[part 8 of 10: packages /System to /SoftwareComponents/CompositionSWComponents]
AUTOSAR XML (schema 00053)
package /System  (continued)
  system System  (continued)
    system mapping System_MPPNG  (continued)
      data-mappings:  (continued)
        sender-receiver-to-signal-group-mapping={data-element=Pp_SG_RadarHeader_ALPCAN.Vdp_SG_RadarHeader_ALPCAN, signal-group=SG_RadarHeader, type-mapping=sender-rec-record-type-mapping=record-element-mappings=[{application-record-element=HED_ALIGN_HOR_REF, system-signal=HED_ALIGN_HOR_REF}, {application-record-element=HED_ALIGN_VER_REF, system-signal=HED_ALIGN_VER_REF}, {application-record-element=HED_Auth_CRC32, system-signal=HED_Auth_CRC32}, {application-record-element=HED_DATA_QUALIFIER, system-signal=HED_DATA_QUALIFIER}, {application-record-element=HED_DET_BI_STATIC_COUNT, system-signal=HED_DET_BI_STATIC_COUNT}, {application-record-element=HED_DET_NUM_OF_1PASS, system-signal=HED_DET_NUM_OF_1PASS}, {application-record-element=HED_DET_NUM_OF_2PASS, system-signal=HED_DET_NUM_OF_2PASS}, {application-record-element=HED_DET_RANGE_MAX, system-signal=HED_DET_RANGE_MAX}, {application-record-element=HED_DET_RANGE_MIN, system-signal=HED_DET_RANGE_MIN}, {application-record-element=HED_DET_SPEED_RANGE_MAX, system-signal=HED_DET_SPEED_RANGE_MAX}, {application-record-element=HED_DET_SPEED_RANGE_MIN, system-signal=HED_DET_SPEED_RANGE_MIN}, {application-record-element=HED_FOV_HOR_MAX, system-signal=HED_FOV_HOR_MAX}, {application-record-element=HED_FOV_HOR_MIN, system-signal=HED_FOV_HOR_MIN}, {application-record-element=HED_FOV_VER_MAX, system-signal=HED_FOV_VER_MAX}, {application-record-element=HED_FOV_VER_MIN, system-signal=HED_FOV_VER_MIN}, {application-record-element=HED_LOOK_ID, system-signal=HED_LOOK_ID}, {application-record-element=HED_LOOK_INDEX, system-signal=HED_LOOK_INDEX}, {application-record-element=HED_MAX_NUM_OF_DETECTIONS, system-signal=HED_MAX_NUM_OF_DETECTIONS}, {application-record-element=HED_MH_CRC16, system-signal=HED_MH_CRC16}, {application-record-element=HED_MH_CYCLE_COUNTER, system-signal=HED_MH_CYCLE_COUNTER}, {application-record-element=HED_NUM_OF_RESTBINS_USED, system-signal=HED_NUM_OF_RESTBINS_USED}, {application-record-element=HED_NUM_OF_VALID_DETECTIONS, system-signal=HED_NUM_OF_VALID_DETECTIONS}, {application-record-element=HED_OPERATION_MODE, system-signal=HED_OPERATION_MODE}, {application-record-element=HED_PROCESSED_RANGE, system-signal=HED_PROCESSED_RANGE}, {application-record-element=HED_RDR_HEADER_CMAC, system-signal=HED_RDR_HEADER_CMAC}, {application-record-element=HED_RDR_HEADER_FV, system-signal=HED_RDR_HEADER_FV}, {application-record-element=HED_R_WRAPPING, system-signal=HED_R_WRAPPING}, {application-record-element=HED_Rain_Level, system-signal=HED_Rain_Level}, {application-record-element=HED_SCAN_INDEX, system-signal=HED_SCAN_INDEX}, {application-record-element=HED_SENSOR_TIME_STAMP_NS, system-signal=HED_SENSOR_TIME_STAMP_NS}, {application-record-element=HED_SENSOR_TIME_STAMP_SEC, system-signal=HED_SENSOR_TIME_STAMP_SEC}, {application-record-element=HED_SLOPE_CORR_EXECUTIONFLAG, system-signal=HED_SLOPE_CORR_EXECUTIONFLAG}, {application-record-element=HED_TIME_SYNC_SRC_MASTER, system-signal=HED_TIME_SYNC_SRC_MASTER}, {application-record-element=HED_TIME_SYNC_VALIDITY_FLAG, system-signal=HED_TIME_SYNC_VALIDITY_FLAG}, {application-record-element=HED_TRIGGER_TIME, system-signal=HED_TRIGGER_TIME}, {application-record-element=HED_V_WRAPPING, system-signal=HED_V_WRAPPING}]}
        sender-receiver-to-signal-group-mapping={data-element=Pp_SG_RadarStatus1_ALPCAN.Vdp_SG_RadarStatus1_ALPCAN, signal-group=SG_RadarStatus1, type-mapping=sender-rec-record-type-mapping=record-element-mappings=[{application-record-element=STS_AF_TIME_INST, system-signal=STS_AF_TIME_INST}, {application-record-element=STS_AF_TIME_PEAK, system-signal=STS_AF_TIME_PEAK}, {application-record-element=STS_DET_DBC_BASE_VER_MAJOR, system-signal=STS_DET_DBC_BASE_VER_MAJOR}, {application-record-element=STS_DET_DBC_BASE_VER_MINOR, system-signal=STS_DET_DBC_BASE_VER_MINOR}, {application-record-element=STS_DIST_FRNT_BMPR_TO_RR_AXL, system-signal=STS_DIST_FRNT_BMPR_TO_RR_AXL}, {application-record-element=STS_HARDWARE_VERSION, system-signal=STS_HARDWARE_VERSION}, {application-record-element=STS_MAIN_CORE_TIME_INST, system-signal=STS_MAIN_CORE_TIME_INST}, {application-record-element=STS_MAIN_CORE_TIME_PEAK, system-signal=STS_MAIN_CORE_TIME_PEAK}, {application-record-element=STS_MH_001_CRC16, system-signal=STS_MH_001_CRC16}, {application-record-element=STS_MH_001_CYCLE_COUNTER, system-signal=STS_MH_001_CYCLE_COUNTER}, {application-record-element=STS_PBL_VERSION_FIELD1, system-signal=STS_PBL_VERSION_FIELD1}, {application-record-element=STS_PBL_VERSION_FIELD2, system-signal=STS_PBL_VERSION_FIELD2}, {application-record-element=STS_PBL_VERSION_FIELD3, system-signal=STS_PBL_VERSION_FIELD3}, {application-record-element=STS_PBL_VERSION_FIELD4, system-signal=STS_PBL_VERSION_FIELD4}, {application-record-element=STS_PCAN_PROTOCOL_VER_MAJOR, system-signal=STS_PCAN_PROTOCOL_VER_MAJOR}, {application-record-element=STS_PCAN_PROTOCOL_VER_MINOR, system-signal=STS_PCAN_PROTOCOL_VER_MINOR}, {application-record-element=STS_PLATFORM_VARIANT, system-signal=STS_PLATFORM_VARIANT}, {application-record-element=STS_RDD_CORE_TIME_INST, system-signal=STS_RDD_CORE_TIME_INST}, {application-record-element=STS_RDD_CORE_TIME_PEAK, system-signal=STS_RDD_CORE_TIME_PEAK}, {application-record-element=STS_SENSOR_HEIGHT, system-signal=STS_SENSOR_HEIGHT}, {application-record-element=STS_SENSOR_MOUNT_ORNT_PITCH, system-signal=STS_SENSOR_MOUNT_ORNT_PITCH}, {application-record-element=STS_SENSOR_MOUNT_ORNT_ROLL, system-signal=STS_SENSOR_MOUNT_ORNT_ROLL}, {application-record-element=STS_SENSOR_MOUNT_ORNT_YAW, system-signal=STS_SENSOR_MOUNT_ORNT_YAW}, {application-record-element=STS_SENSOR_MOUNT_POS_X, system-signal=STS_SENSOR_MOUNT_POS_X}, {application-record-element=STS_SENSOR_MOUNT_POS_Y, system-signal=STS_SENSOR_MOUNT_POS_Y}, {application-record-element=STS_SENSOR_MOUNT_POS_Z, system-signal=STS_SENSOR_MOUNT_POS_Z}, {application-record-element=STS_SENSOR_POLARITY, system-signal=STS_SENSOR_POLARITY}, {application-record-element=STS_SENSOR_POSITION, system-signal=STS_SENSOR_POSITION}, {application-record-element=STS_SERIAL_NUMBER_SEQUENCE, system-signal=STS_SERIAL_NUMBER_SEQUENCE}, {application-record-element=STS_SERIAL_NUM_JULIAN_DAY, system-signal=STS_SERIAL_NUM_JULIAN_DAY}, {application-record-element=STS_SERIAL_NUM_JULIAN_YEAR, system-signal=STS_SERIAL_NUM_JULIAN_YEAR}, {application-record-element=STS_SMC_CAL_VER_MAJOR, system-signal=STS_SMC_CAL_VER_MAJOR}, {application-record-element=STS_SMC_CAL_VER_MINOR, system-signal=STS_SMC_CAL_VER_MINOR}, {application-record-element=STS_SMC_PLATFROM_VERSION, system-signal=STS_SMC_PLATFROM_VERSION}, {application-record-element=STS_SMC_SECTION_COMPTBLITY, system-signal=STS_SMC_SECTION_COMPTBLITY}, {application-record-element=STS_SP_CORE_TIME_INST, system-signal=STS_SP_CORE_TIME_INST}, {application-record-element=STS_SP_CORE_TIME_PEAK, system-signal=STS_SP_CORE_TIME_PEAK}, {application-record-element=STS_SW_VERSION_FIELD1, system-signal=STS_SW_VERSION_FIELD1}, {application-record-element=STS_SW_VERSION_FIELD2, system-signal=STS_SW_VERSION_FIELD2}, {application-record-element=STS_SW_VERSION_FIELD3, system-signal=STS_SW_VERSION_FIELD3}, {application-record-element=STS_SW_VERSION_FIELD4, system-signal=STS_SW_VERSION_FIELD4}, {application-record-element=STS_TIME_SINCE_POWER_ON, system-signal=STS_TIME_SINCE_POWER_ON}, {application-record-element=STS_USC_CAL_VER_MAJOR, system-signal=STS_USC_CAL_VER_MAJOR}, {application-record-element=STS_USC_CAL_VER_MINOR, system-signal=STS_USC_CAL_VER_MINOR}, {application-record-element=STS_USC_SECTION_COMPTBLITY, system-signal=STS_USC_SECTION_COMPTBLITY}, {application-record-element=STS_VIN_Status, system-signal=STS_VIN_Status}]}
      sw-mappings:
        swc to ecu mapping ECUMapping2: component=RootComposition, ecu-instance=RDR
    root-software-compositions:
      root sw composition prototype RootComposition: software-composition=ECU_Composition
package /SoftwareComponents/CompositionSWComponents
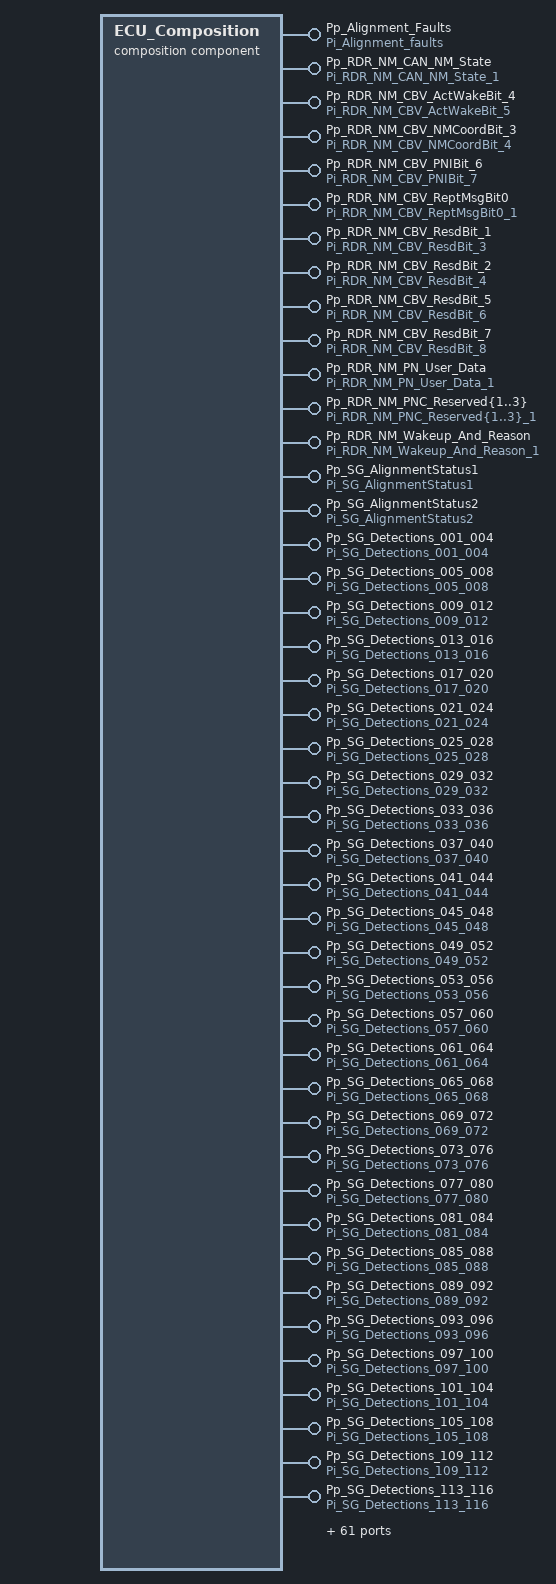
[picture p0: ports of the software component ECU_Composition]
  composition sw component type ECU_Composition
    189 x provide port:
      Pp_Alignment_Faults: nonqueued-sender-com-spec{data-element=De_Alignment_Faults, init-value=constant-reference=C_Alignment_faults}, provided-interface=Pi_Alignment_faults
      Pp_RDR_NM_CAN_NM_State: nonqueued-sender-com-spec{data-element=Vdp_RDR_NM_CAN_NM_State, init-value=0}, provided-interface=Pi_RDR_NM_CAN_NM_State_1
      Pp_RDR_NM_CBV_ActWakeBit_4: nonqueued-sender-com-spec{data-element=Vdp_RDR_NM_CBV_ActWakeBit_4, init-value=0}, provided-interface=Pi_RDR_NM_CBV_ActWakeBit_5
      Pp_RDR_NM_CBV_NMCoordBit_3: nonqueued-sender-com-spec{data-element=Vdp_RDR_NM_CBV_NMCoordBit_3, init-value=0}, provided-interface=Pi_RDR_NM_CBV_NMCoordBit_4
      Pp_RDR_NM_CBV_PNIBit_6: nonqueued-sender-com-spec{data-element=Vdp_RDR_NM_CBV_PNIBit_6, init-value=0}, provided-interface=Pi_RDR_NM_CBV_PNIBit_7
      Pp_RDR_NM_CBV_ReptMsgBit0: nonqueued-sender-com-spec{data-element=Vdp_RDR_NM_CBV_ReptMsgBit0, init-value=0}, provided-interface=Pi_RDR_NM_CBV_ReptMsgBit0_1
      Pp_RDR_NM_CBV_ResdBit_1: nonqueued-sender-com-spec{data-element=Vdp_RDR_NM_CBV_ResdBit_1, init-value=0}, provided-interface=Pi_RDR_NM_CBV_ResdBit_3
      Pp_RDR_NM_CBV_ResdBit_2: nonqueued-sender-com-spec{data-element=Vdp_RDR_NM_CBV_ResdBit_2, init-value=0}, provided-interface=Pi_RDR_NM_CBV_ResdBit_4
      Pp_RDR_NM_CBV_ResdBit_5: nonqueued-sender-com-spec{data-element=Vdp_RDR_NM_CBV_ResdBit_5, init-value=0}, provided-interface=Pi_RDR_NM_CBV_ResdBit_6
      Pp_RDR_NM_CBV_ResdBit_7: nonqueued-sender-com-spec{data-element=Vdp_RDR_NM_CBV_ResdBit_7, init-value=0}, provided-interface=Pi_RDR_NM_CBV_ResdBit_8
      Pp_RDR_NM_PN_User_Data: nonqueued-sender-com-spec{data-element=Vdp_RDR_NM_PN_User_Data, init-value=0}, provided-interface=Pi_RDR_NM_PN_User_Data_1
      Pp_RDR_NM_PNC_Reserved{1..3}: nonqueued-sender-com-spec{data-element=Vdp_RDR_NM_PNC_Reserved{1..3}, init-value=0}, provided-interface=Pi_RDR_NM_PNC_Reserved{1..3}_1
      Pp_RDR_NM_Wakeup_And_Reason: nonqueued-sender-com-spec{data-element=Vdp_RDR_NM_Wakeup_And_Reason, init-value=0}, provided-interface=Pi_RDR_NM_Wakeup_And_Reason_1
      Pp_SG_AlignmentStatus1: nonqueued-sender-com-spec{data-element=Vdp_SG_AlignmentStatus1, init-value=fields=[AL_STS_001_CYCLE_COUNTER:0, AL_STS_001_MH_CRC16:0, STS_AAAzimuthStd:0, STS_AACurrentAzimuth:0, STS_AACurrentElevation:0, STS_AAElevationStd:0, STS_AlignmentAutoStatus:0, STS_AlignmentAzimuth:0, STS_AlignmentElevation:0, STS_AlignmentError:0, STS_AlignmentModeIn:0, STS_AlignmentModeOut:0, STS_AutoAlignmentFailRootCause:5, STS_AzimuthErrorNegative:0, STS_AzimuthErrorPositive:0, STS_AzimuthStd:0, STS_AzimuthUpdates:0, STS_CalDisplay:0, STS_CalTime:0, STS_CoordinateSystemInput:0, STS_ElevationErrorNegative:0, STS_ElevationErrorPositive:0, STS_ElevationStd:0, STS_ElevationUpdates:0, STS_HostSpdCompensationFactorQF:0, STS_HostSpeedCompensationFactor:100, 0, 0, 0, 0, 100, 0, STS_ProgressPercent:0, STS_RadarTypeInput:0, STS_RollErrorPositive:0, STS_StartAzimuth:0, STS_StartElevation:0]}, provided-interface=Pi_SG_AlignmentStatus1
      Pp_SG_AlignmentStatus2: nonqueued-sender-com-spec{data-element=Vdp_SG_AlignmentStatus2, init-value=fields=[AL_STS_002_CYCLE_COUNTER:0, AL_STS_002_MH_CRC16:0, STS_AlignmentServiceStatus:0, STS_AlignmentShortTrackStatus:0, STS_AlignmentStaticStatus:0, STS_AverageNumberOfDetections:0, STS_AverageSpeed:0, STS_DistanceAbsolute:0, STS_DistanceEffective:0, STS_DurationAbsolute:0, STS_DurationEffective:0, STS_ImpactByInterference:0, STS_Measured_Range:1200, STS_MeasuredRangeRate:0, STS_MeasuredRangeRateStd:0, STS_MeasuredRangeStd:0, STS_MeasuredRCS:0, STS_MeasuredRCSStd:0, STS_VehicleCondition:6]}, provided-interface=Pi_SG_AlignmentStatus2
      Pp_SG_Detections_001_004: nonqueued-sender-com-spec{data-element=Vdp_SG_Detections_001_004, init-value=fields=[DET_AZIMUTH_001:0, DET_AZIMUTH_002:0, DET_AZIMUTH_003:0, DET_AZIMUTH_004:0, DET_AZIMUTH_ERR_001:0, DET_AZIMUTH_ERR_002:0, DET_AZIMUTH_ERR_003:0, DET_AZIMUTH_ERR_004:0, DET_BI_STATIC_FLAG_001:0, DET_BI_STATIC_FLAG_002:0, DET_BI_STATIC_FLAG_003:0, DET_BI_STATIC_FLAG_004:0, DET_CONFD_AZIMUTH_001:0, DET_CONFD_AZIMUTH_002:0, DET_CONFD_AZIMUTH_003:0, DET_CONFD_AZIMUTH_004:0, DET_CONFD_ELEVATION_001:0, DET_CONFD_ELEVATION_002:0, DET_CONFD_ELEVATION_003:0, DET_CONFD_ELEVATION_004:0, DET_ELEVATION_001:0, DET_ELEVATION_002:0, DET_ELEVATION_003:0, DET_ELEVATION_004:0, DET_ELEVATION_ERR_001:0, DET_ELEVATION_ERR_002:0, DET_ELEVATION_ERR_003:0, DET_ELEVATION_ERR_004:0, DET_EXISTENCE_PROB_001:0, DET_EXISTENCE_PROB_002:0, DET_EXISTENCE_PROB_003:0, DET_EXISTENCE_PROB_004:0, DET_HVC_FLAG_001:0, DET_HVC_FLAG_002:0, DET_HVC_FLAG_003:0, DET_HVC_FLAG_004:0, DET_MH_CRC16_001_004:0, DET_MH_CYCLE_COUNTER_001_004:0, DET_MH_SCAN_INDEX_4LSB_001_004:0, DET_OUTSIDE_SECTOR_001:0, DET_OUTSIDE_SECTOR_002:0, DET_OUTSIDE_SECTOR_003:0, DET_OUTSIDE_SECTOR_004:0, DET_POINT_TARGET_PROB_001:0, DET_POINT_TARGET_PROB_002:0, DET_POINT_TARGET_PROB_003:0, DET_POINT_TARGET_PROB_004:0, DET_RANGE_001:0, DET_RANGE_002:0, DET_RANGE_003:0, DET_RANGE_004:0, DET_RANGE_ERR_001:0, DET_RANGE_ERR_002:0, DET_RANGE_ERR_003:0, DET_RANGE_ERR_004:0, DET_RANGE_VELOCITY_001:16384, DET_RANGE_VELOCITY_002:16384, DET_RANGE_VELOCITY_003:16384, DET_RANGE_VELOCITY_004:16384, DET_RANGE_VELOCITY_ERR_001:0, DET_RANGE_VELOCITY_ERR_002:0, DET_RANGE_VELOCITY_ERR_003:0, DET_RANGE_VELOCITY_ERR_004:0, DET_RCS_001:128, DET_RCS_002:128, DET_RCS_003:128, DET_RCS_004:128, DET_SNR_001:0, DET_SNR_002:0, DET_SNR_003:0, DET_SNR_004:0, DET_SUPER_RES_TARGET_001:0, DET_SUPER_RES_TARGET_002:0, DET_SUPER_RES_TARGET_003:0, DET_SUPER_RES_TARGET_004:0, DET_VALID_FLAG_001:0, DET_VALID_FLAG_002:0, DET_VALID_FLAG_003:0, DET_VALID_FLAG_004:0]}, provided-interface=Pi_SG_Detections_001_004
      Pp_SG_Detections_005_008: nonqueued-sender-com-spec{data-element=Vdp_SG_Detections_005_008, init-value=fields=[DET_AZIMUTH_005:0, DET_AZIMUTH_006:0, DET_AZIMUTH_007:0, DET_AZIMUTH_008:0, DET_AZIMUTH_ERR_005:0, DET_AZIMUTH_ERR_006:0, DET_AZIMUTH_ERR_007:0, DET_AZIMUTH_ERR_008:0, DET_BI_STATIC_FLAG_005:0, DET_BI_STATIC_FLAG_006:0, DET_BI_STATIC_FLAG_007:0, DET_BI_STATIC_FLAG_008:0, DET_CONFD_AZIMUTH_005:0, DET_CONFD_AZIMUTH_006:0, DET_CONFD_AZIMUTH_007:0, DET_CONFD_AZIMUTH_008:0, DET_CONFD_ELEVATION_005:0, DET_CONFD_ELEVATION_006:0, DET_CONFD_ELEVATION_007:0, DET_CONFD_ELEVATION_008:0, DET_ELEVATION_005:0, DET_ELEVATION_006:0, DET_ELEVATION_007:0, DET_ELEVATION_008:0, DET_ELEVATION_ERR_005:0, DET_ELEVATION_ERR_006:0, DET_ELEVATION_ERR_007:0, DET_ELEVATION_ERR_008:0, DET_EXISTENCE_PROB_005:0, DET_EXISTENCE_PROB_006:0, DET_EXISTENCE_PROB_007:0, DET_EXISTENCE_PROB_008:0, DET_HVC_FLAG_005:0, DET_HVC_FLAG_006:0, DET_HVC_FLAG_007:0, DET_HVC_FLAG_008:0, DET_MH_CRC16_005_008:0, DET_MH_CYCLE_COUNTER_005_008:0, DET_MH_SCAN_INDEX_4LSB_005_008:0, DET_OUTSIDE_SECTOR_005:0, DET_OUTSIDE_SECTOR_006:0, DET_OUTSIDE_SECTOR_007:0, DET_OUTSIDE_SECTOR_008:0, DET_POINT_TARGET_PROB_005:0, DET_POINT_TARGET_PROB_006:0, DET_POINT_TARGET_PROB_007:0, DET_POINT_TARGET_PROB_008:0, DET_RANGE_005:0, DET_RANGE_006:0, DET_RANGE_007:0, DET_RANGE_008:0, DET_RANGE_ERR_005:0, DET_RANGE_ERR_006:0, DET_RANGE_ERR_007:0, DET_RANGE_ERR_008:0, DET_RANGE_VELOCITY_005:16384, DET_RANGE_VELOCITY_006:16384, DET_RANGE_VELOCITY_007:16384, DET_RANGE_VELOCITY_008:16384, DET_RANGE_VELOCITY_ERR_005:0, DET_RANGE_VELOCITY_ERR_006:0, DET_RANGE_VELOCITY_ERR_007:0, DET_RANGE_VELOCITY_ERR_008:0, DET_RCS_005:128, DET_RCS_006:128, DET_RCS_007:128, DET_RCS_008:128, DET_SNR_005:0, DET_SNR_006:0, DET_SNR_007:0, DET_SNR_008:0, DET_SUPER_RES_TARGET_005:0, DET_SUPER_RES_TARGET_006:0, DET_SUPER_RES_TARGET_007:0, DET_SUPER_RES_TARGET_008:0, DET_VALID_FLAG_005:0, DET_VALID_FLAG_006:0, DET_VALID_FLAG_007:0, DET_VALID_FLAG_008:0]}, provided-interface=Pi_SG_Detections_005_008
      Pp_SG_Detections_009_012: nonqueued-sender-com-spec{data-element=Vdp_SG_Detections_009_012, init-value=fields=[DET_AZIMUTH_009:0, DET_AZIMUTH_010:0, DET_AZIMUTH_011:0, DET_AZIMUTH_012:0, DET_AZIMUTH_ERR_009:0, DET_AZIMUTH_ERR_010:0, DET_AZIMUTH_ERR_011:0, DET_AZIMUTH_ERR_012:0, DET_BI_STATIC_FLAG_009:0, DET_BI_STATIC_FLAG_010:0, DET_BI_STATIC_FLAG_011:0, DET_BI_STATIC_FLAG_012:0, DET_CONFD_AZIMUTH_009:0, DET_CONFD_AZIMUTH_010:0, DET_CONFD_AZIMUTH_011:0, DET_CONFD_AZIMUTH_012:0, DET_CONFD_ELEVATION_009:0, DET_CONFD_ELEVATION_010:0, DET_CONFD_ELEVATION_011:0, DET_CONFD_ELEVATION_012:0, DET_ELEVATION_009:0, DET_ELEVATION_010:0, DET_ELEVATION_011:0, DET_ELEVATION_012:0, DET_ELEVATION_ERR_009:0, DET_ELEVATION_ERR_010:0, DET_ELEVATION_ERR_011:0, DET_ELEVATION_ERR_012:0, DET_EXISTENCE_PROB_009:0, DET_EXISTENCE_PROB_010:0, DET_EXISTENCE_PROB_011:0, DET_EXISTENCE_PROB_012:0, DET_HVC_FLAG_009:0, DET_HVC_FLAG_010:0, DET_HVC_FLAG_011:0, DET_HVC_FLAG_012:0, DET_MH_CRC16_009_012:0, DET_MH_CYCLE_COUNTER_009_012:0, DET_MH_SCAN_INDEX_4LSB_009_012:0, DET_OUTSIDE_SECTOR_009:0, DET_OUTSIDE_SECTOR_010:0, DET_OUTSIDE_SECTOR_011:0, DET_OUTSIDE_SECTOR_012:0, DET_POINT_TARGET_PROB_009:0, DET_POINT_TARGET_PROB_010:0, DET_POINT_TARGET_PROB_011:0, DET_POINT_TARGET_PROB_012:0, DET_RANGE_009:0, DET_RANGE_010:0, DET_RANGE_011:0, DET_RANGE_012:0, DET_RANGE_ERR_009:0, DET_RANGE_ERR_010:0, DET_RANGE_ERR_011:0, DET_RANGE_ERR_012:0, DET_RANGE_VELOCITY_009:16384, DET_RANGE_VELOCITY_010:16384, DET_RANGE_VELOCITY_011:16384, DET_RANGE_VELOCITY_012:16384, DET_RANGE_VELOCITY_ERR_009:0, DET_RANGE_VELOCITY_ERR_010:0, DET_RANGE_VELOCITY_ERR_011:0, DET_RANGE_VELOCITY_ERR_012:0, DET_RCS_009:128, DET_RCS_010:128, DET_RCS_011:128, DET_RCS_012:128, DET_SNR_009:0, DET_SNR_010:0, DET_SNR_011:0, DET_SNR_012:0, DET_SUPER_RES_TARGET_009:0, DET_SUPER_RES_TARGET_010:0, DET_SUPER_RES_TARGET_011:0, DET_SUPER_RES_TARGET_012:0, DET_VALID_FLAG_009:0, DET_VALID_FLAG_010:0, DET_VALID_FLAG_011:0, DET_VALID_FLAG_012:0]}, provided-interface=Pi_SG_Detections_009_012
      Pp_SG_Detections_013_016: nonqueued-sender-com-spec{data-element=Vdp_SG_Detections_013_016, init-value=fields=[DET_AZIMUTH_013:0, DET_AZIMUTH_014:0, DET_AZIMUTH_015:0, DET_AZIMUTH_016:0, DET_AZIMUTH_ERR_013:0, DET_AZIMUTH_ERR_014:0, DET_AZIMUTH_ERR_015:0, DET_AZIMUTH_ERR_016:0, DET_BI_STATIC_FLAG_013:0, DET_BI_STATIC_FLAG_014:0, DET_BI_STATIC_FLAG_015:0, DET_BI_STATIC_FLAG_016:0, DET_CONFD_AZIMUTH_013:0, DET_CONFD_AZIMUTH_014:0, DET_CONFD_AZIMUTH_015:0, DET_CONFD_AZIMUTH_016:0, DET_CONFD_ELEVATION_013:0, DET_CONFD_ELEVATION_014:0, DET_CONFD_ELEVATION_015:0, DET_CONFD_ELEVATION_016:0, DET_ELEVATION_013:0, DET_ELEVATION_014:0, DET_ELEVATION_015:0, DET_ELEVATION_016:0, DET_ELEVATION_ERR_013:0, DET_ELEVATION_ERR_014:0, DET_ELEVATION_ERR_015:0, DET_ELEVATION_ERR_016:0, DET_EXISTENCE_PROB_013:0, DET_EXISTENCE_PROB_014:0, DET_EXISTENCE_PROB_015:0, DET_EXISTENCE_PROB_016:0, DET_HVC_FLAG_013:0, DET_HVC_FLAG_014:0, DET_HVC_FLAG_015:0, DET_HVC_FLAG_016:0, DET_MH_CRC16_013_016:0, DET_MH_CYCLE_COUNTER_013_016:0, DET_MH_SCAN_INDEX_4LSB_013_016:0, DET_OUTSIDE_SECTOR_013:0, DET_OUTSIDE_SECTOR_014:0, DET_OUTSIDE_SECTOR_015:0, DET_OUTSIDE_SECTOR_016:0, DET_POINT_TARGET_PROB_013:0, DET_POINT_TARGET_PROB_014:0, DET_POINT_TARGET_PROB_015:0, DET_POINT_TARGET_PROB_016:0, DET_RANGE_013:0, DET_RANGE_014:0, DET_RANGE_015:0, DET_RANGE_016:0, DET_RANGE_ERR_013:0, DET_RANGE_ERR_014:0, DET_RANGE_ERR_015:0, DET_RANGE_ERR_016:0, DET_RANGE_VELOCITY_013:16384, DET_RANGE_VELOCITY_014:16384, DET_RANGE_VELOCITY_015:16384, DET_RANGE_VELOCITY_016:16384, DET_RANGE_VELOCITY_ERR_013:0, DET_RANGE_VELOCITY_ERR_014:0, DET_RANGE_VELOCITY_ERR_015:0, DET_RANGE_VELOCITY_ERR_016:0, DET_RCS_013:128, DET_RCS_014:128, DET_RCS_015:128, DET_RCS_016:128, DET_SNR_013:0, DET_SNR_014:0, DET_SNR_015:0, DET_SNR_016:0, DET_SUPER_RES_TARGET_013:0, DET_SUPER_RES_TARGET_014:0, DET_SUPER_RES_TARGET_015:0, DET_SUPER_RES_TARGET_016:0, DET_VALID_FLAG_013:0, DET_VALID_FLAG_014:0, DET_VALID_FLAG_015:0, DET_VALID_FLAG_016:0]}, provided-interface=Pi_SG_Detections_013_016
      Pp_SG_Detections_017_020: nonqueued-sender-com-spec{data-element=Vdp_SG_Detections_017_020, init-value=fields=[DET_AZIMUTH_017:0, DET_AZIMUTH_018:0, DET_AZIMUTH_019:0, DET_AZIMUTH_020:0, DET_AZIMUTH_ERR_017:0, DET_AZIMUTH_ERR_018:0, DET_AZIMUTH_ERR_019:0, DET_AZIMUTH_ERR_020:0, DET_BI_STATIC_FLAG_017:0, DET_BI_STATIC_FLAG_018:0, DET_BI_STATIC_FLAG_019:0, DET_BI_STATIC_FLAG_020:0, DET_CONFD_AZIMUTH_017:0, DET_CONFD_AZIMUTH_018:0, DET_CONFD_AZIMUTH_019:0, DET_CONFD_AZIMUTH_020:0, DET_CONFD_ELEVATION_017:0, DET_CONFD_ELEVATION_018:0, DET_CONFD_ELEVATION_019:0, DET_CONFD_ELEVATION_020:0, DET_ELEVATION_017:0, DET_ELEVATION_018:0, DET_ELEVATION_019:0, DET_ELEVATION_020:0, DET_ELEVATION_ERR_017:0, DET_ELEVATION_ERR_018:0, DET_ELEVATION_ERR_019:0, DET_ELEVATION_ERR_020:0, DET_EXISTENCE_PROB_017:0, DET_EXISTENCE_PROB_018:0, DET_EXISTENCE_PROB_019:0, DET_EXISTENCE_PROB_020:0, DET_HVC_FLAG_017:0, DET_HVC_FLAG_018:0, DET_HVC_FLAG_019:0, DET_HVC_FLAG_020:0, DET_MH_CRC16_017_020:0, DET_MH_CYCLE_COUNTER_017_020:0, DET_MH_SCAN_INDEX_4LSB_017_020:0, DET_OUTSIDE_SECTOR_017:0, DET_OUTSIDE_SECTOR_018:0, DET_OUTSIDE_SECTOR_019:0, DET_OUTSIDE_SECTOR_020:0, DET_POINT_TARGET_PROB_017:0, DET_POINT_TARGET_PROB_018:0, DET_POINT_TARGET_PROB_019:0, DET_POINT_TARGET_PROB_020:0, DET_RANGE_017:0, DET_RANGE_018:0, DET_RANGE_019:0, DET_RANGE_020:0, DET_RANGE_ERR_017:0, DET_RANGE_ERR_018:0, DET_RANGE_ERR_019:0, DET_RANGE_ERR_020:0, DET_RANGE_VELOCITY_017:16384, DET_RANGE_VELOCITY_018:16384, DET_RANGE_VELOCITY_019:16384, DET_RANGE_VELOCITY_020:16384, DET_RANGE_VELOCITY_ERR_017:0, DET_RANGE_VELOCITY_ERR_018:0, DET_RANGE_VELOCITY_ERR_019:0, DET_RANGE_VELOCITY_ERR_020:0, DET_RCS_017:128, DET_RCS_018:128, DET_RCS_019:128, DET_RCS_020:128, DET_SNR_017:0, DET_SNR_018:0, DET_SNR_019:0, DET_SNR_020:0, DET_SUPER_RES_TARGET_017:0, DET_SUPER_RES_TARGET_018:0, DET_SUPER_RES_TARGET_019:0, DET_SUPER_RES_TARGET_020:0, DET_VALID_FLAG_017:0, DET_VALID_FLAG_018:0, DET_VALID_FLAG_019:0, DET_VALID_FLAG_020:0]}, provided-interface=Pi_SG_Detections_017_020
      Pp_SG_Detections_021_024: nonqueued-sender-com-spec{data-element=Vdp_SG_Detections_021_024, init-value=fields=[DET_AZIMUTH_021:0, DET_AZIMUTH_022:0, DET_AZIMUTH_023:0, DET_AZIMUTH_024:0, DET_AZIMUTH_ERR_021:0, DET_AZIMUTH_ERR_022:0, DET_AZIMUTH_ERR_023:0, DET_AZIMUTH_ERR_024:0, DET_BI_STATIC_FLAG_021:0, DET_BI_STATIC_FLAG_022:0, DET_BI_STATIC_FLAG_023:0, DET_BI_STATIC_FLAG_024:0, DET_CONFD_AZIMUTH_021:0, DET_CONFD_AZIMUTH_022:0, DET_CONFD_AZIMUTH_023:0, DET_CONFD_AZIMUTH_024:0, DET_CONFD_ELEVATION_021:0, DET_CONFD_ELEVATION_022:0, DET_CONFD_ELEVATION_023:0, DET_CONFD_ELEVATION_024:0, DET_ELEVATION_021:0, DET_ELEVATION_022:0, DET_ELEVATION_023:0, DET_ELEVATION_024:0, DET_ELEVATION_ERR_021:0, DET_ELEVATION_ERR_022:0, DET_ELEVATION_ERR_023:0, DET_ELEVATION_ERR_024:0, DET_EXISTENCE_PROB_021:0, DET_EXISTENCE_PROB_022:0, DET_EXISTENCE_PROB_023:0, DET_EXISTENCE_PROB_024:0, DET_HVC_FLAG_021:0, DET_HVC_FLAG_022:0, DET_HVC_FLAG_023:0, DET_HVC_FLAG_024:0, DET_MH_CRC16_021_024:0, DET_MH_CYCLE_COUNTER_021_024:0, DET_MH_SCAN_INDEX_4LSB_021_024:0, DET_OUTSIDE_SECTOR_021:0, DET_OUTSIDE_SECTOR_022:0, DET_OUTSIDE_SECTOR_023:0, DET_OUTSIDE_SECTOR_024:0, DET_POINT_TARGET_PROB_021:0, DET_POINT_TARGET_PROB_022:0, DET_POINT_TARGET_PROB_023:0, DET_POINT_TARGET_PROB_024:0, DET_RANGE_021:0, DET_RANGE_022:0, DET_RANGE_023:0, DET_RANGE_024:0, DET_RANGE_ERR_021:0, DET_RANGE_ERR_022:0, DET_RANGE_ERR_023:0, DET_RANGE_ERR_024:0, DET_RANGE_VELOCITY_021:16384, DET_RANGE_VELOCITY_022:16384, DET_RANGE_VELOCITY_023:16384, DET_RANGE_VELOCITY_024:16384, DET_RANGE_VELOCITY_ERR_021:0, DET_RANGE_VELOCITY_ERR_022:0, DET_RANGE_VELOCITY_ERR_023:0, DET_RANGE_VELOCITY_ERR_024:0, DET_RCS_021:128, DET_RCS_022:128, DET_RCS_023:128, DET_RCS_024:128, DET_SNR_021:0, DET_SNR_022:0, DET_SNR_023:0, DET_SNR_024:0, DET_SUPER_RES_TARGET_021:0, DET_SUPER_RES_TARGET_022:0, DET_SUPER_RES_TARGET_023:0, DET_SUPER_RES_TARGET_024:0, DET_VALID_FLAG_021:0, DET_VALID_FLAG_022:0, DET_VALID_FLAG_023:0, DET_VALID_FLAG_024:0]}, provided-interface=Pi_SG_Detections_021_024
      Pp_SG_Detections_025_028: nonqueued-sender-com-spec{data-element=Vdp_SG_Detections_025_028, init-value=fields=[DET_AZIMUTH_025:0, DET_AZIMUTH_026:0, DET_AZIMUTH_027:0, DET_AZIMUTH_028:0, DET_AZIMUTH_ERR_025:0, DET_AZIMUTH_ERR_026:0, DET_AZIMUTH_ERR_027:0, DET_AZIMUTH_ERR_028:0, DET_BI_STATIC_FLAG_025:0, DET_BI_STATIC_FLAG_026:0, DET_BI_STATIC_FLAG_027:0, DET_BI_STATIC_FLAG_028:0, DET_CONFD_AZIMUTH_025:0, DET_CONFD_AZIMUTH_026:0, DET_CONFD_AZIMUTH_027:0, DET_CONFD_AZIMUTH_028:0, DET_CONFD_ELEVATION_025:0, DET_CONFD_ELEVATION_026:0, DET_CONFD_ELEVATION_027:0, DET_CONFD_ELEVATION_028:0, DET_ELEVATION_025:0, DET_ELEVATION_026:0, DET_ELEVATION_027:0, DET_ELEVATION_028:0, DET_ELEVATION_ERR_025:0, DET_ELEVATION_ERR_026:0, DET_ELEVATION_ERR_027:0, DET_ELEVATION_ERR_028:0, DET_EXISTENCE_PROB_025:0, DET_EXISTENCE_PROB_026:0, DET_EXISTENCE_PROB_027:0, DET_EXISTENCE_PROB_028:0, DET_HVC_FLAG_025:0, DET_HVC_FLAG_026:0, DET_HVC_FLAG_027:0, DET_HVC_FLAG_028:0, DET_MH_CRC16_025_028:0, DET_MH_CYCLE_COUNTER_025_028:0, DET_MH_SCAN_INDEX_4LSB_025_028:0, DET_OUTSIDE_SECTOR_025:0, DET_OUTSIDE_SECTOR_026:0, DET_OUTSIDE_SECTOR_027:0, DET_OUTSIDE_SECTOR_028:0, DET_POINT_TARGET_PROB_025:0, DET_POINT_TARGET_PROB_026:0, DET_POINT_TARGET_PROB_027:0, DET_POINT_TARGET_PROB_028:0, DET_RANGE_025:0, DET_RANGE_026:0, DET_RANGE_027:0, DET_RANGE_028:0, DET_RANGE_ERR_025:0, DET_RANGE_ERR_026:0, DET_RANGE_ERR_027:0, DET_RANGE_ERR_028:0, DET_RANGE_VELOCITY_025:16384, DET_RANGE_VELOCITY_026:16384, DET_RANGE_VELOCITY_027:16384, DET_RANGE_VELOCITY_028:16384, DET_RANGE_VELOCITY_ERR_025:0, DET_RANGE_VELOCITY_ERR_026:0, DET_RANGE_VELOCITY_ERR_027:0, DET_RANGE_VELOCITY_ERR_028:0, DET_RCS_025:128, DET_RCS_026:128, DET_RCS_027:128, DET_RCS_028:128, DET_SNR_025:0, DET_SNR_026:0, DET_SNR_027:0, DET_SNR_028:0, DET_SUPER_RES_TARGET_025:0, DET_SUPER_RES_TARGET_026:0, DET_SUPER_RES_TARGET_027:0, DET_SUPER_RES_TARGET_028:0, DET_VALID_FLAG_025:0, DET_VALID_FLAG_026:0, DET_VALID_FLAG_027:0, DET_VALID_FLAG_028:0]}, provided-interface=Pi_SG_Detections_025_028
      Pp_SG_Detections_029_032: nonqueued-sender-com-spec{data-element=Vdp_SG_Detections_029_032, init-value=fields=[DET_AZIMUTH_029:0, DET_AZIMUTH_030:0, DET_AZIMUTH_031:0, DET_AZIMUTH_032:0, DET_AZIMUTH_ERR_029:0, DET_AZIMUTH_ERR_030:0, DET_AZIMUTH_ERR_031:0, DET_AZIMUTH_ERR_032:0, DET_BI_STATIC_FLAG_029:0, DET_BI_STATIC_FLAG_030:0, DET_BI_STATIC_FLAG_031:0, DET_BI_STATIC_FLAG_032:0, DET_CONFD_AZIMUTH_029:0, DET_CONFD_AZIMUTH_030:0, DET_CONFD_AZIMUTH_031:0, DET_CONFD_AZIMUTH_032:0, DET_CONFD_ELEVATION_029:0, DET_CONFD_ELEVATION_030:0, DET_CONFD_ELEVATION_031:0, DET_CONFD_ELEVATION_032:0, DET_ELEVATION_029:0, DET_ELEVATION_030:0, DET_ELEVATION_031:0, DET_ELEVATION_032:0, DET_ELEVATION_ERR_029:0, DET_ELEVATION_ERR_030:0, DET_ELEVATION_ERR_031:0, DET_ELEVATION_ERR_032:0, DET_EXISTENCE_PROB_029:0, DET_EXISTENCE_PROB_030:0, DET_EXISTENCE_PROB_031:0, DET_EXISTENCE_PROB_032:0, DET_HVC_FLAG_029:0, DET_HVC_FLAG_030:0, DET_HVC_FLAG_031:0, DET_HVC_FLAG_032:0, DET_MH_CRC16_029_032:0, DET_MH_CYCLE_COUNTER_029_032:0, DET_MH_SCAN_INDEX_4LSB_029_032:0, DET_OUTSIDE_SECTOR_029:0, DET_OUTSIDE_SECTOR_030:0, DET_OUTSIDE_SECTOR_031:0, DET_OUTSIDE_SECTOR_032:0, DET_POINT_TARGET_PROB_029:0, DET_POINT_TARGET_PROB_030:0, DET_POINT_TARGET_PROB_031:0, DET_POINT_TARGET_PROB_032:0, DET_RANGE_029:0, DET_RANGE_030:0, DET_RANGE_031:0, DET_RANGE_032:0, DET_RANGE_ERR_029:0, DET_RANGE_ERR_030:0, DET_RANGE_ERR_031:0, DET_RANGE_ERR_032:0, DET_RANGE_VELOCITY_029:16384, DET_RANGE_VELOCITY_030:16384, DET_RANGE_VELOCITY_031:16384, DET_RANGE_VELOCITY_032:16384, DET_RANGE_VELOCITY_ERR_029:0, DET_RANGE_VELOCITY_ERR_030:0, DET_RANGE_VELOCITY_ERR_031:0, DET_RANGE_VELOCITY_ERR_032:0, DET_RCS_029:128, DET_RCS_030:128, DET_RCS_031:128, DET_RCS_032:128, DET_SNR_029:0, DET_SNR_030:0, DET_SNR_031:0, DET_SNR_032:0, DET_SUPER_RES_TARGET_029:0, DET_SUPER_RES_TARGET_030:0, DET_SUPER_RES_TARGET_031:0, DET_SUPER_RES_TARGET_032:0, DET_VALID_FLAG_029:0, DET_VALID_FLAG_030:0, DET_VALID_FLAG_031:0, DET_VALID_FLAG_032:0]}, provided-interface=Pi_SG_Detections_029_032
      Pp_SG_Detections_033_036: nonqueued-sender-com-spec{data-element=Vdp_SG_Detections_033_036, init-value=fields=[DET_AZIMUTH_033:0, DET_AZIMUTH_034:0, DET_AZIMUTH_035:0, DET_AZIMUTH_036:0, DET_AZIMUTH_ERR_033:0, DET_AZIMUTH_ERR_034:0, DET_AZIMUTH_ERR_035:0, DET_AZIMUTH_ERR_036:0, DET_BI_STATIC_FLAG_033:0, DET_BI_STATIC_FLAG_034:0, DET_BI_STATIC_FLAG_035:0, DET_BI_STATIC_FLAG_036:0, DET_CONFD_AZIMUTH_033:0, DET_CONFD_AZIMUTH_034:0, DET_CONFD_AZIMUTH_035:0, DET_CONFD_AZIMUTH_036:0, DET_CONFD_ELEVATION_033:0, DET_CONFD_ELEVATION_034:0, DET_CONFD_ELEVATION_035:0, DET_CONFD_ELEVATION_036:0, DET_ELEVATION_033:0, DET_ELEVATION_034:0, DET_ELEVATION_035:0, DET_ELEVATION_036:0, DET_ELEVATION_ERR_033:0, DET_ELEVATION_ERR_034:0, DET_ELEVATION_ERR_035:0, DET_ELEVATION_ERR_036:0, DET_EXISTENCE_PROB_033:0, DET_EXISTENCE_PROB_034:0, DET_EXISTENCE_PROB_035:0, DET_EXISTENCE_PROB_036:0, DET_HVC_FLAG_033:0, DET_HVC_FLAG_034:0, DET_HVC_FLAG_035:0, DET_HVC_FLAG_036:0, DET_MH_CRC16_033_036:0, DET_MH_CYCLE_COUNTER_033_036:0, DET_MH_SCAN_INDEX_4LSB_033_036:0, DET_OUTSIDE_SECTOR_033:0, DET_OUTSIDE_SECTOR_034:0, DET_OUTSIDE_SECTOR_035:0, DET_OUTSIDE_SECTOR_036:0, DET_POINT_TARGET_PROB_033:0, DET_POINT_TARGET_PROB_034:0, DET_POINT_TARGET_PROB_035:0, DET_POINT_TARGET_PROB_036:0, DET_RANGE_033:0, DET_RANGE_034:0, DET_RANGE_035:0, DET_RANGE_036:0, DET_RANGE_ERR_033:0, DET_RANGE_ERR_034:0, DET_RANGE_ERR_035:0, DET_RANGE_ERR_036:0, DET_RANGE_VELOCITY_033:16384, DET_RANGE_VELOCITY_034:16384, DET_RANGE_VELOCITY_035:16384, DET_RANGE_VELOCITY_036:16384, DET_RANGE_VELOCITY_ERR_033:0, DET_RANGE_VELOCITY_ERR_034:0, DET_RANGE_VELOCITY_ERR_035:0, DET_RANGE_VELOCITY_ERR_036:0, DET_RCS_033:128, DET_RCS_034:128, DET_RCS_035:128, DET_RCS_036:128, DET_SNR_033:0, DET_SNR_034:0, DET_SNR_035:0, DET_SNR_036:0, DET_SUPER_RES_TARGET_033:0, DET_SUPER_RES_TARGET_034:0, DET_SUPER_RES_TARGET_035:0, DET_SUPER_RES_TARGET_036:0, DET_VALID_FLAG_033:0, DET_VALID_FLAG_034:0, DET_VALID_FLAG_035:0, DET_VALID_FLAG_036:0]}, provided-interface=Pi_SG_Detections_033_036
      Pp_SG_Detections_037_040: nonqueued-sender-com-spec{data-element=Vdp_SG_Detections_037_040, init-value=fields=[DET_AZIMUTH_037:0, DET_AZIMUTH_038:0, DET_AZIMUTH_039:0, DET_AZIMUTH_040:0, DET_AZIMUTH_ERR_037:0, DET_AZIMUTH_ERR_038:0, DET_AZIMUTH_ERR_039:0, DET_AZIMUTH_ERR_040:0, DET_BI_STATIC_FLAG_037:0, DET_BI_STATIC_FLAG_038:0, DET_BI_STATIC_FLAG_039:0, DET_BI_STATIC_FLAG_040:0, DET_CONFD_AZIMUTH_037:0, DET_CONFD_AZIMUTH_038:0, DET_CONFD_AZIMUTH_039:0, DET_CONFD_AZIMUTH_040:0, DET_CONFD_ELEVATION_037:0, DET_CONFD_ELEVATION_038:0, DET_CONFD_ELEVATION_039:0, DET_CONFD_ELEVATION_040:0, DET_ELEVATION_037:0, DET_ELEVATION_038:0, DET_ELEVATION_039:0, DET_ELEVATION_040:0, DET_ELEVATION_ERR_037:0, DET_ELEVATION_ERR_038:0, DET_ELEVATION_ERR_039:0, DET_ELEVATION_ERR_040:0, DET_EXISTENCE_PROB_037:0, DET_EXISTENCE_PROB_038:0, DET_EXISTENCE_PROB_039:0, DET_EXISTENCE_PROB_040:0, DET_HVC_FLAG_037:0, DET_HVC_FLAG_038:0, DET_HVC_FLAG_039:0, DET_HVC_FLAG_040:0, DET_MH_CRC16_037_040:0, DET_MH_CYCLE_COUNTER_037_040:0, DET_MH_SCAN_INDEX_4LSB_037_040:0, DET_OUTSIDE_SECTOR_037:0, DET_OUTSIDE_SECTOR_038:0, DET_OUTSIDE_SECTOR_039:0, DET_OUTSIDE_SECTOR_040:0, DET_POINT_TARGET_PROB_037:0, DET_POINT_TARGET_PROB_038:0, DET_POINT_TARGET_PROB_039:0, DET_POINT_TARGET_PROB_040:0, DET_RANGE_037:0, DET_RANGE_038:0, DET_RANGE_039:0, DET_RANGE_040:0, DET_RANGE_ERR_037:0, DET_RANGE_ERR_038:0, DET_RANGE_ERR_039:0, DET_RANGE_ERR_040:0, DET_RANGE_VELOCITY_037:16384, DET_RANGE_VELOCITY_038:16384, DET_RANGE_VELOCITY_039:16384, DET_RANGE_VELOCITY_040:16384, DET_RANGE_VELOCITY_ERR_037:0, DET_RANGE_VELOCITY_ERR_038:0, DET_RANGE_VELOCITY_ERR_039:0, DET_RANGE_VELOCITY_ERR_040:0, DET_RCS_037:128, DET_RCS_038:128, DET_RCS_039:128, DET_RCS_040:128, DET_SNR_037:0, DET_SNR_038:0, DET_SNR_039:0, DET_SNR_040:0, DET_SUPER_RES_TARGET_037:0, DET_SUPER_RES_TARGET_038:0, DET_SUPER_RES_TARGET_039:0, DET_SUPER_RES_TARGET_040:0, DET_VALID_FLAG_037:0, DET_VALID_FLAG_038:0, DET_VALID_FLAG_039:0, DET_VALID_FLAG_040:0]}, provided-interface=Pi_SG_Detections_037_040
      Pp_SG_Detections_041_044: nonqueued-sender-com-spec{data-element=Vdp_SG_Detections_041_044, init-value=fields=[DET_AZIMUTH_041:0, DET_AZIMUTH_042:0, DET_AZIMUTH_043:0, DET_AZIMUTH_044:0, DET_AZIMUTH_ERR_041:0, DET_AZIMUTH_ERR_042:0, DET_AZIMUTH_ERR_043:0, DET_AZIMUTH_ERR_044:0, DET_BI_STATIC_FLAG_041:0, DET_BI_STATIC_FLAG_042:0, DET_BI_STATIC_FLAG_043:0, DET_BI_STATIC_FLAG_044:0, DET_CONFD_AZIMUTH_041:0, DET_CONFD_AZIMUTH_042:0, DET_CONFD_AZIMUTH_043:0, DET_CONFD_AZIMUTH_044:0, DET_CONFD_ELEVATION_041:0, DET_CONFD_ELEVATION_042:0, DET_CONFD_ELEVATION_043:0, DET_CONFD_ELEVATION_044:0, DET_ELEVATION_041:0, DET_ELEVATION_042:0, DET_ELEVATION_043:0, DET_ELEVATION_044:0, DET_ELEVATION_ERR_041:0, DET_ELEVATION_ERR_042:0, DET_ELEVATION_ERR_043:0, DET_ELEVATION_ERR_044:0, DET_EXISTENCE_PROB_041:0, DET_EXISTENCE_PROB_042:0, DET_EXISTENCE_PROB_043:0, DET_EXISTENCE_PROB_044:0, DET_HVC_FLAG_041:0, DET_HVC_FLAG_042:0, DET_HVC_FLAG_043:0, DET_HVC_FLAG_044:0, DET_MH_CRC16_041_044:0, DET_MH_CYCLE_COUNTER_041_044:0, DET_MH_SCAN_INDEX_4LSB_041_044:0, DET_OUTSIDE_SECTOR_041:0, DET_OUTSIDE_SECTOR_042:0, DET_OUTSIDE_SECTOR_043:0, DET_OUTSIDE_SECTOR_044:0, DET_POINT_TARGET_PROB_041:0, DET_POINT_TARGET_PROB_042:0, DET_POINT_TARGET_PROB_043:0, DET_POINT_TARGET_PROB_044:0, DET_RANGE_041:0, DET_RANGE_042:0, DET_RANGE_043:0, DET_RANGE_044:0, DET_RANGE_ERR_041:0, DET_RANGE_ERR_042:0, DET_RANGE_ERR_043:0, DET_RANGE_ERR_044:0, DET_RANGE_VELOCITY_041:16384, DET_RANGE_VELOCITY_042:16384, DET_RANGE_VELOCITY_043:16384, DET_RANGE_VELOCITY_044:16384, DET_RANGE_VELOCITY_ERR_041:0, DET_RANGE_VELOCITY_ERR_042:0, DET_RANGE_VELOCITY_ERR_043:0, DET_RANGE_VELOCITY_ERR_044:0, DET_RCS_041:128, DET_RCS_042:128, DET_RCS_043:128, DET_RCS_044:128, DET_SNR_041:0, DET_SNR_042:0, DET_SNR_043:0, DET_SNR_044:0, DET_SUPER_RES_TARGET_041:0, DET_SUPER_RES_TARGET_042:0, DET_SUPER_RES_TARGET_043:0, DET_SUPER_RES_TARGET_044:0, DET_VALID_FLAG_041:0, DET_VALID_FLAG_042:0, DET_VALID_FLAG_043:0, DET_VALID_FLAG_044:0]}, provided-interface=Pi_SG_Detections_041_044
      Pp_SG_Detections_045_048: nonqueued-sender-com-spec{data-element=Vdp_SG_Detections_045_048, init-value=fields=[DET_AZIMUTH_045:0, DET_AZIMUTH_046:0, DET_AZIMUTH_047:0, DET_AZIMUTH_048:0, DET_AZIMUTH_ERR_045:0, DET_AZIMUTH_ERR_046:0, DET_AZIMUTH_ERR_047:0, DET_AZIMUTH_ERR_048:0, DET_BI_STATIC_FLAG_045:0, DET_BI_STATIC_FLAG_046:0, DET_BI_STATIC_FLAG_047:0, DET_BI_STATIC_FLAG_048:0, DET_CONFD_AZIMUTH_045:0, DET_CONFD_AZIMUTH_046:0, DET_CONFD_AZIMUTH_047:0, DET_CONFD_AZIMUTH_048:0, DET_CONFD_ELEVATION_045:0, DET_CONFD_ELEVATION_046:0, DET_CONFD_ELEVATION_047:0, DET_CONFD_ELEVATION_048:0, DET_ELEVATION_045:0, DET_ELEVATION_046:0, DET_ELEVATION_047:0, DET_ELEVATION_048:0, DET_ELEVATION_ERR_045:0, DET_ELEVATION_ERR_046:0, DET_ELEVATION_ERR_047:0, DET_ELEVATION_ERR_048:0, DET_EXISTENCE_PROB_045:0, DET_EXISTENCE_PROB_046:0, DET_EXISTENCE_PROB_047:0, DET_EXISTENCE_PROB_048:0, DET_HVC_FLAG_045:0, DET_HVC_FLAG_046:0, DET_HVC_FLAG_047:0, DET_HVC_FLAG_048:0, DET_MH_CRC16_045_048:0, DET_MH_CYCLE_COUNTER_045_048:0, DET_MH_SCAN_INDEX_4LSB_045_048:0, DET_OUTSIDE_SECTOR_045:0, DET_OUTSIDE_SECTOR_046:0, DET_OUTSIDE_SECTOR_047:0, DET_OUTSIDE_SECTOR_048:0, DET_POINT_TARGET_PROB_045:0, DET_POINT_TARGET_PROB_046:0, DET_POINT_TARGET_PROB_047:0, DET_POINT_TARGET_PROB_048:0, DET_RANGE_045:0, DET_RANGE_046:0, DET_RANGE_047:0, DET_RANGE_048:0, DET_RANGE_ERR_045:0, DET_RANGE_ERR_046:0, DET_RANGE_ERR_047:0, DET_RANGE_ERR_048:0, DET_RANGE_VELOCITY_045:16384, DET_RANGE_VELOCITY_046:16384, DET_RANGE_VELOCITY_047:16384, DET_RANGE_VELOCITY_048:16384, DET_RANGE_VELOCITY_ERR_045:0, DET_RANGE_VELOCITY_ERR_046:0, DET_RANGE_VELOCITY_ERR_047:0, DET_RANGE_VELOCITY_ERR_048:0, DET_RCS_045:128, DET_RCS_046:128, DET_RCS_047:128, DET_RCS_048:128, DET_SNR_045:0, DET_SNR_046:0, DET_SNR_047:0, DET_SNR_048:0, DET_SUPER_RES_TARGET_045:0, DET_SUPER_RES_TARGET_046:0, DET_SUPER_RES_TARGET_047:0, DET_SUPER_RES_TARGET_048:0, DET_VALID_FLAG_045:0, DET_VALID_FLAG_046:0, DET_VALID_FLAG_047:0, DET_VALID_FLAG_048:0]}, provided-interface=Pi_SG_Detections_045_048
      Pp_SG_Detections_049_052: nonqueued-sender-com-spec{data-element=Vdp_SG_Detections_049_052, init-value=fields=[DET_AZIMUTH_049:0, DET_AZIMUTH_050:0, DET_AZIMUTH_051:0, DET_AZIMUTH_052:0, DET_AZIMUTH_ERR_049:0, DET_AZIMUTH_ERR_050:0, DET_AZIMUTH_ERR_051:0, DET_AZIMUTH_ERR_052:0, DET_BI_STATIC_FLAG_049:0, DET_BI_STATIC_FLAG_050:0, DET_BI_STATIC_FLAG_051:0, DET_BI_STATIC_FLAG_052:0, DET_CONFD_AZIMUTH_049:0, DET_CONFD_AZIMUTH_050:0, DET_CONFD_AZIMUTH_051:0, DET_CONFD_AZIMUTH_052:0, DET_CONFD_ELEVATION_049:0, DET_CONFD_ELEVATION_050:0, DET_CONFD_ELEVATION_051:0, DET_CONFD_ELEVATION_052:0, DET_ELEVATION_049:0, DET_ELEVATION_050:0, DET_ELEVATION_051:0, DET_ELEVATION_052:0, DET_ELEVATION_ERR_049:0, DET_ELEVATION_ERR_050:0, DET_ELEVATION_ERR_051:0, DET_ELEVATION_ERR_052:0, DET_EXISTENCE_PROB_049:0, DET_EXISTENCE_PROB_050:0, DET_EXISTENCE_PROB_051:0, DET_EXISTENCE_PROB_052:0, DET_HVC_FLAG_049:0, DET_HVC_FLAG_050:0, DET_HVC_FLAG_051:0, DET_HVC_FLAG_052:0, DET_MH_CRC16_049_052:0, DET_MH_CYCLE_COUNTER_049_052:0, DET_MH_SCAN_INDEX_4LSB_049_052:0, DET_OUTSIDE_SECTOR_049:0, DET_OUTSIDE_SECTOR_050:0, DET_OUTSIDE_SECTOR_051:0, DET_OUTSIDE_SECTOR_052:0, DET_POINT_TARGET_PROB_049:0, DET_POINT_TARGET_PROB_050:0, DET_POINT_TARGET_PROB_051:0, DET_POINT_TARGET_PROB_052:0, DET_RANGE_049:0, DET_RANGE_050:0, DET_RANGE_051:0, DET_RANGE_052:0, DET_RANGE_ERR_049:0, DET_RANGE_ERR_050:0, DET_RANGE_ERR_051:0, DET_RANGE_ERR_052:0, DET_RANGE_VELOCITY_049:16384, DET_RANGE_VELOCITY_050:16384, DET_RANGE_VELOCITY_051:16384, DET_RANGE_VELOCITY_052:16384, DET_RANGE_VELOCITY_ERR_049:0, DET_RANGE_VELOCITY_ERR_050:0, DET_RANGE_VELOCITY_ERR_051:0, DET_RANGE_VELOCITY_ERR_052:0, DET_RCS_049:128, DET_RCS_050:128, DET_RCS_051:128, DET_RCS_052:128, DET_SNR_049:0, DET_SNR_050:0, DET_SNR_051:0, DET_SNR_052:0, DET_SUPER_RES_TARGET_049:0, DET_SUPER_RES_TARGET_050:0, DET_SUPER_RES_TARGET_051:0, DET_SUPER_RES_TARGET_052:0, DET_VALID_FLAG_049:0, DET_VALID_FLAG_050:0, DET_VALID_FLAG_051:0, DET_VALID_FLAG_052:0]}, provided-interface=Pi_SG_Detections_049_052
      Pp_SG_Detections_053_056: nonqueued-sender-com-spec{data-element=Vdp_SG_Detections_053_056, init-value=fields=[DET_AZIMUTH_053:0, DET_AZIMUTH_054:0, DET_AZIMUTH_055:0, DET_AZIMUTH_056:0, DET_AZIMUTH_ERR_053:0, DET_AZIMUTH_ERR_054:0, DET_AZIMUTH_ERR_055:0, DET_AZIMUTH_ERR_056:0, DET_BI_STATIC_FLAG_053:0, DET_BI_STATIC_FLAG_054:0, DET_BI_STATIC_FLAG_055:0, DET_BI_STATIC_FLAG_056:0, DET_CONFD_AZIMUTH_053:0, DET_CONFD_AZIMUTH_054:0, DET_CONFD_AZIMUTH_055:0, DET_CONFD_AZIMUTH_056:0, DET_CONFD_ELEVATION_053:0, DET_CONFD_ELEVATION_054:0, DET_CONFD_ELEVATION_055:0, DET_CONFD_ELEVATION_056:0, DET_ELEVATION_053:0, DET_ELEVATION_054:0, DET_ELEVATION_055:0, DET_ELEVATION_056:0, DET_ELEVATION_ERR_053:0, DET_ELEVATION_ERR_054:0, DET_ELEVATION_ERR_055:0, DET_ELEVATION_ERR_056:0, DET_EXISTENCE_PROB_053:0, DET_EXISTENCE_PROB_054:0, DET_EXISTENCE_PROB_055:0, DET_EXISTENCE_PROB_056:0, DET_HVC_FLAG_053:0, DET_HVC_FLAG_054:0, DET_HVC_FLAG_055:0, DET_HVC_FLAG_056:0, DET_MH_CRC16_053_056:0, DET_MH_CYCLE_COUNTER_053_056:0, DET_MH_SCAN_INDEX_4LSB_053_056:0, DET_OUTSIDE_SECTOR_053:0, DET_OUTSIDE_SECTOR_054:0, DET_OUTSIDE_SECTOR_055:0, DET_OUTSIDE_SECTOR_056:0, DET_POINT_TARGET_PROB_053:0, DET_POINT_TARGET_PROB_054:0, DET_POINT_TARGET_PROB_055:0, DET_POINT_TARGET_PROB_056:0, DET_RANGE_053:0, DET_RANGE_054:0, DET_RANGE_055:0, DET_RANGE_056:0, DET_RANGE_ERR_053:0, DET_RANGE_ERR_054:0, DET_RANGE_ERR_055:0, DET_RANGE_ERR_056:0, DET_RANGE_VELOCITY_053:16384, DET_RANGE_VELOCITY_054:16384, DET_RANGE_VELOCITY_055:16384, DET_RANGE_VELOCITY_056:16384, DET_RANGE_VELOCITY_ERR_053:0, DET_RANGE_VELOCITY_ERR_054:0, DET_RANGE_VELOCITY_ERR_055:0, DET_RANGE_VELOCITY_ERR_056:0, DET_RCS_053:128, DET_RCS_054:128, DET_RCS_055:128, DET_RCS_056:128, DET_SNR_053:0, DET_SNR_054:0, DET_SNR_055:0, DET_SNR_056:0, DET_SUPER_RES_TARGET_053:0, DET_SUPER_RES_TARGET_054:0, DET_SUPER_RES_TARGET_055:0, DET_SUPER_RES_TARGET_056:0, DET_VALID_FLAG_053:0, DET_VALID_FLAG_054:0, DET_VALID_FLAG_055:0, DET_VALID_FLAG_056:0]}, provided-interface=Pi_SG_Detections_053_056
      Pp_SG_Detections_057_060: nonqueued-sender-com-spec{data-element=Vdp_SG_Detections_057_060, init-value=fields=[DET_AZIMUTH_057:0, DET_AZIMUTH_058:0, DET_AZIMUTH_059:0, DET_AZIMUTH_060:0, DET_AZIMUTH_ERR_057:0, DET_AZIMUTH_ERR_058:0, DET_AZIMUTH_ERR_059:0, DET_AZIMUTH_ERR_060:0, DET_BI_STATIC_FLAG_057:0, DET_BI_STATIC_FLAG_058:0, DET_BI_STATIC_FLAG_059:0, DET_BI_STATIC_FLAG_060:0, DET_CONFD_AZIMUTH_057:0, DET_CONFD_AZIMUTH_058:0, DET_CONFD_AZIMUTH_059:0, DET_CONFD_AZIMUTH_060:0, DET_CONFD_ELEVATION_057:0, DET_CONFD_ELEVATION_058:0, DET_CONFD_ELEVATION_059:0, DET_CONFD_ELEVATION_060:0, DET_ELEVATION_057:0, DET_ELEVATION_058:0, DET_ELEVATION_059:0, DET_ELEVATION_060:0, DET_ELEVATION_ERR_057:0, DET_ELEVATION_ERR_058:0, DET_ELEVATION_ERR_059:0, DET_ELEVATION_ERR_060:0, DET_EXISTENCE_PROB_057:0, DET_EXISTENCE_PROB_058:0, DET_EXISTENCE_PROB_059:0, DET_EXISTENCE_PROB_060:0, DET_HVC_FLAG_057:0, DET_HVC_FLAG_058:0, DET_HVC_FLAG_059:0, DET_HVC_FLAG_060:0, DET_MH_CRC16_057_060:0, DET_MH_CYCLE_COUNTER_057_060:0, DET_MH_SCAN_INDEX_4LSB_057_060:0, DET_OUTSIDE_SECTOR_057:0, DET_OUTSIDE_SECTOR_058:0, DET_OUTSIDE_SECTOR_059:0, DET_OUTSIDE_SECTOR_060:0, DET_POINT_TARGET_PROB_057:0, DET_POINT_TARGET_PROB_058:0, DET_POINT_TARGET_PROB_059:0, DET_POINT_TARGET_PROB_060:0, DET_RANGE_057:0, DET_RANGE_058:0, DET_RANGE_059:0, DET_RANGE_060:0, DET_RANGE_ERR_057:0, DET_RANGE_ERR_058:0, DET_RANGE_ERR_059:0, DET_RANGE_ERR_060:0, DET_RANGE_VELOCITY_057:16384, DET_RANGE_VELOCITY_058:16384, DET_RANGE_VELOCITY_059:16384, DET_RANGE_VELOCITY_060:16384, DET_RANGE_VELOCITY_ERR_057:0, DET_RANGE_VELOCITY_ERR_058:0, DET_RANGE_VELOCITY_ERR_059:0, DET_RANGE_VELOCITY_ERR_060:0, DET_RCS_057:128, DET_RCS_058:128, DET_RCS_059:128, DET_RCS_060:128, DET_SNR_057:0, DET_SNR_058:0, DET_SNR_059:0, DET_SNR_060:0, DET_SUPER_RES_TARGET_057:0, DET_SUPER_RES_TARGET_058:0, DET_SUPER_RES_TARGET_059:0, DET_SUPER_RES_TARGET_060:0, DET_VALID_FLAG_057:0, DET_VALID_FLAG_058:0, DET_VALID_FLAG_059:0, DET_VALID_FLAG_060:0]}, provided-interface=Pi_SG_Detections_057_060
      Pp_SG_Detections_061_064: nonqueued-sender-com-spec{data-element=Vdp_SG_Detections_061_064, init-value=fields=[DET_AZIMUTH_061:0, DET_AZIMUTH_062:0, DET_AZIMUTH_063:0, DET_AZIMUTH_064:0, DET_AZIMUTH_ERR_061:0, DET_AZIMUTH_ERR_062:0, DET_AZIMUTH_ERR_063:0, DET_AZIMUTH_ERR_064:0, DET_BI_STATIC_FLAG_061:0, DET_BI_STATIC_FLAG_062:0, DET_BI_STATIC_FLAG_063:0, DET_BI_STATIC_FLAG_064:0, DET_CONFD_AZIMUTH_061:0, DET_CONFD_AZIMUTH_062:0, DET_CONFD_AZIMUTH_063:0, DET_CONFD_AZIMUTH_064:0, DET_CONFD_ELEVATION_061:0, DET_CONFD_ELEVATION_062:0, DET_CONFD_ELEVATION_063:0, DET_CONFD_ELEVATION_064:0, DET_ELEVATION_061:0, DET_ELEVATION_062:0, DET_ELEVATION_063:0, DET_ELEVATION_064:0, DET_ELEVATION_ERR_061:0, DET_ELEVATION_ERR_062:0, DET_ELEVATION_ERR_063:0, DET_ELEVATION_ERR_064:0, DET_EXISTENCE_PROB_061:0, DET_EXISTENCE_PROB_062:0, DET_EXISTENCE_PROB_063:0, DET_EXISTENCE_PROB_064:0, DET_HVC_FLAG_061:0, DET_HVC_FLAG_062:0, DET_HVC_FLAG_063:0, DET_HVC_FLAG_064:0, DET_MH_CRC16_061_064:0, DET_MH_CYCLE_COUNTER_061_064:0, DET_MH_SCAN_INDEX_4LSB_061_064:0, DET_OUTSIDE_SECTOR_061:0, DET_OUTSIDE_SECTOR_062:0, DET_OUTSIDE_SECTOR_063:0, DET_OUTSIDE_SECTOR_064:0, DET_POINT_TARGET_PROB_061:0, DET_POINT_TARGET_PROB_062:0, DET_POINT_TARGET_PROB_063:0, DET_POINT_TARGET_PROB_064:0, DET_RANGE_061:0, DET_RANGE_062:0, DET_RANGE_063:0, DET_RANGE_064:0, DET_RANGE_ERR_061:0, DET_RANGE_ERR_062:0, DET_RANGE_ERR_063:0, DET_RANGE_ERR_064:0, DET_RANGE_VELOCITY_061:16384, DET_RANGE_VELOCITY_062:16384, DET_RANGE_VELOCITY_063:16384, DET_RANGE_VELOCITY_064:16384, DET_RANGE_VELOCITY_ERR_061:0, DET_RANGE_VELOCITY_ERR_062:0, DET_RANGE_VELOCITY_ERR_063:0, DET_RANGE_VELOCITY_ERR_064:0, DET_RCS_061:128, DET_RCS_062:128, DET_RCS_063:128, DET_RCS_064:128, DET_SNR_061:0, DET_SNR_062:0, DET_SNR_063:0, DET_SNR_064:0, DET_SUPER_RES_TARGET_061:0, DET_SUPER_RES_TARGET_062:0, DET_SUPER_RES_TARGET_063:0, DET_SUPER_RES_TARGET_064:0, DET_VALID_FLAG_061:0, DET_VALID_FLAG_062:0, DET_VALID_FLAG_063:0, DET_VALID_FLAG_064:0]}, provided-interface=Pi_SG_Detections_061_064
      Pp_SG_Detections_065_068: nonqueued-sender-com-spec{data-element=Vdp_SG_Detections_065_068, init-value=fields=[DET_AZIMUTH_065:0, DET_AZIMUTH_066:0, DET_AZIMUTH_067:0, DET_AZIMUTH_068:0, DET_AZIMUTH_ERR_065:0, DET_AZIMUTH_ERR_066:0, DET_AZIMUTH_ERR_067:0, DET_AZIMUTH_ERR_068:0, DET_BI_STATIC_FLAG_065:0, DET_BI_STATIC_FLAG_066:0, DET_BI_STATIC_FLAG_067:0, DET_BI_STATIC_FLAG_068:0, DET_CONFD_AZIMUTH_065:0, DET_CONFD_AZIMUTH_066:0, DET_CONFD_AZIMUTH_067:0, DET_CONFD_AZIMUTH_068:0, DET_CONFD_ELEVATION_065:0, DET_CONFD_ELEVATION_066:0, DET_CONFD_ELEVATION_067:0, DET_CONFD_ELEVATION_068:0, DET_ELEVATION_065:0, DET_ELEVATION_066:0, DET_ELEVATION_067:0, DET_ELEVATION_068:0, DET_ELEVATION_ERR_065:0, DET_ELEVATION_ERR_066:0, DET_ELEVATION_ERR_067:0, DET_ELEVATION_ERR_068:0, DET_EXISTENCE_PROB_065:0, DET_EXISTENCE_PROB_066:0, DET_EXISTENCE_PROB_067:0, DET_EXISTENCE_PROB_068:0, DET_HVC_FLAG_065:0, DET_HVC_FLAG_066:0, DET_HVC_FLAG_067:0, DET_HVC_FLAG_068:0, DET_MH_CRC16_065_068:0, DET_MH_CYCLE_COUNTER_065_068:0, DET_MH_SCAN_INDEX_4LSB_065_068:0, DET_OUTSIDE_SECTOR_065:0, DET_OUTSIDE_SECTOR_066:0, DET_OUTSIDE_SECTOR_067:0, DET_OUTSIDE_SECTOR_068:0, DET_POINT_TARGET_PROB_065:0, DET_POINT_TARGET_PROB_066:0, DET_POINT_TARGET_PROB_067:0, DET_POINT_TARGET_PROB_068:0, DET_RANGE_065:0, DET_RANGE_066:0, DET_RANGE_067:0, DET_RANGE_068:0, DET_RANGE_ERR_065:0, DET_RANGE_ERR_066:0, DET_RANGE_ERR_067:0, DET_RANGE_ERR_068:0, DET_RANGE_VELOCITY_065:16384, DET_RANGE_VELOCITY_066:16384, DET_RANGE_VELOCITY_067:16384, DET_RANGE_VELOCITY_068:16384, DET_RANGE_VELOCITY_ERR_065:0, DET_RANGE_VELOCITY_ERR_066:0, DET_RANGE_VELOCITY_ERR_067:0, DET_RANGE_VELOCITY_ERR_068:0, DET_RCS_065:128, DET_RCS_066:128, DET_RCS_067:128, DET_RCS_068:128, DET_SNR_065:0, DET_SNR_066:0, DET_SNR_067:0, DET_SNR_068:0, DET_SUPER_RES_TARGET_065:0, DET_SUPER_RES_TARGET_066:0, DET_SUPER_RES_TARGET_067:0, DET_SUPER_RES_TARGET_068:0, DET_VALID_FLAG_065:0, DET_VALID_FLAG_066:0, DET_VALID_FLAG_067:0, DET_VALID_FLAG_068:0]}, provided-interface=Pi_SG_Detections_065_068
      Pp_SG_Detections_069_072: nonqueued-sender-com-spec{data-element=Vdp_SG_Detections_069_072, init-value=fields=[DET_AZIMUTH_069:0, DET_AZIMUTH_070:0, DET_AZIMUTH_071:0, DET_AZIMUTH_072:0, DET_AZIMUTH_ERR_069:0, DET_AZIMUTH_ERR_070:0, DET_AZIMUTH_ERR_071:0, DET_AZIMUTH_ERR_072:0, DET_BI_STATIC_FLAG_069:0, DET_BI_STATIC_FLAG_070:0, DET_BI_STATIC_FLAG_071:0, DET_BI_STATIC_FLAG_072:0, DET_CONFD_AZIMUTH_069:0, DET_CONFD_AZIMUTH_070:0, DET_CONFD_AZIMUTH_071:0, DET_CONFD_AZIMUTH_072:0, DET_CONFD_ELEVATION_069:0, DET_CONFD_ELEVATION_070:0, DET_CONFD_ELEVATION_071:0, DET_CONFD_ELEVATION_072:0, DET_ELEVATION_069:0, DET_ELEVATION_070:0, DET_ELEVATION_071:0, DET_ELEVATION_072:0, DET_ELEVATION_ERR_069:0, DET_ELEVATION_ERR_070:0, DET_ELEVATION_ERR_071:0, DET_ELEVATION_ERR_072:0, DET_EXISTENCE_PROB_069:0, DET_EXISTENCE_PROB_070:0, DET_EXISTENCE_PROB_071:0, DET_EXISTENCE_PROB_072:0, DET_HVC_FLAG_069:0, DET_HVC_FLAG_070:0, DET_HVC_FLAG_071:0, DET_HVC_FLAG_072:0, DET_MH_CRC16_069_072:0, DET_MH_CYCLE_COUNTER_069_072:0, DET_MH_SCAN_INDEX_4LSB_069_072:0, DET_OUTSIDE_SECTOR_069:0, DET_OUTSIDE_SECTOR_070:0, DET_OUTSIDE_SECTOR_071:0, DET_OUTSIDE_SECTOR_072:0, DET_POINT_TARGET_PROB_069:0, DET_POINT_TARGET_PROB_070:0, DET_POINT_TARGET_PROB_071:0, DET_POINT_TARGET_PROB_072:0, DET_RANGE_069:0, DET_RANGE_070:0, DET_RANGE_071:0, DET_RANGE_072:0, DET_RANGE_ERR_069:0, DET_RANGE_ERR_070:0, DET_RANGE_ERR_071:0, DET_RANGE_ERR_072:0, DET_RANGE_VELOCITY_069:16384, DET_RANGE_VELOCITY_070:16384, DET_RANGE_VELOCITY_071:16384, DET_RANGE_VELOCITY_072:16384, DET_RANGE_VELOCITY_ERR_069:0, DET_RANGE_VELOCITY_ERR_070:0, DET_RANGE_VELOCITY_ERR_071:0, DET_RANGE_VELOCITY_ERR_072:0, DET_RCS_069:128, DET_RCS_070:128, DET_RCS_071:128, DET_RCS_072:128, DET_SNR_069:0, DET_SNR_070:0, DET_SNR_071:0, DET_SNR_072:0, DET_SUPER_RES_TARGET_069:0, DET_SUPER_RES_TARGET_070:0, DET_SUPER_RES_TARGET_071:0, DET_SUPER_RES_TARGET_072:0, DET_VALID_FLAG_069:0, DET_VALID_FLAG_070:0, DET_VALID_FLAG_071:0, DET_VALID_FLAG_072:0]}, provided-interface=Pi_SG_Detections_069_072
      Pp_SG_Detections_073_076: nonqueued-sender-com-spec{data-element=Vdp_SG_Detections_073_076, init-value=fields=[DET_AZIMUTH_073:0, DET_AZIMUTH_074:0, DET_AZIMUTH_075:0, DET_AZIMUTH_076:0, DET_AZIMUTH_ERR_073:0, DET_AZIMUTH_ERR_074:0, DET_AZIMUTH_ERR_075:0, DET_AZIMUTH_ERR_076:0, DET_BI_STATIC_FLAG_073:0, DET_BI_STATIC_FLAG_074:0, DET_BI_STATIC_FLAG_075:0, DET_BI_STATIC_FLAG_076:0, DET_CONFD_AZIMUTH_073:0, DET_CONFD_AZIMUTH_074:0, DET_CONFD_AZIMUTH_075:0, DET_CONFD_AZIMUTH_076:0, DET_CONFD_ELEVATION_073:0, DET_CONFD_ELEVATION_074:0, DET_CONFD_ELEVATION_075:0, DET_CONFD_ELEVATION_076:0, DET_ELEVATION_073:0, DET_ELEVATION_074:0, DET_ELEVATION_075:0, DET_ELEVATION_076:0, DET_ELEVATION_ERR_073:0, DET_ELEVATION_ERR_074:0, DET_ELEVATION_ERR_075:0, DET_ELEVATION_ERR_076:0, DET_EXISTENCE_PROB_073:0, DET_EXISTENCE_PROB_074:0, DET_EXISTENCE_PROB_075:0, DET_EXISTENCE_PROB_076:0, DET_HVC_FLAG_073:0, DET_HVC_FLAG_074:0, DET_HVC_FLAG_075:0, DET_HVC_FLAG_076:0, DET_MH_CRC16_073_076:0, DET_MH_CYCLE_COUNTER_073_076:0, DET_MH_SCAN_INDEX_4LSB_073_076:0, DET_OUTSIDE_SECTOR_073:0, DET_OUTSIDE_SECTOR_074:0, DET_OUTSIDE_SECTOR_075:0, DET_OUTSIDE_SECTOR_076:0, DET_POINT_TARGET_PROB_073:0, DET_POINT_TARGET_PROB_074:0, DET_POINT_TARGET_PROB_075:0, DET_POINT_TARGET_PROB_076:0, DET_RANGE_073:0, DET_RANGE_074:0, DET_RANGE_075:0, DET_RANGE_076:0, DET_RANGE_ERR_073:0, DET_RANGE_ERR_074:0, DET_RANGE_ERR_075:0, DET_RANGE_ERR_076:0, DET_RANGE_VELOCITY_073:16384, DET_RANGE_VELOCITY_074:16384, DET_RANGE_VELOCITY_075:16384, DET_RANGE_VELOCITY_076:16384, DET_RANGE_VELOCITY_ERR_073:0, DET_RANGE_VELOCITY_ERR_074:0, DET_RANGE_VELOCITY_ERR_075:0, DET_RANGE_VELOCITY_ERR_076:0, DET_RCS_073:128, DET_RCS_074:128, DET_RCS_075:128, DET_RCS_076:128, DET_SNR_073:0, DET_SNR_074:0, DET_SNR_075:0, DET_SNR_076:0, DET_SUPER_RES_TARGET_073:0, DET_SUPER_RES_TARGET_074:0, DET_SUPER_RES_TARGET_075:0, DET_SUPER_RES_TARGET_076:0, DET_VALID_FLAG_073:0, DET_VALID_FLAG_074:0, DET_VALID_FLAG_075:0, DET_VALID_FLAG_076:0]}, provided-interface=Pi_SG_Detections_073_076
      Pp_SG_Detections_077_080: nonqueued-sender-com-spec{data-element=Vdp_SG_Detections_077_080, init-value=fields=[DET_AZIMUTH_077:0, DET_AZIMUTH_078:0, DET_AZIMUTH_079:0, DET_AZIMUTH_080:0, DET_AZIMUTH_ERR_077:0, DET_AZIMUTH_ERR_078:0, DET_AZIMUTH_ERR_079:0, DET_AZIMUTH_ERR_080:0, DET_BI_STATIC_FLAG_077:0, DET_BI_STATIC_FLAG_078:0, DET_BI_STATIC_FLAG_079:0, DET_BI_STATIC_FLAG_080:0, DET_CONFD_AZIMUTH_077:0, DET_CONFD_AZIMUTH_078:0, DET_CONFD_AZIMUTH_079:0, DET_CONFD_AZIMUTH_080:0, DET_CONFD_ELEVATION_077:0, DET_CONFD_ELEVATION_078:0, DET_CONFD_ELEVATION_079:0, DET_CONFD_ELEVATION_080:0, DET_ELEVATION_077:0, DET_ELEVATION_078:0, DET_ELEVATION_079:0, DET_ELEVATION_080:0, DET_ELEVATION_ERR_077:0, DET_ELEVATION_ERR_078:0, DET_ELEVATION_ERR_079:0, DET_ELEVATION_ERR_080:0, DET_EXISTENCE_PROB_077:0, DET_EXISTENCE_PROB_078:0, DET_EXISTENCE_PROB_079:0, DET_EXISTENCE_PROB_080:0, DET_HVC_FLAG_077:0, DET_HVC_FLAG_078:0, DET_HVC_FLAG_079:0, DET_HVC_FLAG_080:0, DET_MH_CRC16_077_080:0, DET_MH_CYCLE_COUNTER_077_080:0, DET_MH_SCAN_INDEX_4LSB_077_080:0, DET_OUTSIDE_SECTOR_077:0, DET_OUTSIDE_SECTOR_078:0, DET_OUTSIDE_SECTOR_079:0, DET_OUTSIDE_SECTOR_080:0, DET_POINT_TARGET_PROB_077:0, DET_POINT_TARGET_PROB_078:0, DET_POINT_TARGET_PROB_079:0, DET_POINT_TARGET_PROB_080:0, DET_RANGE_077:0, DET_RANGE_078:0, DET_RANGE_079:0, DET_RANGE_080:0, DET_RANGE_ERR_077:0, DET_RANGE_ERR_078:0, DET_RANGE_ERR_079:0, DET_RANGE_ERR_080:0, DET_RANGE_VELOCITY_077:16384, DET_RANGE_VELOCITY_078:16384, DET_RANGE_VELOCITY_079:16384, DET_RANGE_VELOCITY_080:16384, DET_RANGE_VELOCITY_ERR_077:0, DET_RANGE_VELOCITY_ERR_078:0, DET_RANGE_VELOCITY_ERR_079:0, DET_RANGE_VELOCITY_ERR_080:0, DET_RCS_077:128, DET_RCS_078:128, DET_RCS_079:128, DET_RCS_080:128, DET_SNR_077:0, DET_SNR_078:0, DET_SNR_079:0, DET_SNR_080:0, DET_SUPER_RES_TARGET_077:0, DET_SUPER_RES_TARGET_078:0, DET_SUPER_RES_TARGET_079:0, DET_SUPER_RES_TARGET_080:0, DET_VALID_FLAG_077:0, DET_VALID_FLAG_078:0, DET_VALID_FLAG_079:0, DET_VALID_FLAG_080:0]}, provided-interface=Pi_SG_Detections_077_080
      Pp_SG_Detections_081_084: nonqueued-sender-com-spec{data-element=Vdp_SG_Detections_081_084, init-value=fields=[DET_AZIMUTH_081:0, DET_AZIMUTH_082:0, DET_AZIMUTH_083:0, DET_AZIMUTH_084:0, DET_AZIMUTH_ERR_081:0, DET_AZIMUTH_ERR_082:0, DET_AZIMUTH_ERR_083:0, DET_AZIMUTH_ERR_084:0, DET_BI_STATIC_FLAG_081:0, DET_BI_STATIC_FLAG_082:0, DET_BI_STATIC_FLAG_083:0, DET_BI_STATIC_FLAG_084:0, DET_CONFD_AZIMUTH_081:0, DET_CONFD_AZIMUTH_082:0, DET_CONFD_AZIMUTH_083:0, DET_CONFD_AZIMUTH_084:0, DET_CONFD_ELEVATION_081:0, DET_CONFD_ELEVATION_082:0, DET_CONFD_ELEVATION_083:0, DET_CONFD_ELEVATION_084:0, DET_ELEVATION_081:0, DET_ELEVATION_082:0, DET_ELEVATION_083:0, DET_ELEVATION_084:0, DET_ELEVATION_ERR_081:0, DET_ELEVATION_ERR_082:0, DET_ELEVATION_ERR_083:0, DET_ELEVATION_ERR_084:0, DET_EXISTENCE_PROB_081:0, DET_EXISTENCE_PROB_082:0, DET_EXISTENCE_PROB_083:0, DET_EXISTENCE_PROB_084:0, DET_HVC_FLAG_081:0, DET_HVC_FLAG_082:0, DET_HVC_FLAG_083:0, DET_HVC_FLAG_084:0, DET_MH_CRC16_081_084:0, DET_MH_CYCLE_COUNTER_081_084:0, DET_MH_SCAN_INDEX_4LSB_081_084:0, DET_OUTSIDE_SECTOR_081:0, DET_OUTSIDE_SECTOR_082:0, DET_OUTSIDE_SECTOR_083:0, DET_OUTSIDE_SECTOR_084:0, DET_POINT_TARGET_PROB_081:0, DET_POINT_TARGET_PROB_082:0, DET_POINT_TARGET_PROB_083:0, DET_POINT_TARGET_PROB_084:0, DET_RANGE_081:0, DET_RANGE_082:0, DET_RANGE_083:0, DET_RANGE_084:0, DET_RANGE_ERR_081:0, DET_RANGE_ERR_082:0, DET_RANGE_ERR_083:0, DET_RANGE_ERR_084:0, DET_RANGE_VELOCITY_081:16384, DET_RANGE_VELOCITY_082:16384, DET_RANGE_VELOCITY_083:16384, DET_RANGE_VELOCITY_084:16384, DET_RANGE_VELOCITY_ERR_081:0, DET_RANGE_VELOCITY_ERR_082:0, DET_RANGE_VELOCITY_ERR_083:0, DET_RANGE_VELOCITY_ERR_084:0, DET_RCS_081:128, DET_RCS_082:128, DET_RCS_083:128, DET_RCS_084:128, DET_SNR_081:0, DET_SNR_082:0, DET_SNR_083:0, DET_SNR_084:0, DET_SUPER_RES_TARGET_081:0, DET_SUPER_RES_TARGET_082:0, DET_SUPER_RES_TARGET_083:0, DET_SUPER_RES_TARGET_084:0, DET_VALID_FLAG_081:0, DET_VALID_FLAG_082:0, DET_VALID_FLAG_083:0, DET_VALID_FLAG_084:0]}, provided-interface=Pi_SG_Detections_081_084
      Pp_SG_Detections_085_088: nonqueued-sender-com-spec{data-element=Vdp_SG_Detections_085_088, init-value=fields=[DET_AZIMUTH_085:0, DET_AZIMUTH_086:0, DET_AZIMUTH_087:0, DET_AZIMUTH_088:0, DET_AZIMUTH_ERR_085:0, DET_AZIMUTH_ERR_086:0, DET_AZIMUTH_ERR_087:0, DET_AZIMUTH_ERR_088:0, DET_BI_STATIC_FLAG_085:0, DET_BI_STATIC_FLAG_086:0, DET_BI_STATIC_FLAG_087:0, DET_BI_STATIC_FLAG_088:0, DET_CONFD_AZIMUTH_085:0, DET_CONFD_AZIMUTH_086:0, DET_CONFD_AZIMUTH_087:0, DET_CONFD_AZIMUTH_088:0, DET_CONFD_ELEVATION_085:0, DET_CONFD_ELEVATION_086:0, DET_CONFD_ELEVATION_087:0, DET_CONFD_ELEVATION_088:0, DET_ELEVATION_085:0, DET_ELEVATION_086:0, DET_ELEVATION_087:0, DET_ELEVATION_088:0, DET_ELEVATION_ERR_085:0, DET_ELEVATION_ERR_086:0, DET_ELEVATION_ERR_087:0, DET_ELEVATION_ERR_088:0, DET_EXISTENCE_PROB_085:0, DET_EXISTENCE_PROB_086:0, DET_EXISTENCE_PROB_087:0, DET_EXISTENCE_PROB_088:0, DET_HVC_FLAG_085:0, DET_HVC_FLAG_086:0, DET_HVC_FLAG_087:0, DET_HVC_FLAG_088:0, DET_MH_CRC16_085_088:0, DET_MH_CYCLE_COUNTER_085_088:0, DET_MH_SCAN_INDEX_4LSB_085_088:0, DET_OUTSIDE_SECTOR_085:0, DET_OUTSIDE_SECTOR_086:0, DET_OUTSIDE_SECTOR_087:0, DET_OUTSIDE_SECTOR_088:0, DET_POINT_TARGET_PROB_085:0, DET_POINT_TARGET_PROB_086:0, DET_POINT_TARGET_PROB_087:0, DET_POINT_TARGET_PROB_088:0, DET_RANGE_085:0, DET_RANGE_086:0, DET_RANGE_087:0, DET_RANGE_088:0, DET_RANGE_ERR_085:0, DET_RANGE_ERR_086:0, DET_RANGE_ERR_087:0, DET_RANGE_ERR_088:0, DET_RANGE_VELOCITY_085:16384, DET_RANGE_VELOCITY_086:16384, DET_RANGE_VELOCITY_087:16384, DET_RANGE_VELOCITY_088:16384, DET_RANGE_VELOCITY_ERR_085:0, DET_RANGE_VELOCITY_ERR_086:0, DET_RANGE_VELOCITY_ERR_087:0, DET_RANGE_VELOCITY_ERR_088:0, DET_RCS_085:128, DET_RCS_086:128, DET_RCS_087:128, DET_RCS_088:128, DET_SNR_085:0, DET_SNR_086:0, DET_SNR_087:0, DET_SNR_088:0, DET_SUPER_RES_TARGET_085:0, DET_SUPER_RES_TARGET_086:0, DET_SUPER_RES_TARGET_087:0, DET_SUPER_RES_TARGET_088:0, DET_VALID_FLAG_085:0, DET_VALID_FLAG_086:0, DET_VALID_FLAG_087:0, DET_VALID_FLAG_088:0]}, provided-interface=Pi_SG_Detections_085_088
      Pp_SG_Detections_089_092: nonqueued-sender-com-spec{data-element=Vdp_SG_Detections_089_092, init-value=fields=[DET_AZIMUTH_089:0, DET_AZIMUTH_090:0, DET_AZIMUTH_091:0, DET_AZIMUTH_092:0, DET_AZIMUTH_ERR_089:0, DET_AZIMUTH_ERR_090:0, DET_AZIMUTH_ERR_091:0, DET_AZIMUTH_ERR_092:0, DET_BI_STATIC_FLAG_089:0, DET_BI_STATIC_FLAG_090:0, DET_BI_STATIC_FLAG_091:0, DET_BI_STATIC_FLAG_092:0, DET_CONFD_AZIMUTH_089:0, DET_CONFD_AZIMUTH_090:0, DET_CONFD_AZIMUTH_091:0, DET_CONFD_AZIMUTH_092:0, DET_CONFD_ELEVATION_089:0, DET_CONFD_ELEVATION_090:0, DET_CONFD_ELEVATION_091:0, DET_CONFD_ELEVATION_092:0, DET_ELEVATION_089:0, DET_ELEVATION_090:0, DET_ELEVATION_091:0, DET_ELEVATION_092:0, DET_ELEVATION_ERR_089:0, DET_ELEVATION_ERR_090:0, DET_ELEVATION_ERR_091:0, DET_ELEVATION_ERR_092:0, DET_EXISTENCE_PROB_089:0, DET_EXISTENCE_PROB_090:0, DET_EXISTENCE_PROB_091:0, DET_EXISTENCE_PROB_092:0, DET_HVC_FLAG_089:0, DET_HVC_FLAG_090:0, DET_HVC_FLAG_091:0, DET_HVC_FLAG_092:0, DET_MH_CRC16_089_092:0, DET_MH_CYCLE_COUNTER_089_092:0, DET_MH_SCAN_INDEX_4LSB_089_092:0, DET_OUTSIDE_SECTOR_089:0, DET_OUTSIDE_SECTOR_090:0, DET_OUTSIDE_SECTOR_091:0, DET_OUTSIDE_SECTOR_092:0, DET_POINT_TARGET_PROB_089:0, DET_POINT_TARGET_PROB_090:0, DET_POINT_TARGET_PROB_091:0, DET_POINT_TARGET_PROB_092:0, DET_RANGE_089:0, DET_RANGE_090:0, DET_RANGE_091:0, DET_RANGE_092:0, DET_RANGE_ERR_089:0, DET_RANGE_ERR_090:0, DET_RANGE_ERR_091:0, DET_RANGE_ERR_092:0, DET_RANGE_VELOCITY_089:16384, DET_RANGE_VELOCITY_090:16384, DET_RANGE_VELOCITY_091:16384, DET_RANGE_VELOCITY_092:16384, DET_RANGE_VELOCITY_ERR_089:0, DET_RANGE_VELOCITY_ERR_090:0, DET_RANGE_VELOCITY_ERR_091:0, DET_RANGE_VELOCITY_ERR_092:0, DET_RCS_089:128, DET_RCS_090:128, DET_RCS_091:128, DET_RCS_092:128, DET_SNR_089:0, DET_SNR_090:0, DET_SNR_091:0, DET_SNR_092:0, DET_SUPER_RES_TARGET_089:0, DET_SUPER_RES_TARGET_090:0, DET_SUPER_RES_TARGET_091:0, DET_SUPER_RES_TARGET_092:0, DET_VALID_FLAG_089:0, DET_VALID_FLAG_090:0, DET_VALID_FLAG_091:0, DET_VALID_FLAG_092:0]}, provided-interface=Pi_SG_Detections_089_092
      Pp_SG_Detections_093_096: nonqueued-sender-com-spec{data-element=Vdp_SG_Detections_093_096, init-value=fields=[DET_AZIMUTH_093:0, DET_AZIMUTH_094:0, DET_AZIMUTH_095:0, DET_AZIMUTH_096:0, DET_AZIMUTH_ERR_093:0, DET_AZIMUTH_ERR_094:0, DET_AZIMUTH_ERR_095:0, DET_AZIMUTH_ERR_096:0, DET_BI_STATIC_FLAG_093:0, DET_BI_STATIC_FLAG_094:0, DET_BI_STATIC_FLAG_095:0, DET_BI_STATIC_FLAG_096:0, DET_CONFD_AZIMUTH_093:0, DET_CONFD_AZIMUTH_094:0, DET_CONFD_AZIMUTH_095:0, DET_CONFD_AZIMUTH_096:0, DET_CONFD_ELEVATION_093:0, DET_CONFD_ELEVATION_094:0, DET_CONFD_ELEVATION_095:0, DET_CONFD_ELEVATION_096:0, DET_ELEVATION_093:0, DET_ELEVATION_094:0, DET_ELEVATION_095:0, DET_ELEVATION_096:0, DET_ELEVATION_ERR_093:0, DET_ELEVATION_ERR_094:0, DET_ELEVATION_ERR_095:0, DET_ELEVATION_ERR_096:0, DET_EXISTENCE_PROB_093:0, DET_EXISTENCE_PROB_094:0, DET_EXISTENCE_PROB_095:0, DET_EXISTENCE_PROB_096:0, DET_HVC_FLAG_093:0, DET_HVC_FLAG_094:0, DET_HVC_FLAG_095:0, DET_HVC_FLAG_096:0, DET_MH_CRC16_093_096:0, DET_MH_CYCLE_COUNTER_093_096:0, DET_MH_SCAN_INDEX_4LSB_093_096:0, DET_OUTSIDE_SECTOR_093:0, DET_OUTSIDE_SECTOR_094:0, DET_OUTSIDE_SECTOR_095:0, DET_OUTSIDE_SECTOR_096:0, DET_POINT_TARGET_PROB_093:0, DET_POINT_TARGET_PROB_094:0, DET_POINT_TARGET_PROB_095:0, DET_POINT_TARGET_PROB_096:0, DET_RANGE_093:0, DET_RANGE_094:0, DET_RANGE_095:0, DET_RANGE_096:0, DET_RANGE_ERR_093:0, DET_RANGE_ERR_094:0, DET_RANGE_ERR_095:0, DET_RANGE_ERR_096:0, DET_RANGE_VELOCITY_093:16384, DET_RANGE_VELOCITY_094:16384, DET_RANGE_VELOCITY_095:16384, DET_RANGE_VELOCITY_096:16384, DET_RANGE_VELOCITY_ERR_093:0, DET_RANGE_VELOCITY_ERR_094:0, DET_RANGE_VELOCITY_ERR_095:0, DET_RANGE_VELOCITY_ERR_096:0, DET_RCS_093:128, DET_RCS_094:128, DET_RCS_095:128, DET_RCS_096:128, DET_SNR_093:0, DET_SNR_094:0, DET_SNR_095:0, DET_SNR_096:0, DET_SUPER_RES_TARGET_093:0, DET_SUPER_RES_TARGET_094:0, DET_SUPER_RES_TARGET_095:0, DET_SUPER_RES_TARGET_096:0, DET_VALID_FLAG_093:0, DET_VALID_FLAG_094:0, DET_VALID_FLAG_095:0, DET_VALID_FLAG_096:0]}, provided-interface=Pi_SG_Detections_093_096
      Pp_SG_Detections_097_100: nonqueued-sender-com-spec{data-element=Vdp_SG_Detections_097_100, init-value=fields=[DET_AZIMUTH_097:0, DET_AZIMUTH_098:0, DET_AZIMUTH_099:0, DET_AZIMUTH_100:0, DET_AZIMUTH_ERR_097:0, DET_AZIMUTH_ERR_098:0, DET_AZIMUTH_ERR_099:0, DET_AZIMUTH_ERR_100:0, DET_BI_STATIC_FLAG_097:0, DET_BI_STATIC_FLAG_098:0, DET_BI_STATIC_FLAG_099:0, DET_BI_STATIC_FLAG_100:0, DET_CONFD_AZIMUTH_097:0, DET_CONFD_AZIMUTH_098:0, DET_CONFD_AZIMUTH_099:0, DET_CONFD_AZIMUTH_100:0, DET_CONFD_ELEVATION_097:0, DET_CONFD_ELEVATION_098:0, DET_CONFD_ELEVATION_099:0, DET_CONFD_ELEVATION_100:0, DET_ELEVATION_097:0, DET_ELEVATION_098:0, DET_ELEVATION_099:0, DET_ELEVATION_100:0, DET_ELEVATION_ERR_097:0, DET_ELEVATION_ERR_098:0, DET_ELEVATION_ERR_099:0, DET_ELEVATION_ERR_100:0, DET_EXISTENCE_PROB_097:0, DET_EXISTENCE_PROB_098:0, DET_EXISTENCE_PROB_099:0, DET_EXISTENCE_PROB_100:0, DET_HVC_FLAG_097:0, DET_HVC_FLAG_098:0, DET_HVC_FLAG_099:0, DET_HVC_FLAG_100:0, DET_MH_CRC16_097_100:0, DET_MH_CYCLE_COUNTER_097_100:0, DET_MH_SCAN_INDEX_4LSB_097_100:0, DET_OUTSIDE_SECTOR_097:0, DET_OUTSIDE_SECTOR_098:0, DET_OUTSIDE_SECTOR_099:0, DET_OUTSIDE_SECTOR_100:0, DET_POINT_TARGET_PROB_097:0, DET_POINT_TARGET_PROB_098:0, DET_POINT_TARGET_PROB_099:0, DET_POINT_TARGET_PROB_100:0, DET_RANGE_097:0, DET_RANGE_098:0, DET_RANGE_099:0, DET_RANGE_100:0, DET_RANGE_ERR_097:0, DET_RANGE_ERR_098:0, DET_RANGE_ERR_099:0, DET_RANGE_ERR_100:0, DET_RANGE_VELOCITY_097:16384, DET_RANGE_VELOCITY_098:16384, DET_RANGE_VELOCITY_099:16384, DET_RANGE_VELOCITY_100:16384, DET_RANGE_VELOCITY_ERR_097:0, DET_RANGE_VELOCITY_ERR_098:0, DET_RANGE_VELOCITY_ERR_099:0, DET_RANGE_VELOCITY_ERR_100:0, DET_RCS_097:128, DET_RCS_098:128, DET_RCS_099:128, DET_RCS_100:128, DET_SNR_097:0, DET_SNR_098:0, DET_SNR_099:0, DET_SNR_100:0, DET_SUPER_RES_TARGET_097:0, DET_SUPER_RES_TARGET_098:0, DET_SUPER_RES_TARGET_099:0, DET_SUPER_RES_TARGET_100:0, DET_VALID_FLAG_097:0, DET_VALID_FLAG_098:0, DET_VALID_FLAG_099:0, DET_VALID_FLAG_100:0]}, provided-interface=Pi_SG_Detections_097_100
      Pp_SG_Detections_101_104: nonqueued-sender-com-spec{data-element=Vdp_SG_Detections_101_104, init-value=fields=[DET_AZIMUTH_101:0, DET_AZIMUTH_102:0, DET_AZIMUTH_103:0, DET_AZIMUTH_104:0, DET_AZIMUTH_ERR_101:0, DET_AZIMUTH_ERR_102:0, DET_AZIMUTH_ERR_103:0, DET_AZIMUTH_ERR_104:0, DET_BI_STATIC_FLAG_101:0, DET_BI_STATIC_FLAG_102:0, DET_BI_STATIC_FLAG_103:0, DET_BI_STATIC_FLAG_104:0, DET_CONFD_AZIMUTH_101:0, DET_CONFD_AZIMUTH_102:0, DET_CONFD_AZIMUTH_103:0, DET_CONFD_AZIMUTH_104:0, DET_CONFD_ELEVATION_101:0, DET_CONFD_ELEVATION_102:0, DET_CONFD_ELEVATION_103:0, DET_CONFD_ELEVATION_104:0, DET_ELEVATION_101:0, DET_ELEVATION_102:0, DET_ELEVATION_103:0, DET_ELEVATION_104:0, DET_ELEVATION_ERR_101:0, DET_ELEVATION_ERR_102:0, DET_ELEVATION_ERR_103:0, DET_ELEVATION_ERR_104:0, DET_EXISTENCE_PROB_101:0, DET_EXISTENCE_PROB_102:0, DET_EXISTENCE_PROB_103:0, DET_EXISTENCE_PROB_104:0, DET_HVC_FLAG_101:0, DET_HVC_FLAG_102:0, DET_HVC_FLAG_103:0, DET_HVC_FLAG_104:0, DET_MH_CRC16_101_104:0, DET_MH_CYCLE_COUNTER_101_104:0, DET_MH_SCAN_INDEX_4LSB_101_104:0, DET_OUTSIDE_SECTOR_101:0, DET_OUTSIDE_SECTOR_102:0, DET_OUTSIDE_SECTOR_103:0, DET_OUTSIDE_SECTOR_104:0, DET_POINT_TARGET_PROB_101:0, DET_POINT_TARGET_PROB_102:0, DET_POINT_TARGET_PROB_103:0, DET_POINT_TARGET_PROB_104:0, DET_RANGE_101:0, DET_RANGE_102:0, DET_RANGE_103:0, DET_RANGE_104:0, DET_RANGE_ERR_101:0, DET_RANGE_ERR_102:0, DET_RANGE_ERR_103:0, DET_RANGE_ERR_104:0, DET_RANGE_VELOCITY_101:16384, DET_RANGE_VELOCITY_102:16384, DET_RANGE_VELOCITY_103:16384, DET_RANGE_VELOCITY_104:16384, DET_RANGE_VELOCITY_ERR_101:0, DET_RANGE_VELOCITY_ERR_102:0, DET_RANGE_VELOCITY_ERR_103:0, DET_RANGE_VELOCITY_ERR_104:0, DET_RCS_101:128, DET_RCS_102:128, DET_RCS_103:128, DET_RCS_104:128, DET_SNR_101:0, DET_SNR_102:0, DET_SNR_103:0, DET_SNR_104:0, DET_SUPER_RES_TARGET_101:0, DET_SUPER_RES_TARGET_102:0, DET_SUPER_RES_TARGET_103:0, DET_SUPER_RES_TARGET_104:0, DET_VALID_FLAG_101:0, DET_VALID_FLAG_102:0, DET_VALID_FLAG_103:0, DET_VALID_FLAG_104:0]}, provided-interface=Pi_SG_Detections_101_104
      Pp_SG_Detections_105_108: nonqueued-sender-com-spec{data-element=Vdp_SG_Detections_105_108, init-value=fields=[DET_AZIMUTH_105:0, DET_AZIMUTH_106:0, DET_AZIMUTH_107:0, DET_AZIMUTH_108:0, DET_AZIMUTH_ERR_105:0, DET_AZIMUTH_ERR_106:0, DET_AZIMUTH_ERR_107:0, DET_AZIMUTH_ERR_108:0, DET_BI_STATIC_FLAG_105:0, DET_BI_STATIC_FLAG_106:0, DET_BI_STATIC_FLAG_107:0, DET_BI_STATIC_FLAG_108:0, DET_CONFD_AZIMUTH_105:0, DET_CONFD_AZIMUTH_106:0, DET_CONFD_AZIMUTH_107:0, DET_CONFD_AZIMUTH_108:0, DET_CONFD_ELEVATION_105:0, DET_CONFD_ELEVATION_106:0, DET_CONFD_ELEVATION_107:0, DET_CONFD_ELEVATION_108:0, DET_ELEVATION_105:0, DET_ELEVATION_106:0, DET_ELEVATION_107:0, DET_ELEVATION_108:0, DET_ELEVATION_ERR_105:0, DET_ELEVATION_ERR_106:0, DET_ELEVATION_ERR_107:0, DET_ELEVATION_ERR_108:0, DET_EXISTENCE_PROB_105:0, DET_EXISTENCE_PROB_106:0, DET_EXISTENCE_PROB_107:0, DET_EXISTENCE_PROB_108:0, DET_HVC_FLAG_105:0, DET_HVC_FLAG_106:0, DET_HVC_FLAG_107:0, DET_HVC_FLAG_108:0, DET_MH_CRC16_105_108:0, DET_MH_CYCLE_COUNTER_105_108:0, DET_MH_SCAN_INDEX_4LSB_105_108:0, DET_OUTSIDE_SECTOR_105:0, DET_OUTSIDE_SECTOR_106:0, DET_OUTSIDE_SECTOR_107:0, DET_OUTSIDE_SECTOR_108:0, DET_POINT_TARGET_PROB_105:0, DET_POINT_TARGET_PROB_106:0, DET_POINT_TARGET_PROB_107:0, DET_POINT_TARGET_PROB_108:0, DET_RANGE_105:0, DET_RANGE_106:0, DET_RANGE_107:0, DET_RANGE_108:0, DET_RANGE_ERR_105:0, DET_RANGE_ERR_106:0, DET_RANGE_ERR_107:0, DET_RANGE_ERR_108:0, DET_RANGE_VELOCITY_105:16384, DET_RANGE_VELOCITY_106:16384, DET_RANGE_VELOCITY_107:16384, DET_RANGE_VELOCITY_108:16384, DET_RANGE_VELOCITY_ERR_105:0, DET_RANGE_VELOCITY_ERR_106:0, DET_RANGE_VELOCITY_ERR_107:0, DET_RANGE_VELOCITY_ERR_108:0, DET_RCS_105:128, DET_RCS_106:128, DET_RCS_107:128, DET_RCS_108:128, DET_SNR_105:0, DET_SNR_106:0, DET_SNR_107:0, DET_SNR_108:0, DET_SUPER_RES_TARGET_105:0, DET_SUPER_RES_TARGET_106:0, DET_SUPER_RES_TARGET_107:0, DET_SUPER_RES_TARGET_108:0, DET_VALID_FLAG_105:0, DET_VALID_FLAG_106:0, DET_VALID_FLAG_107:0, DET_VALID_FLAG_108:0]}, provided-interface=Pi_SG_Detections_105_108
      Pp_SG_Detections_109_112: nonqueued-sender-com-spec{data-element=Vdp_SG_Detections_109_112, init-value=fields=[DET_AZIMUTH_109:0, DET_AZIMUTH_110:0, DET_AZIMUTH_111:0, DET_AZIMUTH_112:0, DET_AZIMUTH_ERR_109:0, DET_AZIMUTH_ERR_110:0, DET_AZIMUTH_ERR_111:0, DET_AZIMUTH_ERR_112:0, DET_BI_STATIC_FLAG_109:0, DET_BI_STATIC_FLAG_110:0, DET_BI_STATIC_FLAG_111:0, DET_BI_STATIC_FLAG_112:0, DET_CONFD_AZIMUTH_109:0, DET_CONFD_AZIMUTH_110:0, DET_CONFD_AZIMUTH_111:0, DET_CONFD_AZIMUTH_112:0, DET_CONFD_ELEVATION_109:0, DET_CONFD_ELEVATION_110:0, DET_CONFD_ELEVATION_111:0, DET_CONFD_ELEVATION_112:0, DET_ELEVATION_109:0, DET_ELEVATION_110:0, DET_ELEVATION_111:0, DET_ELEVATION_112:0, DET_ELEVATION_ERR_109:0, DET_ELEVATION_ERR_110:0, DET_ELEVATION_ERR_111:0, DET_ELEVATION_ERR_112:0, DET_EXISTENCE_PROB_109:0, DET_EXISTENCE_PROB_110:0, DET_EXISTENCE_PROB_111:0, DET_EXISTENCE_PROB_112:0, DET_HVC_FLAG_109:0, DET_HVC_FLAG_110:0, DET_HVC_FLAG_111:0, DET_HVC_FLAG_112:0, DET_MH_CRC16_109_112:0, DET_MH_CYCLE_COUNTER_109_112:0, DET_MH_SCAN_INDEX_4LSB_109_112:0, DET_OUTSIDE_SECTOR_109:0, DET_OUTSIDE_SECTOR_110:0, DET_OUTSIDE_SECTOR_111:0, DET_OUTSIDE_SECTOR_112:0, DET_POINT_TARGET_PROB_109:0, DET_POINT_TARGET_PROB_110:0, DET_POINT_TARGET_PROB_111:0, DET_POINT_TARGET_PROB_112:0, DET_RANGE_109:0, DET_RANGE_110:0, DET_RANGE_111:0, DET_RANGE_112:0, DET_RANGE_ERR_109:0, DET_RANGE_ERR_110:0, DET_RANGE_ERR_111:0, DET_RANGE_ERR_112:0, DET_RANGE_VELOCITY_109:16384, DET_RANGE_VELOCITY_110:16384, DET_RANGE_VELOCITY_111:16384, DET_RANGE_VELOCITY_112:16384, DET_RANGE_VELOCITY_ERR_109:0, DET_RANGE_VELOCITY_ERR_110:0, DET_RANGE_VELOCITY_ERR_111:0, DET_RANGE_VELOCITY_ERR_112:0, DET_RCS_109:128, DET_RCS_110:128, DET_RCS_111:128, DET_RCS_112:128, DET_SNR_109:0, DET_SNR_110:0, DET_SNR_111:0, DET_SNR_112:0, DET_SUPER_RES_TARGET_109:0, DET_SUPER_RES_TARGET_110:0, DET_SUPER_RES_TARGET_111:0, DET_SUPER_RES_TARGET_112:0, DET_VALID_FLAG_109:0, DET_VALID_FLAG_110:0, DET_VALID_FLAG_111:0, DET_VALID_FLAG_112:0]}, provided-interface=Pi_SG_Detections_109_112
      Pp_SG_Detections_113_116: nonqueued-sender-com-spec{data-element=Vdp_SG_Detections_113_116, init-value=fields=[DET_AZIMUTH_113:0, DET_AZIMUTH_114:0, DET_AZIMUTH_115:0, DET_AZIMUTH_116:0, DET_AZIMUTH_ERR_113:0, DET_AZIMUTH_ERR_114:0, DET_AZIMUTH_ERR_115:0, DET_AZIMUTH_ERR_116:0, DET_BI_STATIC_FLAG_113:0, DET_BI_STATIC_FLAG_114:0, DET_BI_STATIC_FLAG_115:0, DET_BI_STATIC_FLAG_116:0, DET_CONFD_AZIMUTH_113:0, DET_CONFD_AZIMUTH_114:0, DET_CONFD_AZIMUTH_115:0, DET_CONFD_AZIMUTH_116:0, DET_CONFD_ELEVATION_113:0, DET_CONFD_ELEVATION_114:0, DET_CONFD_ELEVATION_115:0, DET_CONFD_ELEVATION_116:0, DET_ELEVATION_113:0, DET_ELEVATION_114:0, DET_ELEVATION_115:0, DET_ELEVATION_116:0, DET_ELEVATION_ERR_113:0, DET_ELEVATION_ERR_114:0, DET_ELEVATION_ERR_115:0, DET_ELEVATION_ERR_116:0, DET_EXISTENCE_PROB_113:0, DET_EXISTENCE_PROB_114:0, DET_EXISTENCE_PROB_115:0, DET_EXISTENCE_PROB_116:0, DET_HVC_FLAG_113:0, DET_HVC_FLAG_114:0, DET_HVC_FLAG_115:0, DET_HVC_FLAG_116:0, DET_MH_CRC16_113_116:0, DET_MH_CYCLE_COUNTER_113_116:0, DET_MH_SCAN_INDEX_4LSB_113_116:0, DET_OUTSIDE_SECTOR_113:0, DET_OUTSIDE_SECTOR_114:0, DET_OUTSIDE_SECTOR_115:0, DET_OUTSIDE_SECTOR_116:0, DET_POINT_TARGET_PROB_113:0, DET_POINT_TARGET_PROB_114:0, DET_POINT_TARGET_PROB_115:0, DET_POINT_TARGET_PROB_116:0, DET_RANGE_113:0, DET_RANGE_114:0, DET_RANGE_115:0, DET_RANGE_116:0, DET_RANGE_ERR_113:0, DET_RANGE_ERR_114:0, DET_RANGE_ERR_115:0, DET_RANGE_ERR_116:0, DET_RANGE_VELOCITY_113:16384, DET_RANGE_VELOCITY_114:16384, DET_RANGE_VELOCITY_115:16384, DET_RANGE_VELOCITY_116:16384, DET_RANGE_VELOCITY_ERR_113:0, DET_RANGE_VELOCITY_ERR_114:0, DET_RANGE_VELOCITY_ERR_115:0, DET_RANGE_VELOCITY_ERR_116:0, DET_RCS_113:128, DET_RCS_114:128, DET_RCS_115:128, DET_RCS_116:128, DET_SNR_113:0, DET_SNR_114:0, DET_SNR_115:0, DET_SNR_116:0, DET_SUPER_RES_TARGET_113:0, DET_SUPER_RES_TARGET_114:0, DET_SUPER_RES_TARGET_115:0, DET_SUPER_RES_TARGET_116:0, DET_VALID_FLAG_113:0, DET_VALID_FLAG_114:0, DET_VALID_FLAG_115:0, DET_VALID_FLAG_116:0]}, provided-interface=Pi_SG_Detections_113_116
      Pp_SG_Detections_117_120: nonqueued-sender-com-spec{data-element=Vdp_SG_Detections_117_120, init-value=fields=[DET_AZIMUTH_117:0, DET_AZIMUTH_118:0, DET_AZIMUTH_119:0, DET_AZIMUTH_120:0, DET_AZIMUTH_ERR_117:0, DET_AZIMUTH_ERR_118:0, DET_AZIMUTH_ERR_119:0, DET_AZIMUTH_ERR_120:0, DET_BI_STATIC_FLAG_117:0, DET_BI_STATIC_FLAG_118:0, DET_BI_STATIC_FLAG_119:0, DET_BI_STATIC_FLAG_120:0, DET_CONFD_AZIMUTH_117:0, DET_CONFD_AZIMUTH_118:0, DET_CONFD_AZIMUTH_119:0, DET_CONFD_AZIMUTH_120:0, DET_CONFD_ELEVATION_117:0, DET_CONFD_ELEVATION_118:0, DET_CONFD_ELEVATION_119:0, DET_CONFD_ELEVATION_120:0, DET_ELEVATION_117:0, DET_ELEVATION_118:0, DET_ELEVATION_119:0, DET_ELEVATION_120:0, DET_ELEVATION_ERR_117:0, DET_ELEVATION_ERR_118:0, DET_ELEVATION_ERR_119:0, DET_ELEVATION_ERR_120:0, DET_EXISTENCE_PROB_117:0, DET_EXISTENCE_PROB_118:0, DET_EXISTENCE_PROB_119:0, DET_EXISTENCE_PROB_120:0, DET_HVC_FLAG_117:0, DET_HVC_FLAG_118:0, DET_HVC_FLAG_119:0, DET_HVC_FLAG_120:0, DET_MH_CRC16_117_120:0, DET_MH_CYCLE_COUNTER_117_120:0, DET_MH_SCAN_INDEX_4LSB_117_120:0, DET_OUTSIDE_SECTOR_117:0, DET_OUTSIDE_SECTOR_118:0, DET_OUTSIDE_SECTOR_119:0, DET_OUTSIDE_SECTOR_120:0, DET_POINT_TARGET_PROB_117:0, DET_POINT_TARGET_PROB_118:0, DET_POINT_TARGET_PROB_119:0, DET_POINT_TARGET_PROB_120:0, DET_RANGE_117:0, DET_RANGE_118:0, DET_RANGE_119:0, DET_RANGE_120:0, DET_RANGE_ERR_117:0, DET_RANGE_ERR_118:0, DET_RANGE_ERR_119:0, DET_RANGE_ERR_120:0, DET_RANGE_VELOCITY_117:16384, DET_RANGE_VELOCITY_118:16384, DET_RANGE_VELOCITY_119:16384, DET_RANGE_VELOCITY_120:16384, DET_RANGE_VELOCITY_ERR_117:0, DET_RANGE_VELOCITY_ERR_118:0, DET_RANGE_VELOCITY_ERR_119:0, DET_RANGE_VELOCITY_ERR_120:0, DET_RCS_117:128, DET_RCS_118:128, DET_RCS_119:128, DET_RCS_120:128, DET_SNR_117:0, DET_SNR_118:0, DET_SNR_119:0, DET_SNR_120:0, DET_SUPER_RES_TARGET_117:0, DET_SUPER_RES_TARGET_118:0, DET_SUPER_RES_TARGET_119:0, DET_SUPER_RES_TARGET_120:0, DET_VALID_FLAG_117:0, DET_VALID_FLAG_118:0, DET_VALID_FLAG_119:0, DET_VALID_FLAG_120:0]}, provided-interface=Pi_SG_Detections_117_120
      Pp_SG_Detections_121_124: nonqueued-sender-com-spec{data-element=Vdp_SG_Detections_121_124, init-value=fields=[DET_AZIMUTH_121:0, DET_AZIMUTH_122:0, DET_AZIMUTH_123:0, DET_AZIMUTH_124:0, DET_AZIMUTH_ERR_121:0, DET_AZIMUTH_ERR_122:0, DET_AZIMUTH_ERR_123:0, DET_AZIMUTH_ERR_124:0, DET_BI_STATIC_FLAG_121:0, DET_BI_STATIC_FLAG_122:0, DET_BI_STATIC_FLAG_123:0, DET_BI_STATIC_FLAG_124:0, DET_CONFD_AZIMUTH_121:0, DET_CONFD_AZIMUTH_122:0, DET_CONFD_AZIMUTH_123:0, DET_CONFD_AZIMUTH_124:0, DET_CONFD_ELEVATION_121:0, DET_CONFD_ELEVATION_122:0, DET_CONFD_ELEVATION_123:0, DET_CONFD_ELEVATION_124:0, DET_ELEVATION_121:0, DET_ELEVATION_122:0, DET_ELEVATION_123:0, DET_ELEVATION_124:0, DET_ELEVATION_ERR_121:0, DET_ELEVATION_ERR_122:0, DET_ELEVATION_ERR_123:0, DET_ELEVATION_ERR_124:0, DET_EXISTENCE_PROB_121:0, DET_EXISTENCE_PROB_122:0, DET_EXISTENCE_PROB_123:0, DET_EXISTENCE_PROB_124:0, DET_HVC_FLAG_121:0, DET_HVC_FLAG_122:0, DET_HVC_FLAG_123:0, DET_HVC_FLAG_124:0, DET_MH_CRC16_121_124:0, DET_MH_CYCLE_COUNTER_121_124:0, DET_MH_SCAN_INDEX_4LSB_121_124:0, DET_OUTSIDE_SECTOR_121:0, DET_OUTSIDE_SECTOR_122:0, DET_OUTSIDE_SECTOR_123:0, DET_OUTSIDE_SECTOR_124:0, DET_POINT_TARGET_PROB_121:0, DET_POINT_TARGET_PROB_122:0, DET_POINT_TARGET_PROB_123:0, DET_POINT_TARGET_PROB_124:0, DET_RANGE_121:0, DET_RANGE_122:0, DET_RANGE_123:0, DET_RANGE_124:0, DET_RANGE_ERR_121:0, DET_RANGE_ERR_122:0, DET_RANGE_ERR_123:0, DET_RANGE_ERR_124:0, DET_RANGE_VELOCITY_121:16384, DET_RANGE_VELOCITY_122:16384, DET_RANGE_VELOCITY_123:16384, DET_RANGE_VELOCITY_124:16384, DET_RANGE_VELOCITY_ERR_121:0, DET_RANGE_VELOCITY_ERR_122:0, DET_RANGE_VELOCITY_ERR_123:0, DET_RANGE_VELOCITY_ERR_124:0, DET_RCS_121:128, DET_RCS_122:128, DET_RCS_123:128, DET_RCS_124:128, DET_SNR_121:0, DET_SNR_122:0, DET_SNR_123:0, DET_SNR_124:0, DET_SUPER_RES_TARGET_121:0, DET_SUPER_RES_TARGET_122:0, DET_SUPER_RES_TARGET_123:0, DET_SUPER_RES_TARGET_124:0, DET_VALID_FLAG_121:0, DET_VALID_FLAG_122:0, DET_VALID_FLAG_123:0, DET_VALID_FLAG_124:0]}, provided-interface=Pi_SG_Detections_121_124
      Pp_SG_Detections_125_128: nonqueued-sender-com-spec{data-element=Vdp_SG_Detections_125_128, init-value=fields=[DET_AZIMUTH_125:0, DET_AZIMUTH_126:0, DET_AZIMUTH_127:0, DET_AZIMUTH_128:0, DET_AZIMUTH_ERR_125:0, DET_AZIMUTH_ERR_126:0, DET_AZIMUTH_ERR_127:0, DET_AZIMUTH_ERR_128:0, DET_BI_STATIC_FLAG_125:0, DET_BI_STATIC_FLAG_126:0, DET_BI_STATIC_FLAG_127:0, DET_BI_STATIC_FLAG_128:0, DET_CONFD_AZIMUTH_125:0, DET_CONFD_AZIMUTH_126:0, DET_CONFD_AZIMUTH_127:0, DET_CONFD_AZIMUTH_128:0, DET_CONFD_ELEVATION_125:0, DET_CONFD_ELEVATION_126:0, DET_CONFD_ELEVATION_127:0, DET_CONFD_ELEVATION_128:0, DET_ELEVATION_125:0, DET_ELEVATION_126:0, DET_ELEVATION_127:0, DET_ELEVATION_128:0, DET_ELEVATION_ERR_125:0, DET_ELEVATION_ERR_126:0, DET_ELEVATION_ERR_127:0, DET_ELEVATION_ERR_128:0, DET_EXISTENCE_PROB_125:0, DET_EXISTENCE_PROB_126:0, DET_EXISTENCE_PROB_127:0, DET_EXISTENCE_PROB_128:0, DET_HVC_FLAG_125:0, DET_HVC_FLAG_126:0, DET_HVC_FLAG_127:0, DET_HVC_FLAG_128:0, DET_MH_CRC16_125_128:0, DET_MH_CYCLE_COUNTER_125_128:0, DET_MH_SCAN_INDEX_4LSB_125_128:0, DET_OUTSIDE_SECTOR_125:0, DET_OUTSIDE_SECTOR_126:0, DET_OUTSIDE_SECTOR_127:0, DET_OUTSIDE_SECTOR_128:0, DET_POINT_TARGET_PROB_125:0, DET_POINT_TARGET_PROB_126:0, DET_POINT_TARGET_PROB_127:0, DET_POINT_TARGET_PROB_128:0, DET_RANGE_125:0, DET_RANGE_126:0, DET_RANGE_127:0, DET_RANGE_128:0, DET_RANGE_ERR_125:0, DET_RANGE_ERR_126:0, DET_RANGE_ERR_127:0, DET_RANGE_ERR_128:0, DET_RANGE_VELOCITY_125:16384, DET_RANGE_VELOCITY_126:16384, DET_RANGE_VELOCITY_127:16384, DET_RANGE_VELOCITY_128:16384, DET_RANGE_VELOCITY_ERR_125:0, DET_RANGE_VELOCITY_ERR_126:0, DET_RANGE_VELOCITY_ERR_127:0, DET_RANGE_VELOCITY_ERR_128:0, DET_RCS_125:128, DET_RCS_126:128, DET_RCS_127:128, DET_RCS_128:128, DET_SNR_125:0, DET_SNR_126:0, DET_SNR_127:0, DET_SNR_128:0, DET_SUPER_RES_TARGET_125:0, DET_SUPER_RES_TARGET_126:0, DET_SUPER_RES_TARGET_127:0, DET_SUPER_RES_TARGET_128:0, DET_VALID_FLAG_125:0, DET_VALID_FLAG_126:0, DET_VALID_FLAG_127:0, DET_VALID_FLAG_128:0]}, provided-interface=Pi_SG_Detections_125_128
      Pp_SG_Detections_129_132: nonqueued-sender-com-spec{data-element=Vdp_SG_Detections_129_132, init-value=fields=[DET_AZIMUTH_129:0, DET_AZIMUTH_130:0, DET_AZIMUTH_131:0, DET_AZIMUTH_132:0, DET_AZIMUTH_ERR_129:0, DET_AZIMUTH_ERR_130:0, DET_AZIMUTH_ERR_131:0, DET_AZIMUTH_ERR_132:0, DET_BI_STATIC_FLAG_129:0, DET_BI_STATIC_FLAG_130:0, DET_BI_STATIC_FLAG_131:0, DET_BI_STATIC_FLAG_132:0, DET_CONFD_AZIMUTH_129:0, DET_CONFD_AZIMUTH_130:0, DET_CONFD_AZIMUTH_131:0, DET_CONFD_AZIMUTH_132:0, DET_CONFD_ELEVATION_129:0, DET_CONFD_ELEVATION_130:0, DET_CONFD_ELEVATION_131:0, DET_CONFD_ELEVATION_132:0, DET_ELEVATION_129:0, DET_ELEVATION_130:0, DET_ELEVATION_131:0, DET_ELEVATION_132:0, DET_ELEVATION_ERR_129:0, DET_ELEVATION_ERR_130:0, DET_ELEVATION_ERR_131:0, DET_ELEVATION_ERR_132:0, DET_EXISTENCE_PROB_129:0, DET_EXISTENCE_PROB_130:0, DET_EXISTENCE_PROB_131:0, DET_EXISTENCE_PROB_132:0, DET_HVC_FLAG_129:0, DET_HVC_FLAG_130:0, DET_HVC_FLAG_131:0, DET_HVC_FLAG_132:0, DET_MH_CRC16_129_132:0, DET_MH_CYCLE_COUNTER_129_132:0, DET_MH_SCAN_INDEX_4LSB_129_132:0, DET_OUTSIDE_SECTOR_129:0, DET_OUTSIDE_SECTOR_130:0, DET_OUTSIDE_SECTOR_131:0, DET_OUTSIDE_SECTOR_132:0, DET_POINT_TARGET_PROB_129:0, DET_POINT_TARGET_PROB_130:0, DET_POINT_TARGET_PROB_131:0, DET_POINT_TARGET_PROB_132:0, DET_RANGE_129:0, DET_RANGE_130:0, DET_RANGE_131:0, DET_RANGE_132:0, DET_RANGE_ERR_129:0, DET_RANGE_ERR_130:0, DET_RANGE_ERR_131:0, DET_RANGE_ERR_132:0, DET_RANGE_VELOCITY_129:16384, DET_RANGE_VELOCITY_130:16384, DET_RANGE_VELOCITY_131:16384, DET_RANGE_VELOCITY_132:16384, DET_RANGE_VELOCITY_ERR_129:0, DET_RANGE_VELOCITY_ERR_130:0, DET_RANGE_VELOCITY_ERR_131:0, DET_RANGE_VELOCITY_ERR_132:0, DET_RCS_129:128, DET_RCS_130:128, DET_RCS_131:128, DET_RCS_132:128, DET_SNR_129:0, DET_SNR_130:0, DET_SNR_131:0, DET_SNR_132:0, DET_SUPER_RES_TARGET_129:0, DET_SUPER_RES_TARGET_130:0, DET_SUPER_RES_TARGET_131:0, DET_SUPER_RES_TARGET_132:0, DET_VALID_FLAG_129:0, DET_VALID_FLAG_130:0, DET_VALID_FLAG_131:0, DET_VALID_FLAG_132:0]}, provided-interface=Pi_SG_Detections_129_132
      Pp_SG_Detections_133_136: nonqueued-sender-com-spec{data-element=Vdp_SG_Detections_133_136, init-value=fields=[DET_AZIMUTH_133:0, DET_AZIMUTH_134:0, DET_AZIMUTH_135:0, DET_AZIMUTH_136:0, DET_AZIMUTH_ERR_133:0, DET_AZIMUTH_ERR_134:0, DET_AZIMUTH_ERR_135:0, DET_AZIMUTH_ERR_136:0, DET_BI_STATIC_FLAG_133:0, DET_BI_STATIC_FLAG_134:0, DET_BI_STATIC_FLAG_135:0, DET_BI_STATIC_FLAG_136:0, DET_CONFD_AZIMUTH_133:0, DET_CONFD_AZIMUTH_134:0, DET_CONFD_AZIMUTH_135:0, DET_CONFD_AZIMUTH_136:0, DET_CONFD_ELEVATION_133:0, DET_CONFD_ELEVATION_134:0, DET_CONFD_ELEVATION_135:0, DET_CONFD_ELEVATION_136:0, DET_ELEVATION_133:0, DET_ELEVATION_134:0, DET_ELEVATION_135:0, DET_ELEVATION_136:0, DET_ELEVATION_ERR_133:0, DET_ELEVATION_ERR_134:0, DET_ELEVATION_ERR_135:0, DET_ELEVATION_ERR_136:0, DET_EXISTENCE_PROB_133:0, DET_EXISTENCE_PROB_134:0, DET_EXISTENCE_PROB_135:0, DET_EXISTENCE_PROB_136:0, DET_HVC_FLAG_133:0, DET_HVC_FLAG_134:0, DET_HVC_FLAG_135:0, DET_HVC_FLAG_136:0, DET_MH_CRC16_133_136:0, DET_MH_CYCLE_COUNTER_133_136:0, DET_MH_SCAN_INDEX_4LSB_133_136:0, DET_OUTSIDE_SECTOR_133:0, DET_OUTSIDE_SECTOR_134:0, DET_OUTSIDE_SECTOR_135:0, DET_OUTSIDE_SECTOR_136:0, DET_POINT_TARGET_PROB_133:0, DET_POINT_TARGET_PROB_134:0, DET_POINT_TARGET_PROB_135:0, DET_POINT_TARGET_PROB_136:0, DET_RANGE_133:0, DET_RANGE_134:0, DET_RANGE_135:0, DET_RANGE_136:0, DET_RANGE_ERR_133:0, DET_RANGE_ERR_134:0, DET_RANGE_ERR_135:0, DET_RANGE_ERR_136:0, DET_RANGE_VELOCITY_133:16384, DET_RANGE_VELOCITY_134:16384, DET_RANGE_VELOCITY_135:16384, DET_RANGE_VELOCITY_136:16384, DET_RANGE_VELOCITY_ERR_133:0, DET_RANGE_VELOCITY_ERR_134:0, DET_RANGE_VELOCITY_ERR_135:0, DET_RANGE_VELOCITY_ERR_136:0, DET_RCS_133:128, DET_RCS_134:128, DET_RCS_135:128, DET_RCS_136:128, DET_SNR_133:0, DET_SNR_134:0, DET_SNR_135:0, DET_SNR_136:0, DET_SUPER_RES_TARGET_133:0, DET_SUPER_RES_TARGET_134:0, DET_SUPER_RES_TARGET_135:0, DET_SUPER_RES_TARGET_136:0, DET_VALID_FLAG_133:0, DET_VALID_FLAG_134:0, DET_VALID_FLAG_135:0, DET_VALID_FLAG_136:0]}, provided-interface=Pi_SG_Detections_133_136
      Pp_SG_Detections_137_140: nonqueued-sender-com-spec{data-element=Vdp_SG_Detections_137_140, init-value=fields=[DET_AZIMUTH_137:0, DET_AZIMUTH_138:0, DET_AZIMUTH_139:0, DET_AZIMUTH_140:0, DET_AZIMUTH_ERR_137:0, DET_AZIMUTH_ERR_138:0, DET_AZIMUTH_ERR_139:0, DET_AZIMUTH_ERR_140:0, DET_BI_STATIC_FLAG_137:0, DET_BI_STATIC_FLAG_138:0, DET_BI_STATIC_FLAG_139:0, DET_BI_STATIC_FLAG_140:0, DET_CONFD_AZIMUTH_137:0, DET_CONFD_AZIMUTH_138:0, DET_CONFD_AZIMUTH_139:0, DET_CONFD_AZIMUTH_140:0, DET_CONFD_ELEVATION_137:0, DET_CONFD_ELEVATION_138:0, DET_CONFD_ELEVATION_139:0, DET_CONFD_ELEVATION_140:0, DET_ELEVATION_137:0, DET_ELEVATION_138:0, DET_ELEVATION_139:0, DET_ELEVATION_140:0, DET_ELEVATION_ERR_137:0, DET_ELEVATION_ERR_138:0, DET_ELEVATION_ERR_139:0, DET_ELEVATION_ERR_140:0, DET_EXISTENCE_PROB_137:0, DET_EXISTENCE_PROB_138:0, DET_EXISTENCE_PROB_139:0, DET_EXISTENCE_PROB_140:0, DET_HVC_FLAG_137:0, DET_HVC_FLAG_138:0, DET_HVC_FLAG_139:0, DET_HVC_FLAG_140:0, DET_MH_CRC16_137_140:0, DET_MH_CYCLE_COUNTER_137_140:0, DET_MH_SCAN_INDEX_4LSB_137_140:0, DET_OUTSIDE_SECTOR_137:0, DET_OUTSIDE_SECTOR_138:0, DET_OUTSIDE_SECTOR_139:0, DET_OUTSIDE_SECTOR_140:0, DET_POINT_TARGET_PROB_137:0, DET_POINT_TARGET_PROB_138:0, DET_POINT_TARGET_PROB_139:0, DET_POINT_TARGET_PROB_140:0, DET_RANGE_137:0, DET_RANGE_138:0, DET_RANGE_139:0, DET_RANGE_140:0, DET_RANGE_ERR_137:0, DET_RANGE_ERR_138:0, DET_RANGE_ERR_139:0, DET_RANGE_ERR_140:0, DET_RANGE_VELOCITY_137:16384, DET_RANGE_VELOCITY_138:16384, DET_RANGE_VELOCITY_139:16384, DET_RANGE_VELOCITY_140:16384, DET_RANGE_VELOCITY_ERR_137:0, DET_RANGE_VELOCITY_ERR_138:0, DET_RANGE_VELOCITY_ERR_139:0, DET_RANGE_VELOCITY_ERR_140:0, DET_RCS_137:128, DET_RCS_138:128, DET_RCS_139:128, DET_RCS_140:128, DET_SNR_137:0, DET_SNR_138:0, DET_SNR_139:0, DET_SNR_140:0, DET_SUPER_RES_TARGET_137:0, DET_SUPER_RES_TARGET_138:0, DET_SUPER_RES_TARGET_139:0, DET_SUPER_RES_TARGET_140:0, DET_VALID_FLAG_137:0, DET_VALID_FLAG_138:0, DET_VALID_FLAG_139:0, DET_VALID_FLAG_140:0]}, provided-interface=Pi_SG_Detections_137_140
      Pp_SG_Detections_141_144: nonqueued-sender-com-spec{data-element=Vdp_SG_Detections_141_144, init-value=fields=[DET_AZIMUTH_141:0, DET_AZIMUTH_142:0, DET_AZIMUTH_143:0, DET_AZIMUTH_144:0, DET_AZIMUTH_ERR_141:0, DET_AZIMUTH_ERR_142:0, DET_AZIMUTH_ERR_143:0, DET_AZIMUTH_ERR_144:0, DET_BI_STATIC_FLAG_141:0, DET_BI_STATIC_FLAG_142:0, DET_BI_STATIC_FLAG_143:0, DET_BI_STATIC_FLAG_144:0, DET_CONFD_AZIMUTH_141:0, DET_CONFD_AZIMUTH_142:0, DET_CONFD_AZIMUTH_143:0, DET_CONFD_AZIMUTH_144:0, DET_CONFD_ELEVATION_141:0, DET_CONFD_ELEVATION_142:0, DET_CONFD_ELEVATION_143:0, DET_CONFD_ELEVATION_144:0, DET_ELEVATION_141:0, DET_ELEVATION_142:0, DET_ELEVATION_143:0, DET_ELEVATION_144:0, DET_ELEVATION_ERR_141:0, DET_ELEVATION_ERR_142:0, DET_ELEVATION_ERR_143:0, DET_ELEVATION_ERR_144:0, DET_EXISTENCE_PROB_141:0, DET_EXISTENCE_PROB_142:0, DET_EXISTENCE_PROB_143:0, DET_EXISTENCE_PROB_144:0, DET_HVC_FLAG_141:0, DET_HVC_FLAG_142:0, DET_HVC_FLAG_143:0, DET_HVC_FLAG_144:0, DET_MH_CRC16_141_144:0, DET_MH_CYCLE_COUNTER_141_144:0, DET_MH_SCAN_INDEX_4LSB_141_144:0, DET_OUTSIDE_SECTOR_141:0, DET_OUTSIDE_SECTOR_142:0, DET_OUTSIDE_SECTOR_143:0, DET_OUTSIDE_SECTOR_144:0, DET_POINT_TARGET_PROB_141:0, DET_POINT_TARGET_PROB_142:0, DET_POINT_TARGET_PROB_143:0, DET_POINT_TARGET_PROB_144:0, DET_RANGE_141:0, DET_RANGE_142:0, DET_RANGE_143:0, DET_RANGE_144:0, DET_RANGE_ERR_141:0, DET_RANGE_ERR_142:0, DET_RANGE_ERR_143:0, DET_RANGE_ERR_144:0, DET_RANGE_VELOCITY_141:16384, DET_RANGE_VELOCITY_142:16384, DET_RANGE_VELOCITY_143:16384, DET_RANGE_VELOCITY_144:16384, DET_RANGE_VELOCITY_ERR_141:0, DET_RANGE_VELOCITY_ERR_142:0, DET_RANGE_VELOCITY_ERR_143:0, DET_RANGE_VELOCITY_ERR_144:0, DET_RCS_141:128, DET_RCS_142:128, DET_RCS_143:128, DET_RCS_144:128, DET_SNR_141:0, DET_SNR_142:0, DET_SNR_143:0, DET_SNR_144:0, DET_SUPER_RES_TARGET_141:0, DET_SUPER_RES_TARGET_142:0, DET_SUPER_RES_TARGET_143:0, DET_SUPER_RES_TARGET_144:0, DET_VALID_FLAG_141:0, DET_VALID_FLAG_142:0, DET_VALID_FLAG_143:0, DET_VALID_FLAG_144:0]}, provided-interface=Pi_SG_Detections_141_144
      Pp_SG_Detections_145_148: nonqueued-sender-com-spec{data-element=Vdp_SG_Detections_145_148, init-value=fields=[DET_AZIMUTH_145:0, DET_AZIMUTH_146:0, DET_AZIMUTH_147:0, DET_AZIMUTH_148:0, DET_AZIMUTH_ERR_145:0, DET_AZIMUTH_ERR_146:0, DET_AZIMUTH_ERR_147:0, DET_AZIMUTH_ERR_148:0, DET_BI_STATIC_FLAG_145:0, DET_BI_STATIC_FLAG_146:0, DET_BI_STATIC_FLAG_147:0, DET_BI_STATIC_FLAG_148:0, DET_CONFD_AZIMUTH_145:0, DET_CONFD_AZIMUTH_146:0, DET_CONFD_AZIMUTH_147:0, DET_CONFD_AZIMUTH_148:0, DET_CONFD_ELEVATION_145:0, DET_CONFD_ELEVATION_146:0, DET_CONFD_ELEVATION_147:0, DET_CONFD_ELEVATION_148:0, DET_ELEVATION_145:0, DET_ELEVATION_146:0, DET_ELEVATION_147:0, DET_ELEVATION_148:0, DET_ELEVATION_ERR_145:0, DET_ELEVATION_ERR_146:0, DET_ELEVATION_ERR_147:0, DET_ELEVATION_ERR_148:0, DET_EXISTENCE_PROB_145:0, DET_EXISTENCE_PROB_146:0, DET_EXISTENCE_PROB_147:0, DET_EXISTENCE_PROB_148:0, DET_HVC_FLAG_145:0, DET_HVC_FLAG_146:0, DET_HVC_FLAG_147:0, DET_HVC_FLAG_148:0, DET_MH_CRC16_145_148:0, DET_MH_CYCLE_COUNTER_145_148:0, DET_MH_SCAN_INDEX_4LSB_145_148:0, DET_OUTSIDE_SECTOR_145:0, DET_OUTSIDE_SECTOR_146:0, DET_OUTSIDE_SECTOR_147:0, DET_OUTSIDE_SECTOR_148:0, DET_POINT_TARGET_PROB_145:0, DET_POINT_TARGET_PROB_146:0, DET_POINT_TARGET_PROB_147:0, DET_POINT_TARGET_PROB_148:0, DET_RANGE_145:0, DET_RANGE_146:0, DET_RANGE_147:0, DET_RANGE_148:0, DET_RANGE_ERR_145:0, DET_RANGE_ERR_146:0, DET_RANGE_ERR_147:0, DET_RANGE_ERR_148:0, DET_RANGE_VELOCITY_145:16384, DET_RANGE_VELOCITY_146:16384, DET_RANGE_VELOCITY_147:16384, DET_RANGE_VELOCITY_148:16384, DET_RANGE_VELOCITY_ERR_145:0, DET_RANGE_VELOCITY_ERR_146:0, DET_RANGE_VELOCITY_ERR_147:0, DET_RANGE_VELOCITY_ERR_148:0, DET_RCS_145:128, DET_RCS_146:128, DET_RCS_147:128, DET_RCS_148:128, DET_SNR_145:0, DET_SNR_146:0, DET_SNR_147:0, DET_SNR_148:0, DET_SUPER_RES_TARGET_145:0, DET_SUPER_RES_TARGET_146:0, DET_SUPER_RES_TARGET_147:0, DET_SUPER_RES_TARGET_148:0, DET_VALID_FLAG_145:0, DET_VALID_FLAG_146:0, DET_VALID_FLAG_147:0, DET_VALID_FLAG_148:0]}, provided-interface=Pi_SG_Detections_145_148
      Pp_SG_Detections_149_152: nonqueued-sender-com-spec{data-element=Vdp_SG_Detections_149_152, init-value=fields=[DET_AZIMUTH_149:0, DET_AZIMUTH_150:0, DET_AZIMUTH_151:0, DET_AZIMUTH_152:0, DET_AZIMUTH_ERR_149:0, DET_AZIMUTH_ERR_150:0, DET_AZIMUTH_ERR_151:0, DET_AZIMUTH_ERR_152:0, DET_BI_STATIC_FLAG_149:0, DET_BI_STATIC_FLAG_150:0, DET_BI_STATIC_FLAG_151:0, DET_BI_STATIC_FLAG_152:0, DET_CONFD_AZIMUTH_149:0, DET_CONFD_AZIMUTH_150:0, DET_CONFD_AZIMUTH_151:0, DET_CONFD_AZIMUTH_152:0, DET_CONFD_ELEVATION_149:0, DET_CONFD_ELEVATION_150:0, DET_CONFD_ELEVATION_151:0, DET_CONFD_ELEVATION_152:0, DET_ELEVATION_149:0, DET_ELEVATION_150:0, DET_ELEVATION_151:0, DET_ELEVATION_152:0, DET_ELEVATION_ERR_149:0, DET_ELEVATION_ERR_150:0, DET_ELEVATION_ERR_151:0, DET_ELEVATION_ERR_152:0, DET_EXISTENCE_PROB_149:0, DET_EXISTENCE_PROB_150:0, DET_EXISTENCE_PROB_151:0, DET_EXISTENCE_PROB_152:0, DET_HVC_FLAG_149:0, DET_HVC_FLAG_150:0, DET_HVC_FLAG_151:0, DET_HVC_FLAG_152:0, DET_MH_CRC16_149_152:0, DET_MH_CYCLE_COUNTER_149_152:0, DET_MH_SCAN_INDEX_4LSB_149_152:0, DET_OUTSIDE_SECTOR_149:0, DET_OUTSIDE_SECTOR_150:0, DET_OUTSIDE_SECTOR_151:0, DET_OUTSIDE_SECTOR_152:0, DET_POINT_TARGET_PROB_149:0, DET_POINT_TARGET_PROB_150:0, DET_POINT_TARGET_PROB_151:0, DET_POINT_TARGET_PROB_152:0, DET_RANGE_149:0, DET_RANGE_150:0, DET_RANGE_151:0, DET_RANGE_152:0, DET_RANGE_ERR_149:0, DET_RANGE_ERR_150:0, DET_RANGE_ERR_151:0, DET_RANGE_ERR_152:0, DET_RANGE_VELOCITY_149:16384, DET_RANGE_VELOCITY_150:16384, DET_RANGE_VELOCITY_151:16384, DET_RANGE_VELOCITY_152:16384, DET_RANGE_VELOCITY_ERR_149:0, DET_RANGE_VELOCITY_ERR_150:0, DET_RANGE_VELOCITY_ERR_151:0, DET_RANGE_VELOCITY_ERR_152:0, DET_RCS_149:128, DET_RCS_150:128, DET_RCS_151:128, DET_RCS_152:128, DET_SNR_149:0, DET_SNR_150:0, DET_SNR_151:0, DET_SNR_152:0, DET_SUPER_RES_TARGET_149:0, DET_SUPER_RES_TARGET_150:0, DET_SUPER_RES_TARGET_151:0, DET_SUPER_RES_TARGET_152:0, DET_VALID_FLAG_149:0, DET_VALID_FLAG_150:0, DET_VALID_FLAG_151:0, DET_VALID_FLAG_152:0]}, provided-interface=Pi_SG_Detections_149_152
      Pp_SG_Detections_153_156: nonqueued-sender-com-spec{data-element=Vdp_SG_Detections_153_156, init-value=fields=[DET_AZIMUTH_153:0, DET_AZIMUTH_154:0, DET_AZIMUTH_155:0, DET_AZIMUTH_156:0, DET_AZIMUTH_ERR_153:0, DET_AZIMUTH_ERR_154:0, DET_AZIMUTH_ERR_155:0, DET_AZIMUTH_ERR_156:0, DET_BI_STATIC_FLAG_153:0, DET_BI_STATIC_FLAG_154:0, DET_BI_STATIC_FLAG_155:0, DET_BI_STATIC_FLAG_156:0, DET_CONFD_AZIMUTH_153:0, DET_CONFD_AZIMUTH_154:0, DET_CONFD_AZIMUTH_155:0, DET_CONFD_AZIMUTH_156:0, DET_CONFD_ELEVATION_153:0, DET_CONFD_ELEVATION_154:0, DET_CONFD_ELEVATION_155:0, DET_CONFD_ELEVATION_156:0, DET_ELEVATION_153:0, DET_ELEVATION_154:0, DET_ELEVATION_155:0, DET_ELEVATION_156:0, DET_ELEVATION_ERR_153:0, DET_ELEVATION_ERR_154:0, DET_ELEVATION_ERR_155:0, DET_ELEVATION_ERR_156:0, DET_EXISTENCE_PROB_153:0, DET_EXISTENCE_PROB_154:0, DET_EXISTENCE_PROB_155:0, DET_EXISTENCE_PROB_156:0, DET_HVC_FLAG_153:0, DET_HVC_FLAG_154:0, DET_HVC_FLAG_155:0, DET_HVC_FLAG_156:0, DET_MH_CRC16_153_156:0, DET_MH_CYCLE_COUNTER_153_156:0, DET_MH_SCAN_INDEX_4LSB_153_156:0, DET_OUTSIDE_SECTOR_153:0, DET_OUTSIDE_SECTOR_154:0, DET_OUTSIDE_SECTOR_155:0, DET_OUTSIDE_SECTOR_156:0, DET_POINT_TARGET_PROB_153:0, DET_POINT_TARGET_PROB_154:0, DET_POINT_TARGET_PROB_155:0, DET_POINT_TARGET_PROB_156:0, DET_RANGE_153:0, DET_RANGE_154:0, DET_RANGE_155:0, DET_RANGE_156:0, DET_RANGE_ERR_153:0, DET_RANGE_ERR_154:0, DET_RANGE_ERR_155:0, DET_RANGE_ERR_156:0, DET_RANGE_VELOCITY_153:16384, DET_RANGE_VELOCITY_154:16384, DET_RANGE_VELOCITY_155:16384, DET_RANGE_VELOCITY_156:16384, DET_RANGE_VELOCITY_ERR_153:0, DET_RANGE_VELOCITY_ERR_154:0, DET_RANGE_VELOCITY_ERR_155:0, DET_RANGE_VELOCITY_ERR_156:0, DET_RCS_153:128, DET_RCS_154:128, DET_RCS_155:128, DET_RCS_156:128, DET_SNR_153:0, DET_SNR_154:0, DET_SNR_155:0, DET_SNR_156:0, DET_SUPER_RES_TARGET_153:0, DET_SUPER_RES_TARGET_154:0, DET_SUPER_RES_TARGET_155:0, DET_SUPER_RES_TARGET_156:0, DET_VALID_FLAG_153:0, DET_VALID_FLAG_154:0, DET_VALID_FLAG_155:0, DET_VALID_FLAG_156:0]}, provided-interface=Pi_SG_Detections_153_156
      Pp_SG_Detections_157_160: nonqueued-sender-com-spec{data-element=Vdp_SG_Detections_157_160, init-value=fields=[DET_AZIMUTH_157:0, DET_AZIMUTH_158:0, DET_AZIMUTH_159:0, DET_AZIMUTH_160:0, DET_AZIMUTH_ERR_157:0, DET_AZIMUTH_ERR_158:0, DET_AZIMUTH_ERR_159:0, DET_AZIMUTH_ERR_160:0, DET_BI_STATIC_FLAG_157:0, DET_BI_STATIC_FLAG_158:0, DET_BI_STATIC_FLAG_159:0, DET_BI_STATIC_FLAG_160:0, DET_CONFD_AZIMUTH_157:0, DET_CONFD_AZIMUTH_158:0, DET_CONFD_AZIMUTH_159:0, DET_CONFD_AZIMUTH_160:0, DET_CONFD_ELEVATION_157:0, DET_CONFD_ELEVATION_158:0, DET_CONFD_ELEVATION_159:0, DET_CONFD_ELEVATION_160:0, DET_ELEVATION_157:0, DET_ELEVATION_158:0, DET_ELEVATION_159:0, DET_ELEVATION_160:0, DET_ELEVATION_ERR_157:0, DET_ELEVATION_ERR_158:0, DET_ELEVATION_ERR_159:0, DET_ELEVATION_ERR_160:0, DET_EXISTENCE_PROB_157:0, DET_EXISTENCE_PROB_158:0, DET_EXISTENCE_PROB_159:0, DET_EXISTENCE_PROB_160:0, DET_HVC_FLAG_157:0, DET_HVC_FLAG_158:0, DET_HVC_FLAG_159:0, DET_HVC_FLAG_160:0, DET_MH_CRC16_157_160:0, DET_MH_CYCLE_COUNTER_157_160:0, DET_MH_SCAN_INDEX_4LSB_157_160:0, DET_OUTSIDE_SECTOR_157:0, DET_OUTSIDE_SECTOR_158:0, DET_OUTSIDE_SECTOR_159:0, DET_OUTSIDE_SECTOR_160:0, DET_POINT_TARGET_PROB_157:0, DET_POINT_TARGET_PROB_158:0, DET_POINT_TARGET_PROB_159:0, DET_POINT_TARGET_PROB_160:0, DET_RANGE_157:0, DET_RANGE_158:0, DET_RANGE_159:0, DET_RANGE_160:0, DET_RANGE_ERR_157:0, DET_RANGE_ERR_158:0, DET_RANGE_ERR_159:0, DET_RANGE_ERR_160:0, DET_RANGE_VELOCITY_157:16384, DET_RANGE_VELOCITY_158:16384, DET_RANGE_VELOCITY_159:16384, DET_RANGE_VELOCITY_160:16384, DET_RANGE_VELOCITY_ERR_157:0, DET_RANGE_VELOCITY_ERR_158:0, DET_RANGE_VELOCITY_ERR_159:0, DET_RANGE_VELOCITY_ERR_160:0, DET_RCS_157:128, DET_RCS_158:128, DET_RCS_159:128, DET_RCS_160:128, DET_SNR_157:0, DET_SNR_158:0, DET_SNR_159:0, DET_SNR_160:0, DET_SUPER_RES_TARGET_157:0, DET_SUPER_RES_TARGET_158:0, DET_SUPER_RES_TARGET_159:0, DET_SUPER_RES_TARGET_160:0, DET_VALID_FLAG_157:0, DET_VALID_FLAG_158:0, DET_VALID_FLAG_159:0, DET_VALID_FLAG_160:0]}, provided-interface=Pi_SG_Detections_157_160
      Pp_SG_Detections_161_164: nonqueued-sender-com-spec{data-element=Vdp_SG_Detections_161_164, init-value=fields=[DET_AZIMUTH_161:0, DET_AZIMUTH_162:0, DET_AZIMUTH_163:0, DET_AZIMUTH_164:0, DET_AZIMUTH_ERR_161:0, DET_AZIMUTH_ERR_162:0, DET_AZIMUTH_ERR_163:0, DET_AZIMUTH_ERR_164:0, DET_BI_STATIC_FLAG_161:0, DET_BI_STATIC_FLAG_162:0, DET_BI_STATIC_FLAG_163:0, DET_BI_STATIC_FLAG_164:0, DET_CONFD_AZIMUTH_161:0, DET_CONFD_AZIMUTH_162:0, DET_CONFD_AZIMUTH_163:0, DET_CONFD_AZIMUTH_164:0, DET_CONFD_ELEVATION_161:0, DET_CONFD_ELEVATION_162:0, DET_CONFD_ELEVATION_163:0, DET_CONFD_ELEVATION_164:0, DET_ELEVATION_161:0, DET_ELEVATION_162:0, DET_ELEVATION_163:0, DET_ELEVATION_164:0, DET_ELEVATION_ERR_161:0, DET_ELEVATION_ERR_162:0, DET_ELEVATION_ERR_163:0, DET_ELEVATION_ERR_164:0, DET_EXISTENCE_PROB_161:0, DET_EXISTENCE_PROB_162:0, DET_EXISTENCE_PROB_163:0, DET_EXISTENCE_PROB_164:0, DET_HVC_FLAG_161:0, DET_HVC_FLAG_162:0, DET_HVC_FLAG_163:0, DET_HVC_FLAG_164:0, DET_MH_CRC16_161_164:0, DET_MH_CYCLE_COUNTER_161_164:0, DET_MH_SCAN_INDEX_4LSB_161_164:0, DET_OUTSIDE_SECTOR_161:0, DET_OUTSIDE_SECTOR_162:0, DET_OUTSIDE_SECTOR_163:0, DET_OUTSIDE_SECTOR_164:0, DET_POINT_TARGET_PROB_161:0, DET_POINT_TARGET_PROB_162:0, DET_POINT_TARGET_PROB_163:0, DET_POINT_TARGET_PROB_164:0, DET_RANGE_161:0, DET_RANGE_162:0, DET_RANGE_163:0, DET_RANGE_164:0, DET_RANGE_ERR_161:0, DET_RANGE_ERR_162:0, DET_RANGE_ERR_163:0, DET_RANGE_ERR_164:0, DET_RANGE_VELOCITY_161:16384, DET_RANGE_VELOCITY_162:16384, DET_RANGE_VELOCITY_163:16384, DET_RANGE_VELOCITY_164:16384, DET_RANGE_VELOCITY_ERR_161:0, DET_RANGE_VELOCITY_ERR_162:0, DET_RANGE_VELOCITY_ERR_163:0, DET_RANGE_VELOCITY_ERR_164:0, DET_RCS_161:128, DET_RCS_162:128, DET_RCS_163:128, DET_RCS_164:128, DET_SNR_161:0, DET_SNR_162:0, DET_SNR_163:0, DET_SNR_164:0, DET_SUPER_RES_TARGET_161:0, DET_SUPER_RES_TARGET_162:0, DET_SUPER_RES_TARGET_163:0, DET_SUPER_RES_TARGET_164:0, DET_VALID_FLAG_161:0, DET_VALID_FLAG_162:0, DET_VALID_FLAG_163:0, DET_VALID_FLAG_164:0]}, provided-interface=Pi_SG_Detections_161_164
      Pp_SG_Detections_165_168: nonqueued-sender-com-spec{data-element=Vdp_SG_Detections_165_168, init-value=fields=[DET_AZIMUTH_165:0, DET_AZIMUTH_166:0, DET_AZIMUTH_167:0, DET_AZIMUTH_168:0, DET_AZIMUTH_ERR_165:0, DET_AZIMUTH_ERR_166:0, DET_AZIMUTH_ERR_167:0, DET_AZIMUTH_ERR_168:0, DET_BI_STATIC_FLAG_165:0, DET_BI_STATIC_FLAG_166:0, DET_BI_STATIC_FLAG_167:0, DET_BI_STATIC_FLAG_168:0, DET_CONFD_AZIMUTH_165:0, DET_CONFD_AZIMUTH_166:0, DET_CONFD_AZIMUTH_167:0, DET_CONFD_AZIMUTH_168:0, DET_CONFD_ELEVATION_165:0, DET_CONFD_ELEVATION_166:0, DET_CONFD_ELEVATION_167:0, DET_CONFD_ELEVATION_168:0, DET_ELEVATION_165:0, DET_ELEVATION_166:0, DET_ELEVATION_167:0, DET_ELEVATION_168:0, DET_ELEVATION_ERR_165:0, DET_ELEVATION_ERR_166:0, DET_ELEVATION_ERR_167:0, DET_ELEVATION_ERR_168:0, DET_EXISTENCE_PROB_165:0, DET_EXISTENCE_PROB_166:0, DET_EXISTENCE_PROB_167:0, DET_EXISTENCE_PROB_168:0, DET_HVC_FLAG_165:0, DET_HVC_FLAG_166:0, DET_HVC_FLAG_167:0, DET_HVC_FLAG_168:0, DET_MH_CRC16_165_168:0, DET_MH_CYCLE_COUNTER_165_168:0, DET_MH_SCAN_INDEX_4LSB_165_168:0, DET_OUTSIDE_SECTOR_165:0, DET_OUTSIDE_SECTOR_166:0, DET_OUTSIDE_SECTOR_167:0, DET_OUTSIDE_SECTOR_168:0, DET_POINT_TARGET_PROB_165:0, DET_POINT_TARGET_PROB_166:0, DET_POINT_TARGET_PROB_167:0, DET_POINT_TARGET_PROB_168:0, DET_RANGE_165:0, DET_RANGE_166:0, DET_RANGE_167:0, DET_RANGE_168:0, DET_RANGE_ERR_165:0, DET_RANGE_ERR_166:0, DET_RANGE_ERR_167:0, DET_RANGE_ERR_168:0, DET_RANGE_VELOCITY_165:16384, DET_RANGE_VELOCITY_166:16384, DET_RANGE_VELOCITY_167:16384, DET_RANGE_VELOCITY_168:16384, DET_RANGE_VELOCITY_ERR_165:0, DET_RANGE_VELOCITY_ERR_166:0, DET_RANGE_VELOCITY_ERR_167:0, DET_RANGE_VELOCITY_ERR_168:0, DET_RCS_165:128, DET_RCS_166:128, DET_RCS_167:128, DET_RCS_168:128, DET_SNR_165:0, DET_SNR_166:0, DET_SNR_167:0, DET_SNR_168:0, DET_SUPER_RES_TARGET_165:0, DET_SUPER_RES_TARGET_166:0, DET_SUPER_RES_TARGET_167:0, DET_SUPER_RES_TARGET_168:0, DET_VALID_FLAG_165:0, DET_VALID_FLAG_166:0, DET_VALID_FLAG_167:0, DET_VALID_FLAG_168:0]}, provided-interface=Pi_SG_Detections_165_168
      Pp_SG_Detections_169_172: nonqueued-sender-com-spec{data-element=Vdp_SG_Detections_169_172, init-value=fields=[DET_AZIMUTH_169:0, DET_AZIMUTH_170:0, DET_AZIMUTH_171:0, DET_AZIMUTH_172:0, DET_AZIMUTH_ERR_169:0, DET_AZIMUTH_ERR_170:0, DET_AZIMUTH_ERR_171:0, DET_AZIMUTH_ERR_172:0, DET_BI_STATIC_FLAG_169:0, DET_BI_STATIC_FLAG_170:0, DET_BI_STATIC_FLAG_171:0, DET_BI_STATIC_FLAG_172:0, DET_CONFD_AZIMUTH_169:0, DET_CONFD_AZIMUTH_170:0, DET_CONFD_AZIMUTH_171:0, DET_CONFD_AZIMUTH_172:0, DET_CONFD_ELEVATION_169:0, DET_CONFD_ELEVATION_170:0, DET_CONFD_ELEVATION_171:0, DET_CONFD_ELEVATION_172:0, DET_ELEVATION_169:0, DET_ELEVATION_170:0, DET_ELEVATION_171:0, DET_ELEVATION_172:0, DET_ELEVATION_ERR_169:0, DET_ELEVATION_ERR_170:0, DET_ELEVATION_ERR_171:0, DET_ELEVATION_ERR_172:0, DET_EXISTENCE_PROB_169:0, DET_EXISTENCE_PROB_170:0, DET_EXISTENCE_PROB_171:0, DET_EXISTENCE_PROB_172:0, DET_HVC_FLAG_169:0, DET_HVC_FLAG_170:0, DET_HVC_FLAG_171:0, DET_HVC_FLAG_172:0, DET_MH_CRC16_169_172:0, DET_MH_CYCLE_COUNTER_169_172:0, DET_MH_SCAN_INDEX_4LSB_169_172:0, DET_OUTSIDE_SECTOR_169:0, DET_OUTSIDE_SECTOR_170:0, DET_OUTSIDE_SECTOR_171:0, DET_OUTSIDE_SECTOR_172:0, DET_POINT_TARGET_PROB_169:0, DET_POINT_TARGET_PROB_170:0, DET_POINT_TARGET_PROB_171:0, DET_POINT_TARGET_PROB_172:0, DET_RANGE_169:0, DET_RANGE_170:0, DET_RANGE_171:0, DET_RANGE_172:0, DET_RANGE_ERR_169:0, DET_RANGE_ERR_170:0, DET_RANGE_ERR_171:0, DET_RANGE_ERR_172:0, DET_RANGE_VELOCITY_169:16384, DET_RANGE_VELOCITY_170:16384, DET_RANGE_VELOCITY_171:16384, DET_RANGE_VELOCITY_172:16384, DET_RANGE_VELOCITY_ERR_169:0, DET_RANGE_VELOCITY_ERR_170:0, DET_RANGE_VELOCITY_ERR_171:0, DET_RANGE_VELOCITY_ERR_172:0, DET_RCS_169:128, DET_RCS_170:128, DET_RCS_171:128, DET_RCS_172:128, DET_SNR_169:0, DET_SNR_170:0, DET_SNR_171:0, DET_SNR_172:0, DET_SUPER_RES_TARGET_169:0, DET_SUPER_RES_TARGET_170:0, DET_SUPER_RES_TARGET_171:0, DET_SUPER_RES_TARGET_172:0, DET_VALID_FLAG_169:0, DET_VALID_FLAG_170:0, DET_VALID_FLAG_171:0, DET_VALID_FLAG_172:0]}, provided-interface=Pi_SG_Detections_169_172
      Pp_SG_Detections_173_176: nonqueued-sender-com-spec{data-element=Vdp_SG_Detections_173_176, init-value=fields=[DET_AZIMUTH_173:0, DET_AZIMUTH_174:0, DET_AZIMUTH_175:0, DET_AZIMUTH_176:0, DET_AZIMUTH_ERR_173:0, DET_AZIMUTH_ERR_174:0, DET_AZIMUTH_ERR_175:0, DET_AZIMUTH_ERR_176:0, DET_BI_STATIC_FLAG_173:0, DET_BI_STATIC_FLAG_174:0, DET_BI_STATIC_FLAG_175:0, DET_BI_STATIC_FLAG_176:0, DET_CONFD_AZIMUTH_173:0, DET_CONFD_AZIMUTH_174:0, DET_CONFD_AZIMUTH_175:0, DET_CONFD_AZIMUTH_176:0, DET_CONFD_ELEVATION_173:0, DET_CONFD_ELEVATION_174:0, DET_CONFD_ELEVATION_175:0, DET_CONFD_ELEVATION_176:0, DET_ELEVATION_173:0, DET_ELEVATION_174:0, DET_ELEVATION_175:0, DET_ELEVATION_176:0, DET_ELEVATION_ERR_173:0, DET_ELEVATION_ERR_174:0, DET_ELEVATION_ERR_175:0, DET_ELEVATION_ERR_176:0, DET_EXISTENCE_PROB_173:0, DET_EXISTENCE_PROB_174:0, DET_EXISTENCE_PROB_175:0, DET_EXISTENCE_PROB_176:0, DET_HVC_FLAG_173:0, DET_HVC_FLAG_174:0, DET_HVC_FLAG_175:0, DET_HVC_FLAG_176:0, DET_MH_CRC16_173_176:0, DET_MH_CYCLE_COUNTER_173_176:0, DET_MH_SCAN_INDEX_4LSB_173_176:0, DET_OUTSIDE_SECTOR_173:0, DET_OUTSIDE_SECTOR_174:0, DET_OUTSIDE_SECTOR_175:0, DET_OUTSIDE_SECTOR_176:0, DET_POINT_TARGET_PROB_173:0, DET_POINT_TARGET_PROB_174:0, DET_POINT_TARGET_PROB_175:0, DET_POINT_TARGET_PROB_176:0, DET_RANGE_173:0, DET_RANGE_174:0, DET_RANGE_175:0, DET_RANGE_176:0, DET_RANGE_ERR_173:0, DET_RANGE_ERR_174:0, DET_RANGE_ERR_175:0, DET_RANGE_ERR_176:0, DET_RANGE_VELOCITY_173:16384, DET_RANGE_VELOCITY_174:16384, DET_RANGE_VELOCITY_175:16384, DET_RANGE_VELOCITY_176:16384, DET_RANGE_VELOCITY_ERR_173:0, DET_RANGE_VELOCITY_ERR_174:0, DET_RANGE_VELOCITY_ERR_175:0, DET_RANGE_VELOCITY_ERR_176:0, DET_RCS_173:128, DET_RCS_174:128, DET_RCS_175:128, DET_RCS_176:128, DET_SNR_173:0, DET_SNR_174:0, DET_SNR_175:0, DET_SNR_176:0, DET_SUPER_RES_TARGET_173:0, DET_SUPER_RES_TARGET_174:0, DET_SUPER_RES_TARGET_175:0, DET_SUPER_RES_TARGET_176:0, DET_VALID_FLAG_173:0, DET_VALID_FLAG_174:0, DET_VALID_FLAG_175:0, DET_VALID_FLAG_176:0]}, provided-interface=Pi_SG_Detections_173_176
      Pp_SG_Detections_177_180: nonqueued-sender-com-spec{data-element=Vdp_SG_Detections_177_180, init-value=fields=[DET_AZIMUTH_177:0, DET_AZIMUTH_178:0, DET_AZIMUTH_179:0, DET_AZIMUTH_180:0, DET_AZIMUTH_ERR_177:0, DET_AZIMUTH_ERR_178:0, DET_AZIMUTH_ERR_179:0, DET_AZIMUTH_ERR_180:0, DET_BI_STATIC_FLAG_177:0, DET_BI_STATIC_FLAG_178:0, DET_BI_STATIC_FLAG_179:0, DET_BI_STATIC_FLAG_180:0, DET_CONFD_AZIMUTH_177:0, DET_CONFD_AZIMUTH_178:0, DET_CONFD_AZIMUTH_179:0, DET_CONFD_AZIMUTH_180:0, DET_CONFD_ELEVATION_177:0, DET_CONFD_ELEVATION_178:0, DET_CONFD_ELEVATION_179:0, DET_CONFD_ELEVATION_180:0, DET_ELEVATION_177:0, DET_ELEVATION_178:0, DET_ELEVATION_179:0, DET_ELEVATION_180:0, DET_ELEVATION_ERR_177:0, DET_ELEVATION_ERR_178:0, DET_ELEVATION_ERR_179:0, DET_ELEVATION_ERR_180:0, DET_EXISTENCE_PROB_177:0, DET_EXISTENCE_PROB_178:0, DET_EXISTENCE_PROB_179:0, DET_EXISTENCE_PROB_180:0, DET_HVC_FLAG_177:0, DET_HVC_FLAG_178:0, DET_HVC_FLAG_179:0, DET_HVC_FLAG_180:0, DET_MH_CRC16_177_180:0, DET_MH_CYCLE_COUNTER_177_180:0, DET_MH_SCAN_INDEX_4LSB_177_180:0, DET_OUTSIDE_SECTOR_177:0, DET_OUTSIDE_SECTOR_178:0, DET_OUTSIDE_SECTOR_179:0, DET_OUTSIDE_SECTOR_180:0, DET_POINT_TARGET_PROB_177:0, DET_POINT_TARGET_PROB_178:0, DET_POINT_TARGET_PROB_179:0, DET_POINT_TARGET_PROB_180:0, DET_RANGE_177:0, DET_RANGE_178:0, DET_RANGE_179:0, DET_RANGE_180:0, DET_RANGE_ERR_177:0, DET_RANGE_ERR_178:0, DET_RANGE_ERR_179:0, DET_RANGE_ERR_180:0, DET_RANGE_VELOCITY_177:16384, DET_RANGE_VELOCITY_178:16384, DET_RANGE_VELOCITY_179:16384, DET_RANGE_VELOCITY_180:16384, DET_RANGE_VELOCITY_ERR_177:0, DET_RANGE_VELOCITY_ERR_178:0, DET_RANGE_VELOCITY_ERR_179:0, DET_RANGE_VELOCITY_ERR_180:0, DET_RCS_177:128, DET_RCS_178:128, DET_RCS_179:128, DET_RCS_180:128, DET_SNR_177:0, DET_SNR_178:0, DET_SNR_179:0, DET_SNR_180:0, DET_SUPER_RES_TARGET_177:0, DET_SUPER_RES_TARGET_178:0, DET_SUPER_RES_TARGET_179:0, DET_SUPER_RES_TARGET_180:0, DET_VALID_FLAG_177:0, DET_VALID_FLAG_178:0, DET_VALID_FLAG_179:0, DET_VALID_FLAG_180:0]}, provided-interface=Pi_SG_Detections_177_180
      Pp_SG_Detections_181_184: nonqueued-sender-com-spec{data-element=Vdp_SG_Detections_181_184, init-value=fields=[DET_AZIMUTH_181:0, DET_AZIMUTH_182:0, DET_AZIMUTH_183:0, DET_AZIMUTH_184:0, DET_AZIMUTH_ERR_181:0, DET_AZIMUTH_ERR_182:0, DET_AZIMUTH_ERR_183:0, DET_AZIMUTH_ERR_184:0, DET_BI_STATIC_FLAG_181:0, DET_BI_STATIC_FLAG_182:0, DET_BI_STATIC_FLAG_183:0, DET_BI_STATIC_FLAG_184:0, DET_CONFD_AZIMUTH_181:0, DET_CONFD_AZIMUTH_182:0, DET_CONFD_AZIMUTH_183:0, DET_CONFD_AZIMUTH_184:0, DET_CONFD_ELEVATION_181:0, DET_CONFD_ELEVATION_182:0, DET_CONFD_ELEVATION_183:0, DET_CONFD_ELEVATION_184:0, DET_ELEVATION_181:0, DET_ELEVATION_182:0, DET_ELEVATION_183:0, DET_ELEVATION_184:0, DET_ELEVATION_ERR_181:0, DET_ELEVATION_ERR_182:0, DET_ELEVATION_ERR_183:0, DET_ELEVATION_ERR_184:0, DET_EXISTENCE_PROB_181:0, DET_EXISTENCE_PROB_182:0, DET_EXISTENCE_PROB_183:0, DET_EXISTENCE_PROB_184:0, DET_HVC_FLAG_181:0, DET_HVC_FLAG_182:0, DET_HVC_FLAG_183:0, DET_HVC_FLAG_184:0, DET_MH_CRC16_181_184:0, DET_MH_CYCLE_COUNTER_181_184:0, DET_MH_SCAN_INDEX_4LSB_181_184:0, DET_OUTSIDE_SECTOR_181:0, DET_OUTSIDE_SECTOR_182:0, DET_OUTSIDE_SECTOR_183:0, DET_OUTSIDE_SECTOR_184:0, DET_POINT_TARGET_PROB_181:0, DET_POINT_TARGET_PROB_182:0, DET_POINT_TARGET_PROB_183:0, DET_POINT_TARGET_PROB_184:0, DET_RANGE_181:0, DET_RANGE_182:0, DET_RANGE_183:0, DET_RANGE_184:0, DET_RANGE_ERR_181:0, DET_RANGE_ERR_182:0, DET_RANGE_ERR_183:0, DET_RANGE_ERR_184:0, DET_RANGE_VELOCITY_181:16384, DET_RANGE_VELOCITY_182:16384, DET_RANGE_VELOCITY_183:16384, DET_RANGE_VELOCITY_184:16384, DET_RANGE_VELOCITY_ERR_181:0, DET_RANGE_VELOCITY_ERR_182:0, DET_RANGE_VELOCITY_ERR_183:0, DET_RANGE_VELOCITY_ERR_184:0, DET_RCS_181:128, DET_RCS_182:128, DET_RCS_183:128, DET_RCS_184:128, DET_SNR_181:0, DET_SNR_182:0, DET_SNR_183:0, DET_SNR_184:0, DET_SUPER_RES_TARGET_181:0, DET_SUPER_RES_TARGET_182:0, DET_SUPER_RES_TARGET_183:0, DET_SUPER_RES_TARGET_184:0, DET_VALID_FLAG_181:0, DET_VALID_FLAG_182:0, DET_VALID_FLAG_183:0, DET_VALID_FLAG_184:0]}, provided-interface=Pi_SG_Detections_181_184
      Pp_SG_Detections_185_188: nonqueued-sender-com-spec{data-element=Vdp_SG_Detections_185_188, init-value=fields=[DET_AZIMUTH_185:0, DET_AZIMUTH_186:0, DET_AZIMUTH_187:0, DET_AZIMUTH_188:0, DET_AZIMUTH_ERR_185:0, DET_AZIMUTH_ERR_186:0, DET_AZIMUTH_ERR_187:0, DET_AZIMUTH_ERR_188:0, DET_BI_STATIC_FLAG_185:0, DET_BI_STATIC_FLAG_186:0, DET_BI_STATIC_FLAG_187:0, DET_BI_STATIC_FLAG_188:0, DET_CONFD_AZIMUTH_185:0, DET_CONFD_AZIMUTH_186:0, DET_CONFD_AZIMUTH_187:0, DET_CONFD_AZIMUTH_188:0, DET_CONFD_ELEVATION_185:0, DET_CONFD_ELEVATION_186:0, DET_CONFD_ELEVATION_187:0, DET_CONFD_ELEVATION_188:0, DET_ELEVATION_185:0, DET_ELEVATION_186:0, DET_ELEVATION_187:0, DET_ELEVATION_188:0, DET_ELEVATION_ERR_185:0, DET_ELEVATION_ERR_186:0, DET_ELEVATION_ERR_187:0, DET_ELEVATION_ERR_188:0, DET_EXISTENCE_PROB_185:0, DET_EXISTENCE_PROB_186:0, DET_EXISTENCE_PROB_187:0, DET_EXISTENCE_PROB_188:0, DET_HVC_FLAG_185:0, DET_HVC_FLAG_186:0, DET_HVC_FLAG_187:0, DET_HVC_FLAG_188:0, DET_MH_CRC16_185_188:0, DET_MH_CYCLE_COUNTER_185_188:0, DET_MH_SCAN_INDEX_4LSB_185_188:0, DET_OUTSIDE_SECTOR_185:0, DET_OUTSIDE_SECTOR_186:0, DET_OUTSIDE_SECTOR_187:0, DET_OUTSIDE_SECTOR_188:0, DET_POINT_TARGET_PROB_185:0, DET_POINT_TARGET_PROB_186:0, DET_POINT_TARGET_PROB_187:0, DET_POINT_TARGET_PROB_188:0, DET_RANGE_185:0, DET_RANGE_186:0, DET_RANGE_187:0, DET_RANGE_188:0, DET_RANGE_ERR_185:0, DET_RANGE_ERR_186:0, DET_RANGE_ERR_187:0, DET_RANGE_ERR_188:0, DET_RANGE_VELOCITY_185:16384, DET_RANGE_VELOCITY_186:16384, DET_RANGE_VELOCITY_187:16384, DET_RANGE_VELOCITY_188:16384, DET_RANGE_VELOCITY_ERR_185:0, DET_RANGE_VELOCITY_ERR_186:0, DET_RANGE_VELOCITY_ERR_187:0, DET_RANGE_VELOCITY_ERR_188:0, DET_RCS_185:128, DET_RCS_186:128, DET_RCS_187:128, DET_RCS_188:128, DET_SNR_185:0, DET_SNR_186:0, DET_SNR_187:0, DET_SNR_188:0, DET_SUPER_RES_TARGET_185:0, DET_SUPER_RES_TARGET_186:0, DET_SUPER_RES_TARGET_187:0, DET_SUPER_RES_TARGET_188:0, DET_VALID_FLAG_185:0, DET_VALID_FLAG_186:0, DET_VALID_FLAG_187:0, DET_VALID_FLAG_188:0]}, provided-interface=Pi_SG_Detections_185_188
      Pp_SG_Detections_189_192: nonqueued-sender-com-spec{data-element=Vdp_SG_Detections_189_192, init-value=fields=[DET_AZIMUTH_189:0, DET_AZIMUTH_190:0, DET_AZIMUTH_191:0, DET_AZIMUTH_192:0, DET_AZIMUTH_ERR_189:0, DET_AZIMUTH_ERR_190:0, DET_AZIMUTH_ERR_191:0, DET_AZIMUTH_ERR_192:0, DET_BI_STATIC_FLAG_189:0, DET_BI_STATIC_FLAG_190:0, DET_BI_STATIC_FLAG_191:0, DET_BI_STATIC_FLAG_192:0, DET_CONFD_AZIMUTH_189:0, DET_CONFD_AZIMUTH_190:0, DET_CONFD_AZIMUTH_191:0, DET_CONFD_AZIMUTH_192:0, DET_CONFD_ELEVATION_189:0, DET_CONFD_ELEVATION_190:0, DET_CONFD_ELEVATION_191:0, DET_CONFD_ELEVATION_192:0, DET_ELEVATION_189:0, DET_ELEVATION_190:0, DET_ELEVATION_191:0, DET_ELEVATION_192:0, DET_ELEVATION_ERR_189:0, DET_ELEVATION_ERR_190:0, DET_ELEVATION_ERR_191:0, DET_ELEVATION_ERR_192:0, DET_EXISTENCE_PROB_189:0, DET_EXISTENCE_PROB_190:0, DET_EXISTENCE_PROB_191:0, DET_EXISTENCE_PROB_192:0, DET_HVC_FLAG_189:0, DET_HVC_FLAG_190:0, DET_HVC_FLAG_191:0, DET_HVC_FLAG_192:0, DET_MH_CRC16_189_192:0, DET_MH_CYCLE_COUNTER_189_192:0, DET_MH_SCAN_INDEX_4LSB_189_192:0, DET_OUTSIDE_SECTOR_189:0, DET_OUTSIDE_SECTOR_190:0, DET_OUTSIDE_SECTOR_191:0, DET_OUTSIDE_SECTOR_192:0, DET_POINT_TARGET_PROB_189:0, DET_POINT_TARGET_PROB_190:0, DET_POINT_TARGET_PROB_191:0, DET_POINT_TARGET_PROB_192:0, DET_RANGE_189:0, DET_RANGE_190:0, DET_RANGE_191:0, DET_RANGE_192:0, DET_RANGE_ERR_189:0, DET_RANGE_ERR_190:0, DET_RANGE_ERR_191:0, DET_RANGE_ERR_192:0, DET_RANGE_VELOCITY_189:16384, DET_RANGE_VELOCITY_190:16384, DET_RANGE_VELOCITY_191:16384, DET_RANGE_VELOCITY_192:16384, DET_RANGE_VELOCITY_ERR_189:0, DET_RANGE_VELOCITY_ERR_190:0, DET_RANGE_VELOCITY_ERR_191:0, DET_RANGE_VELOCITY_ERR_192:0, DET_RCS_189:128, DET_RCS_190:128, DET_RCS_191:128, DET_RCS_192:128, DET_SNR_189:0, DET_SNR_190:0, DET_SNR_191:0, DET_SNR_192:0, DET_SUPER_RES_TARGET_189:0, DET_SUPER_RES_TARGET_190:0, DET_SUPER_RES_TARGET_191:0, DET_SUPER_RES_TARGET_192:0, DET_VALID_FLAG_189:0, DET_VALID_FLAG_190:0, DET_VALID_FLAG_191:0, DET_VALID_FLAG_192:0]}, provided-interface=Pi_SG_Detections_189_192
      Pp_SG_Detections_193_196: nonqueued-sender-com-spec{data-element=Vdp_SG_Detections_193_196, init-value=fields=[DET_AZIMUTH_193:0, DET_AZIMUTH_194:0, DET_AZIMUTH_195:0, DET_AZIMUTH_196:0, DET_AZIMUTH_ERR_193:0, DET_AZIMUTH_ERR_194:0, DET_AZIMUTH_ERR_195:0, DET_AZIMUTH_ERR_196:0, DET_BI_STATIC_FLAG_193:0, DET_BI_STATIC_FLAG_194:0, DET_BI_STATIC_FLAG_195:0, DET_BI_STATIC_FLAG_196:0, DET_CONFD_AZIMUTH_193:0, DET_CONFD_AZIMUTH_194:0, DET_CONFD_AZIMUTH_195:0, DET_CONFD_AZIMUTH_196:0, DET_CONFD_ELEVATION_193:0, DET_CONFD_ELEVATION_194:0, DET_CONFD_ELEVATION_195:0, DET_CONFD_ELEVATION_196:0, DET_ELEVATION_193:0, DET_ELEVATION_194:0, DET_ELEVATION_195:0, DET_ELEVATION_196:0, DET_ELEVATION_ERR_193:0, DET_ELEVATION_ERR_194:0, DET_ELEVATION_ERR_195:0, DET_ELEVATION_ERR_196:0, DET_EXISTENCE_PROB_193:0, DET_EXISTENCE_PROB_194:0, DET_EXISTENCE_PROB_195:0, DET_EXISTENCE_PROB_196:0, DET_HVC_FLAG_193:0, DET_HVC_FLAG_194:0, DET_HVC_FLAG_195:0, DET_HVC_FLAG_196:0, DET_MH_CRC16_193_196:0, DET_MH_CYCLE_COUNTER_193_196:0, DET_MH_SCAN_INDEX_4LSB_193_196:0, DET_OUTSIDE_SECTOR_193:0, DET_OUTSIDE_SECTOR_194:0, DET_OUTSIDE_SECTOR_195:0, DET_OUTSIDE_SECTOR_196:0, DET_POINT_TARGET_PROB_193:0, DET_POINT_TARGET_PROB_194:0, DET_POINT_TARGET_PROB_195:0, DET_POINT_TARGET_PROB_196:0, DET_RANGE_193:0, DET_RANGE_194:0, DET_RANGE_195:0, DET_RANGE_196:0, DET_RANGE_ERR_193:0, DET_RANGE_ERR_194:0, DET_RANGE_ERR_195:0, DET_RANGE_ERR_196:0, DET_RANGE_VELOCITY_193:16384, DET_RANGE_VELOCITY_194:16384, DET_RANGE_VELOCITY_195:16384, DET_RANGE_VELOCITY_196:16384, DET_RANGE_VELOCITY_ERR_193:0, DET_RANGE_VELOCITY_ERR_194:0, DET_RANGE_VELOCITY_ERR_195:0, DET_RANGE_VELOCITY_ERR_196:0, DET_RCS_193:128, DET_RCS_194:128, DET_RCS_195:128, DET_RCS_196:128, DET_SNR_193:0, DET_SNR_194:0, DET_SNR_195:0, DET_SNR_196:0, DET_SUPER_RES_TARGET_193:0, DET_SUPER_RES_TARGET_194:0, DET_SUPER_RES_TARGET_195:0, DET_SUPER_RES_TARGET_196:0, DET_VALID_FLAG_193:0, DET_VALID_FLAG_194:0, DET_VALID_FLAG_195:0, DET_VALID_FLAG_196:0]}, provided-interface=Pi_SG_Detections_193_196
      Pp_SG_Detections_197_200: nonqueued-sender-com-spec{data-element=Vdp_SG_Detections_197_200, init-value=fields=[DET_AZIMUTH_197:0, DET_AZIMUTH_198:0, DET_AZIMUTH_199:0, DET_AZIMUTH_200:0, DET_AZIMUTH_ERR_197:0, DET_AZIMUTH_ERR_198:0, DET_AZIMUTH_ERR_199:0, DET_AZIMUTH_ERR_200:0, DET_BI_STATIC_FLAG_197:0, DET_BI_STATIC_FLAG_198:0, DET_BI_STATIC_FLAG_199:0, DET_BI_STATIC_FLAG_200:0, DET_CONFD_AZIMUTH_197:0, DET_CONFD_AZIMUTH_198:0, DET_CONFD_AZIMUTH_199:0, DET_CONFD_AZIMUTH_200:0, DET_CONFD_ELEVATION_197:0, DET_CONFD_ELEVATION_198:0, DET_CONFD_ELEVATION_199:0, DET_CONFD_ELEVATION_200:0, DET_ELEVATION_197:0, DET_ELEVATION_198:0, DET_ELEVATION_199:0, DET_ELEVATION_200:0, DET_ELEVATION_ERR_197:0, DET_ELEVATION_ERR_198:0, DET_ELEVATION_ERR_199:0, DET_ELEVATION_ERR_200:0, DET_EXISTENCE_PROB_197:0, DET_EXISTENCE_PROB_198:0, DET_EXISTENCE_PROB_199:0, DET_EXISTENCE_PROB_200:0, DET_HVC_FLAG_197:0, DET_HVC_FLAG_198:0, DET_HVC_FLAG_199:0, DET_HVC_FLAG_200:0, DET_MH_CRC16_197_200:0, DET_MH_CYCLE_COUNTER_197_200:0, DET_MH_SCAN_INDEX_4LSB_197_200:0, DET_OUTSIDE_SECTOR_197:0, DET_OUTSIDE_SECTOR_198:0, DET_OUTSIDE_SECTOR_199:0, DET_OUTSIDE_SECTOR_200:0, DET_POINT_TARGET_PROB_197:0, DET_POINT_TARGET_PROB_198:0, DET_POINT_TARGET_PROB_199:0, DET_POINT_TARGET_PROB_200:0, DET_RANGE_197:0, DET_RANGE_198:0, DET_RANGE_199:0, DET_RANGE_200:0, DET_RANGE_ERR_197:0, DET_RANGE_ERR_198:0, DET_RANGE_ERR_199:0, DET_RANGE_ERR_200:0, DET_RANGE_VELOCITY_197:16384, DET_RANGE_VELOCITY_198:16384, DET_RANGE_VELOCITY_199:16384, DET_RANGE_VELOCITY_200:16384, DET_RANGE_VELOCITY_ERR_197:0, DET_RANGE_VELOCITY_ERR_198:0, DET_RANGE_VELOCITY_ERR_199:0, DET_RANGE_VELOCITY_ERR_200:0, DET_RCS_197:128, DET_RCS_198:128, DET_RCS_199:128, DET_RCS_200:128, DET_SNR_197:0, DET_SNR_198:0, DET_SNR_199:0, DET_SNR_200:0, DET_SUPER_RES_TARGET_197:0, DET_SUPER_RES_TARGET_198:0, DET_SUPER_RES_TARGET_199:0, DET_SUPER_RES_TARGET_200:0, DET_VALID_FLAG_197:0, DET_VALID_FLAG_198:0, DET_VALID_FLAG_199:0, DET_VALID_FLAG_200:0]}, provided-interface=Pi_SG_Detections_197_200
      Pp_SG_Detections_201_204: nonqueued-sender-com-spec{data-element=Vdp_SG_Detections_201_204, init-value=fields=[DET_AZIMUTH_201:0, DET_AZIMUTH_202:0, DET_AZIMUTH_203:0, DET_AZIMUTH_204:0, DET_AZIMUTH_ERR_201:0, DET_AZIMUTH_ERR_202:0, DET_AZIMUTH_ERR_203:0, DET_AZIMUTH_ERR_204:0, DET_BI_STATIC_FLAG_201:0, DET_BI_STATIC_FLAG_202:0, DET_BI_STATIC_FLAG_203:0, DET_BI_STATIC_FLAG_204:0, DET_CONFD_AZIMUTH_201:0, DET_CONFD_AZIMUTH_202:0, DET_CONFD_AZIMUTH_203:0, DET_CONFD_AZIMUTH_204:0, DET_CONFD_ELEVATION_201:0, DET_CONFD_ELEVATION_202:0, DET_CONFD_ELEVATION_203:0, DET_CONFD_ELEVATION_204:0, DET_ELEVATION_201:0, DET_ELEVATION_202:0, DET_ELEVATION_203:0, DET_ELEVATION_204:0, DET_ELEVATION_ERR_201:0, DET_ELEVATION_ERR_202:0, DET_ELEVATION_ERR_203:0, DET_ELEVATION_ERR_204:0, DET_EXISTENCE_PROB_201:0, DET_EXISTENCE_PROB_202:0, DET_EXISTENCE_PROB_203:0, DET_EXISTENCE_PROB_204:0, DET_HVC_FLAG_201:0, DET_HVC_FLAG_202:0, DET_HVC_FLAG_203:0, DET_HVC_FLAG_204:0, DET_MH_CRC16_201_204:0, DET_MH_CYCLE_COUNTER_201_204:0, DET_MH_SCAN_INDEX_4LSB_201_204:0, DET_OUTSIDE_SECTOR_201:0, DET_OUTSIDE_SECTOR_202:0, DET_OUTSIDE_SECTOR_203:0, DET_OUTSIDE_SECTOR_204:0, DET_POINT_TARGET_PROB_201:0, DET_POINT_TARGET_PROB_202:0, DET_POINT_TARGET_PROB_203:0, DET_POINT_TARGET_PROB_204:0, DET_RANGE_201:0, DET_RANGE_202:0, DET_RANGE_203:0, DET_RANGE_204:0, DET_RANGE_ERR_201:0, DET_RANGE_ERR_202:0, DET_RANGE_ERR_203:0, DET_RANGE_ERR_204:0, DET_RANGE_VELOCITY_201:16384, DET_RANGE_VELOCITY_202:16384, DET_RANGE_VELOCITY_203:16384, DET_RANGE_VELOCITY_204:16384, DET_RANGE_VELOCITY_ERR_201:0, DET_RANGE_VELOCITY_ERR_202:0, DET_RANGE_VELOCITY_ERR_203:0, DET_RANGE_VELOCITY_ERR_204:0, DET_RCS_201:128, DET_RCS_202:128, DET_RCS_203:128, DET_RCS_204:128, DET_SNR_201:0, DET_SNR_202:0, DET_SNR_203:0, DET_SNR_204:0, DET_SUPER_RES_TARGET_201:0, DET_SUPER_RES_TARGET_202:0, DET_SUPER_RES_TARGET_203:0, DET_SUPER_RES_TARGET_204:0, DET_VALID_FLAG_201:0, DET_VALID_FLAG_202:0, DET_VALID_FLAG_203:0, DET_VALID_FLAG_204:0]}, provided-interface=Pi_SG_Detections_201_204
      Pp_SG_Detections_205_208: nonqueued-sender-com-spec{data-element=Vdp_SG_Detections_205_208, init-value=fields=[DET_AZIMUTH_205:0, DET_AZIMUTH_206:0, DET_AZIMUTH_207:0, DET_AZIMUTH_208:0, DET_AZIMUTH_ERR_205:0, DET_AZIMUTH_ERR_206:0, DET_AZIMUTH_ERR_207:0, DET_AZIMUTH_ERR_208:0, DET_BI_STATIC_FLAG_205:0, DET_BI_STATIC_FLAG_206:0, DET_BI_STATIC_FLAG_207:0, DET_BI_STATIC_FLAG_208:0, DET_CONFD_AZIMUTH_205:0, DET_CONFD_AZIMUTH_206:0, DET_CONFD_AZIMUTH_207:0, DET_CONFD_AZIMUTH_208:0, DET_CONFD_ELEVATION_205:0, DET_CONFD_ELEVATION_206:0, DET_CONFD_ELEVATION_207:0, DET_CONFD_ELEVATION_208:0, DET_ELEVATION_205:0, DET_ELEVATION_206:0, DET_ELEVATION_207:0, DET_ELEVATION_208:0, DET_ELEVATION_ERR_205:0, DET_ELEVATION_ERR_206:0, DET_ELEVATION_ERR_207:0, DET_ELEVATION_ERR_208:0, DET_EXISTENCE_PROB_205:0, DET_EXISTENCE_PROB_206:0, DET_EXISTENCE_PROB_207:0, DET_EXISTENCE_PROB_208:0, DET_HVC_FLAG_205:0, DET_HVC_FLAG_206:0, DET_HVC_FLAG_207:0, DET_HVC_FLAG_208:0, DET_MH_CRC16_205_208:0, DET_MH_CYCLE_COUNTER_205_208:0, DET_MH_SCAN_INDEX_4LSB_205_208:0, DET_OUTSIDE_SECTOR_205:0, DET_OUTSIDE_SECTOR_206:0, DET_OUTSIDE_SECTOR_207:0, DET_OUTSIDE_SECTOR_208:0, DET_POINT_TARGET_PROB_205:0, DET_POINT_TARGET_PROB_206:0, DET_POINT_TARGET_PROB_207:0, DET_POINT_TARGET_PROB_208:0, DET_RANGE_205:0, DET_RANGE_206:0, DET_RANGE_207:0, DET_RANGE_208:0, DET_RANGE_ERR_205:0, DET_RANGE_ERR_206:0, DET_RANGE_ERR_207:0, DET_RANGE_ERR_208:0, DET_RANGE_VELOCITY_205:16384, DET_RANGE_VELOCITY_206:16384, DET_RANGE_VELOCITY_207:16384, DET_RANGE_VELOCITY_208:16384, DET_RANGE_VELOCITY_ERR_205:0, DET_RANGE_VELOCITY_ERR_206:0, DET_RANGE_VELOCITY_ERR_207:0, DET_RANGE_VELOCITY_ERR_208:0, DET_RCS_205:128, DET_RCS_206:128, DET_RCS_207:128, DET_RCS_208:128, DET_SNR_205:0, DET_SNR_206:0, DET_SNR_207:0, DET_SNR_208:0, DET_SUPER_RES_TARGET_205:0, DET_SUPER_RES_TARGET_206:0, DET_SUPER_RES_TARGET_207:0, DET_SUPER_RES_TARGET_208:0, DET_VALID_FLAG_205:0, DET_VALID_FLAG_206:0, DET_VALID_FLAG_207:0, DET_VALID_FLAG_208:0]}, provided-interface=Pi_SG_Detections_205_208
      Pp_SG_Detections_209_212: nonqueued-sender-com-spec{data-element=Vdp_SG_Detections_209_212, init-value=fields=[DET_AZIMUTH_209:0, DET_AZIMUTH_210:0, DET_AZIMUTH_211:0, DET_AZIMUTH_212:0, DET_AZIMUTH_ERR_209:0, DET_AZIMUTH_ERR_210:0, DET_AZIMUTH_ERR_211:0, DET_AZIMUTH_ERR_212:0, DET_BI_STATIC_FLAG_209:0, DET_BI_STATIC_FLAG_210:0, DET_BI_STATIC_FLAG_211:0, DET_BI_STATIC_FLAG_212:0, DET_CONFD_AZIMUTH_209:0, DET_CONFD_AZIMUTH_210:0, DET_CONFD_AZIMUTH_211:0, DET_CONFD_AZIMUTH_212:0, DET_CONFD_ELEVATION_209:0, DET_CONFD_ELEVATION_210:0, DET_CONFD_ELEVATION_211:0, DET_CONFD_ELEVATION_212:0, DET_ELEVATION_209:0, DET_ELEVATION_210:0, DET_ELEVATION_211:0, DET_ELEVATION_212:0, DET_ELEVATION_ERR_209:0, DET_ELEVATION_ERR_210:0, DET_ELEVATION_ERR_211:0, DET_ELEVATION_ERR_212:0, DET_EXISTENCE_PROB_209:0, DET_EXISTENCE_PROB_210:0, DET_EXISTENCE_PROB_211:0, DET_EXISTENCE_PROB_212:0, DET_HVC_FLAG_209:0, DET_HVC_FLAG_210:0, DET_HVC_FLAG_211:0, DET_HVC_FLAG_212:0, DET_MH_CRC16_209_212:0, DET_MH_CYCLE_COUNTER_209_212:0, DET_MH_SCAN_INDEX_4LSB_209_212:0, DET_OUTSIDE_SECTOR_209:0, DET_OUTSIDE_SECTOR_210:0, DET_OUTSIDE_SECTOR_211:0, DET_OUTSIDE_SECTOR_212:0, DET_POINT_TARGET_PROB_209:0, DET_POINT_TARGET_PROB_210:0, DET_POINT_TARGET_PROB_211:0, DET_POINT_TARGET_PROB_212:0, DET_RANGE_209:0, DET_RANGE_210:0, DET_RANGE_211:0, DET_RANGE_212:0, DET_RANGE_ERR_209:0, DET_RANGE_ERR_210:0, DET_RANGE_ERR_211:0, DET_RANGE_ERR_212:0, DET_RANGE_VELOCITY_209:16384, DET_RANGE_VELOCITY_210:16384, DET_RANGE_VELOCITY_211:16384, DET_RANGE_VELOCITY_212:16384, DET_RANGE_VELOCITY_ERR_209:0, DET_RANGE_VELOCITY_ERR_210:0, DET_RANGE_VELOCITY_ERR_211:0, DET_RANGE_VELOCITY_ERR_212:0, DET_RCS_209:128, DET_RCS_210:128, DET_RCS_211:128, DET_RCS_212:128, DET_SNR_209:0, DET_SNR_210:0, DET_SNR_211:0, DET_SNR_212:0, DET_SUPER_RES_TARGET_209:0, DET_SUPER_RES_TARGET_210:0, DET_SUPER_RES_TARGET_211:0, DET_SUPER_RES_TARGET_212:0, DET_VALID_FLAG_209:0, DET_VALID_FLAG_210:0, DET_VALID_FLAG_211:0, DET_VALID_FLAG_212:0]}, provided-interface=Pi_SG_Detections_209_212
      Pp_SG_Detections_213_216: nonqueued-sender-com-spec{data-element=Vdp_SG_Detections_213_216, init-value=fields=[DET_AZIMUTH_213:0, DET_AZIMUTH_214:0, DET_AZIMUTH_215:0, DET_AZIMUTH_216:0, DET_AZIMUTH_ERR_213:0, DET_AZIMUTH_ERR_214:0, DET_AZIMUTH_ERR_215:0, DET_AZIMUTH_ERR_216:0, DET_BI_STATIC_FLAG_213:0, DET_BI_STATIC_FLAG_214:0, DET_BI_STATIC_FLAG_215:0, DET_BI_STATIC_FLAG_216:0, DET_CONFD_AZIMUTH_213:0, DET_CONFD_AZIMUTH_214:0, DET_CONFD_AZIMUTH_215:0, DET_CONFD_AZIMUTH_216:0, DET_CONFD_ELEVATION_213:0, DET_CONFD_ELEVATION_214:0, DET_CONFD_ELEVATION_215:0, DET_CONFD_ELEVATION_216:0, DET_ELEVATION_213:0, DET_ELEVATION_214:0, DET_ELEVATION_215:0, DET_ELEVATION_216:0, DET_ELEVATION_ERR_213:0, DET_ELEVATION_ERR_214:0, DET_ELEVATION_ERR_215:0, DET_ELEVATION_ERR_216:0, DET_EXISTENCE_PROB_213:0, DET_EXISTENCE_PROB_214:0, DET_EXISTENCE_PROB_215:0, DET_EXISTENCE_PROB_216:0, DET_HVC_FLAG_213:0, DET_HVC_FLAG_214:0, DET_HVC_FLAG_215:0, DET_HVC_FLAG_216:0, DET_MH_CRC16_213_216:0, DET_MH_CYCLE_COUNTER_213_216:0, DET_MH_SCAN_INDEX_4LSB_213_216:0, DET_OUTSIDE_SECTOR_213:0, DET_OUTSIDE_SECTOR_214:0, DET_OUTSIDE_SECTOR_215:0, DET_OUTSIDE_SECTOR_216:0, DET_POINT_TARGET_PROB_213:0, DET_POINT_TARGET_PROB_214:0, DET_POINT_TARGET_PROB_215:0, DET_POINT_TARGET_PROB_216:0, DET_RANGE_213:0, DET_RANGE_214:0, DET_RANGE_215:0, DET_RANGE_216:0, DET_RANGE_ERR_213:0, DET_RANGE_ERR_214:0, DET_RANGE_ERR_215:0, DET_RANGE_ERR_216:0, DET_RANGE_VELOCITY_213:16384, DET_RANGE_VELOCITY_214:16384, DET_RANGE_VELOCITY_215:16384, DET_RANGE_VELOCITY_216:16384, DET_RANGE_VELOCITY_ERR_213:0, DET_RANGE_VELOCITY_ERR_214:0, DET_RANGE_VELOCITY_ERR_215:0, DET_RANGE_VELOCITY_ERR_216:0, DET_RCS_213:128, DET_RCS_214:128, DET_RCS_215:128, DET_RCS_216:128, DET_SNR_213:0, DET_SNR_214:0, DET_SNR_215:0, DET_SNR_216:0, DET_SUPER_RES_TARGET_213:0, DET_SUPER_RES_TARGET_214:0, DET_SUPER_RES_TARGET_215:0, DET_SUPER_RES_TARGET_216:0, DET_VALID_FLAG_213:0, DET_VALID_FLAG_214:0, DET_VALID_FLAG_215:0, DET_VALID_FLAG_216:0]}, provided-interface=Pi_SG_Detections_213_216
      Pp_SG_Detections_217_220: nonqueued-sender-com-spec{data-element=Vdp_SG_Detections_217_220, init-value=fields=[DET_AZIMUTH_217:0, DET_AZIMUTH_218:0, DET_AZIMUTH_219:0, DET_AZIMUTH_220:0, DET_AZIMUTH_ERR_217:0, DET_AZIMUTH_ERR_218:0, DET_AZIMUTH_ERR_219:0, DET_AZIMUTH_ERR_220:0, DET_BI_STATIC_FLAG_217:0, DET_BI_STATIC_FLAG_218:0, DET_BI_STATIC_FLAG_219:0, DET_BI_STATIC_FLAG_220:0, DET_CONFD_AZIMUTH_217:0, DET_CONFD_AZIMUTH_218:0, DET_CONFD_AZIMUTH_219:0, DET_CONFD_AZIMUTH_220:0, DET_CONFD_ELEVATION_217:0, DET_CONFD_ELEVATION_218:0, DET_CONFD_ELEVATION_219:0, DET_CONFD_ELEVATION_220:0, DET_ELEVATION_217:0, DET_ELEVATION_218:0, DET_ELEVATION_219:0, DET_ELEVATION_220:0, DET_ELEVATION_ERR_217:0, DET_ELEVATION_ERR_218:0, DET_ELEVATION_ERR_219:0, DET_ELEVATION_ERR_220:0, DET_EXISTENCE_PROB_217:0, DET_EXISTENCE_PROB_218:0, DET_EXISTENCE_PROB_219:0, DET_EXISTENCE_PROB_220:0, DET_HVC_FLAG_217:0, DET_HVC_FLAG_218:0, DET_HVC_FLAG_219:0, DET_HVC_FLAG_220:0, DET_MH_CRC16_217_220:0, DET_MH_CYCLE_COUNTER_217_220:0, DET_MH_SCAN_INDEX_4LSB_217_220:0, DET_OUTSIDE_SECTOR_217:0, DET_OUTSIDE_SECTOR_218:0, DET_OUTSIDE_SECTOR_219:0, DET_OUTSIDE_SECTOR_220:0, DET_POINT_TARGET_PROB_217:0, DET_POINT_TARGET_PROB_218:0, DET_POINT_TARGET_PROB_219:0, DET_POINT_TARGET_PROB_220:0, DET_RANGE_217:0, DET_RANGE_218:0, DET_RANGE_219:0, DET_RANGE_220:0, DET_RANGE_ERR_217:0, DET_RANGE_ERR_218:0, DET_RANGE_ERR_219:0, DET_RANGE_ERR_220:0, DET_RANGE_VELOCITY_217:16384, DET_RANGE_VELOCITY_218:16384, DET_RANGE_VELOCITY_219:16384, DET_RANGE_VELOCITY_220:16384, DET_RANGE_VELOCITY_ERR_217:0, DET_RANGE_VELOCITY_ERR_218:0, DET_RANGE_VELOCITY_ERR_219:0, DET_RANGE_VELOCITY_ERR_220:0, DET_RCS_217:128, DET_RCS_218:128, DET_RCS_219:128, DET_RCS_220:128, DET_SNR_217:0, DET_SNR_218:0, DET_SNR_219:0, DET_SNR_220:0, DET_SUPER_RES_TARGET_217:0, DET_SUPER_RES_TARGET_218:0, DET_SUPER_RES_TARGET_219:0, DET_SUPER_RES_TARGET_220:0, DET_VALID_FLAG_217:0, DET_VALID_FLAG_218:0, DET_VALID_FLAG_219:0, DET_VALID_FLAG_220:0]}, provided-interface=Pi_SG_Detections_217_220
      Pp_SG_Detections_221_224: nonqueued-sender-com-spec{data-element=Vdp_SG_Detections_221_224, init-value=fields=[DET_AZIMUTH_221:0, DET_AZIMUTH_222:0, DET_AZIMUTH_223:0, DET_AZIMUTH_224:0, DET_AZIMUTH_ERR_221:0, DET_AZIMUTH_ERR_222:0, DET_AZIMUTH_ERR_223:0, DET_AZIMUTH_ERR_224:0, DET_BI_STATIC_FLAG_221:0, DET_BI_STATIC_FLAG_222:0, DET_BI_STATIC_FLAG_223:0, DET_BI_STATIC_FLAG_224:0, DET_CONFD_AZIMUTH_221:0, DET_CONFD_AZIMUTH_222:0, DET_CONFD_AZIMUTH_223:0, DET_CONFD_AZIMUTH_224:0, DET_CONFD_ELEVATION_221:0, DET_CONFD_ELEVATION_222:0, DET_CONFD_ELEVATION_223:0, DET_CONFD_ELEVATION_224:0, DET_ELEVATION_221:0, DET_ELEVATION_222:0, DET_ELEVATION_223:0, DET_ELEVATION_224:0, DET_ELEVATION_ERR_221:0, DET_ELEVATION_ERR_222:0, DET_ELEVATION_ERR_223:0, DET_ELEVATION_ERR_224:0, DET_EXISTENCE_PROB_221:0, DET_EXISTENCE_PROB_222:0, DET_EXISTENCE_PROB_223:0, DET_EXISTENCE_PROB_224:0, DET_HVC_FLAG_221:0, DET_HVC_FLAG_222:0, DET_HVC_FLAG_223:0, DET_HVC_FLAG_224:0, DET_MH_CRC16_221_224:0, DET_MH_CYCLE_COUNTER_221_224:0, DET_MH_SCAN_INDEX_4LSB_221_224:0, DET_OUTSIDE_SECTOR_221:0, DET_OUTSIDE_SECTOR_222:0, DET_OUTSIDE_SECTOR_223:0, DET_OUTSIDE_SECTOR_224:0, DET_POINT_TARGET_PROB_221:0, DET_POINT_TARGET_PROB_222:0, DET_POINT_TARGET_PROB_223:0, DET_POINT_TARGET_PROB_224:0, DET_RANGE_221:0, DET_RANGE_222:0, DET_RANGE_223:0, DET_RANGE_224:0, DET_RANGE_ERR_221:0, DET_RANGE_ERR_222:0, DET_RANGE_ERR_223:0, DET_RANGE_ERR_224:0, DET_RANGE_VELOCITY_221:16384, DET_RANGE_VELOCITY_222:16384, DET_RANGE_VELOCITY_223:16384, DET_RANGE_VELOCITY_224:16384, DET_RANGE_VELOCITY_ERR_221:0, DET_RANGE_VELOCITY_ERR_222:0, DET_RANGE_VELOCITY_ERR_223:0, DET_RANGE_VELOCITY_ERR_224:0, DET_RCS_221:128, DET_RCS_222:128, DET_RCS_223:128, DET_RCS_224:128, DET_SNR_221:0, DET_SNR_222:0, DET_SNR_223:0, DET_SNR_224:0, DET_SUPER_RES_TARGET_221:0, DET_SUPER_RES_TARGET_222:0, DET_SUPER_RES_TARGET_223:0, DET_SUPER_RES_TARGET_224:0, DET_VALID_FLAG_221:0, DET_VALID_FLAG_222:0, DET_VALID_FLAG_223:0, DET_VALID_FLAG_224:0]}, provided-interface=Pi_SG_Detections_221_224
      Pp_SG_Detections_225_228: nonqueued-sender-com-spec{data-element=Vdp_SG_Detections_225_228, init-value=fields=[DET_AZIMUTH_225:0, DET_AZIMUTH_226:0, DET_AZIMUTH_227:0, DET_AZIMUTH_228:0, DET_AZIMUTH_ERR_225:0, DET_AZIMUTH_ERR_226:0, DET_AZIMUTH_ERR_227:0, DET_AZIMUTH_ERR_228:0, DET_BI_STATIC_FLAG_225:0, DET_BI_STATIC_FLAG_226:0, DET_BI_STATIC_FLAG_227:0, DET_BI_STATIC_FLAG_228:0, DET_CONFD_AZIMUTH_225:0, DET_CONFD_AZIMUTH_226:0, DET_CONFD_AZIMUTH_227:0, DET_CONFD_AZIMUTH_228:0, DET_CONFD_ELEVATION_225:0, DET_CONFD_ELEVATION_226:0, DET_CONFD_ELEVATION_227:0, DET_CONFD_ELEVATION_228:0, DET_ELEVATION_225:0, DET_ELEVATION_226:0, DET_ELEVATION_227:0, DET_ELEVATION_228:0, DET_ELEVATION_ERR_225:0, DET_ELEVATION_ERR_226:0, DET_ELEVATION_ERR_227:0, DET_ELEVATION_ERR_228:0, DET_EXISTENCE_PROB_225:0, DET_EXISTENCE_PROB_226:0, DET_EXISTENCE_PROB_227:0, DET_EXISTENCE_PROB_228:0, DET_HVC_FLAG_225:0, DET_HVC_FLAG_226:0, DET_HVC_FLAG_227:0, DET_HVC_FLAG_228:0, DET_MH_CRC16_225_228:0, DET_MH_CYCLE_COUNTER_225_228:0, DET_MH_SCAN_INDEX_4LSB_225_228:0, DET_OUTSIDE_SECTOR_225:0, DET_OUTSIDE_SECTOR_226:0, DET_OUTSIDE_SECTOR_227:0, DET_OUTSIDE_SECTOR_228:0, DET_POINT_TARGET_PROB_225:0, DET_POINT_TARGET_PROB_226:0, DET_POINT_TARGET_PROB_227:0, DET_POINT_TARGET_PROB_228:0, DET_RANGE_225:0, DET_RANGE_226:0, DET_RANGE_227:0, DET_RANGE_228:0, DET_RANGE_ERR_225:0, DET_RANGE_ERR_226:0, DET_RANGE_ERR_227:0, DET_RANGE_ERR_228:0, DET_RANGE_VELOCITY_225:16384, DET_RANGE_VELOCITY_226:16384, DET_RANGE_VELOCITY_227:16384, DET_RANGE_VELOCITY_228:16384, DET_RANGE_VELOCITY_ERR_225:0, DET_RANGE_VELOCITY_ERR_226:0, DET_RANGE_VELOCITY_ERR_227:0, DET_RANGE_VELOCITY_ERR_228:0, DET_RCS_225:128, DET_RCS_226:128, DET_RCS_227:128, DET_RCS_228:128, DET_SNR_225:0, DET_SNR_226:0, DET_SNR_227:0, DET_SNR_228:0, DET_SUPER_RES_TARGET_225:0, DET_SUPER_RES_TARGET_226:0, DET_SUPER_RES_TARGET_227:0, DET_SUPER_RES_TARGET_228:0, DET_VALID_FLAG_225:0, DET_VALID_FLAG_226:0, DET_VALID_FLAG_227:0, DET_VALID_FLAG_228:0]}, provided-interface=Pi_SG_Detections_225_228
      Pp_SG_Detections_229_232: nonqueued-sender-com-spec{data-element=Vdp_SG_Detections_229_232, init-value=fields=[DET_AZIMUTH_229:0, DET_AZIMUTH_230:0, DET_AZIMUTH_231:0, DET_AZIMUTH_232:0, DET_AZIMUTH_ERR_229:0, DET_AZIMUTH_ERR_230:0, DET_AZIMUTH_ERR_231:0, DET_AZIMUTH_ERR_232:0, DET_BI_STATIC_FLAG_229:0, DET_BI_STATIC_FLAG_230:0, DET_BI_STATIC_FLAG_231:0, DET_BI_STATIC_FLAG_232:0, DET_CONFD_AZIMUTH_229:0, DET_CONFD_AZIMUTH_230:0, DET_CONFD_AZIMUTH_231:0, DET_CONFD_AZIMUTH_232:0, DET_CONFD_ELEVATION_229:0, DET_CONFD_ELEVATION_230:0, DET_CONFD_ELEVATION_231:0, DET_CONFD_ELEVATION_232:0, DET_ELEVATION_229:0, DET_ELEVATION_230:0, DET_ELEVATION_231:0, DET_ELEVATION_232:0, DET_ELEVATION_ERR_229:0, DET_ELEVATION_ERR_230:0, DET_ELEVATION_ERR_231:0, DET_ELEVATION_ERR_232:0, DET_EXISTENCE_PROB_229:0, DET_EXISTENCE_PROB_230:0, DET_EXISTENCE_PROB_231:0, DET_EXISTENCE_PROB_232:0, DET_HVC_FLAG_229:0, DET_HVC_FLAG_230:0, DET_HVC_FLAG_231:0, DET_HVC_FLAG_232:0, DET_MH_CRC16_229_232:0, DET_MH_CYCLE_COUNTER_229_232:0, DET_MH_SCAN_INDEX_4LSB_229_232:0, DET_OUTSIDE_SECTOR_229:0, DET_OUTSIDE_SECTOR_230:0, DET_OUTSIDE_SECTOR_231:0, DET_OUTSIDE_SECTOR_232:0, DET_POINT_TARGET_PROB_229:0, DET_POINT_TARGET_PROB_230:0, DET_POINT_TARGET_PROB_231:0, DET_POINT_TARGET_PROB_232:0, DET_RANGE_229:0, DET_RANGE_230:0, DET_RANGE_231:0, DET_RANGE_232:0, DET_RANGE_ERR_229:0, DET_RANGE_ERR_230:0, DET_RANGE_ERR_231:0, DET_RANGE_ERR_232:0, DET_RANGE_VELOCITY_229:16384, DET_RANGE_VELOCITY_230:16384, DET_RANGE_VELOCITY_231:16384, DET_RANGE_VELOCITY_232:16384, DET_RANGE_VELOCITY_ERR_229:0, DET_RANGE_VELOCITY_ERR_230:0, DET_RANGE_VELOCITY_ERR_231:0, DET_RANGE_VELOCITY_ERR_232:0, DET_RCS_229:128, DET_RCS_230:128, DET_RCS_231:128, DET_RCS_232:128, DET_SNR_229:0, DET_SNR_230:0, DET_SNR_231:0, DET_SNR_232:0, DET_SUPER_RES_TARGET_229:0, DET_SUPER_RES_TARGET_230:0, DET_SUPER_RES_TARGET_231:0, DET_SUPER_RES_TARGET_232:0, DET_VALID_FLAG_229:0, DET_VALID_FLAG_230:0, DET_VALID_FLAG_231:0, DET_VALID_FLAG_232:0]}, provided-interface=Pi_SG_Detections_229_232
      Pp_SG_Detections_233_236: nonqueued-sender-com-spec{data-element=Vdp_SG_Detections_233_236, init-value=fields=[DET_AZIMUTH_233:0, DET_AZIMUTH_234:0, DET_AZIMUTH_235:0, DET_AZIMUTH_236:0, DET_AZIMUTH_ERR_233:0, DET_AZIMUTH_ERR_234:0, DET_AZIMUTH_ERR_235:0, DET_AZIMUTH_ERR_236:0, DET_BI_STATIC_FLAG_233:0, DET_BI_STATIC_FLAG_234:0, DET_BI_STATIC_FLAG_235:0, DET_BI_STATIC_FLAG_236:0, DET_CONFD_AZIMUTH_233:0, DET_CONFD_AZIMUTH_234:0, DET_CONFD_AZIMUTH_235:0, DET_CONFD_AZIMUTH_236:0, DET_CONFD_ELEVATION_233:0, DET_CONFD_ELEVATION_234:0, DET_CONFD_ELEVATION_235:0, DET_CONFD_ELEVATION_236:0, DET_ELEVATION_233:0, DET_ELEVATION_234:0, DET_ELEVATION_235:0, DET_ELEVATION_236:0, DET_ELEVATION_ERR_233:0, DET_ELEVATION_ERR_234:0, DET_ELEVATION_ERR_235:0, DET_ELEVATION_ERR_236:0, DET_EXISTENCE_PROB_233:0, DET_EXISTENCE_PROB_234:0, DET_EXISTENCE_PROB_235:0, DET_EXISTENCE_PROB_236:0, DET_HVC_FLAG_233:0, DET_HVC_FLAG_234:0, DET_HVC_FLAG_235:0, DET_HVC_FLAG_236:0, DET_MH_CRC16_233_236:0, DET_MH_CYCLE_COUNTER_233_236:0, DET_MH_SCAN_INDEX_4LSB_233_236:0, DET_OUTSIDE_SECTOR_233:0, DET_OUTSIDE_SECTOR_234:0, DET_OUTSIDE_SECTOR_235:0, DET_OUTSIDE_SECTOR_236:0, DET_POINT_TARGET_PROB_233:0, DET_POINT_TARGET_PROB_234:0, DET_POINT_TARGET_PROB_235:0, DET_POINT_TARGET_PROB_236:0, DET_RANGE_233:0, DET_RANGE_234:0, DET_RANGE_235:0, DET_RANGE_236:0, DET_RANGE_ERR_233:0, DET_RANGE_ERR_234:0, DET_RANGE_ERR_235:0, DET_RANGE_ERR_236:0, DET_RANGE_VELOCITY_233:16384, DET_RANGE_VELOCITY_234:16384, DET_RANGE_VELOCITY_235:16384, DET_RANGE_VELOCITY_236:16384, DET_RANGE_VELOCITY_ERR_233:0, DET_RANGE_VELOCITY_ERR_234:0, DET_RANGE_VELOCITY_ERR_235:0, DET_RANGE_VELOCITY_ERR_236:0, DET_RCS_233:128, DET_RCS_234:128, DET_RCS_235:128, DET_RCS_236:128, DET_SNR_233:0, DET_SNR_234:0, DET_SNR_235:0, DET_SNR_236:0, DET_SUPER_RES_TARGET_233:0, DET_SUPER_RES_TARGET_234:0, DET_SUPER_RES_TARGET_235:0, DET_SUPER_RES_TARGET_236:0, DET_VALID_FLAG_233:0, DET_VALID_FLAG_234:0, DET_VALID_FLAG_235:0, DET_VALID_FLAG_236:0]}, provided-interface=Pi_SG_Detections_233_236
      Pp_SG_Detections_237_240: nonqueued-sender-com-spec{data-element=Vdp_SG_Detections_237_240, init-value=fields=[DET_AZIMUTH_237:0, DET_AZIMUTH_238:0, DET_AZIMUTH_239:0, DET_AZIMUTH_240:0, DET_AZIMUTH_ERR_237:0, DET_AZIMUTH_ERR_238:0, DET_AZIMUTH_ERR_239:0, DET_AZIMUTH_ERR_240:0, DET_BI_STATIC_FLAG_237:0, DET_BI_STATIC_FLAG_238:0, DET_BI_STATIC_FLAG_239:0, DET_BI_STATIC_FLAG_240:0, DET_CONFD_AZIMUTH_237:0, DET_CONFD_AZIMUTH_238:0, DET_CONFD_AZIMUTH_239:0, DET_CONFD_AZIMUTH_240:0, DET_CONFD_ELEVATION_237:0, DET_CONFD_ELEVATION_238:0, DET_CONFD_ELEVATION_239:0, DET_CONFD_ELEVATION_240:0, DET_ELEVATION_237:0, DET_ELEVATION_238:0, DET_ELEVATION_239:0, DET_ELEVATION_240:0, DET_ELEVATION_ERR_237:0, DET_ELEVATION_ERR_238:0, DET_ELEVATION_ERR_239:0, DET_ELEVATION_ERR_240:0, DET_EXISTENCE_PROB_237:0, DET_EXISTENCE_PROB_238:0, DET_EXISTENCE_PROB_239:0, DET_EXISTENCE_PROB_240:0, DET_HVC_FLAG_237:0, DET_HVC_FLAG_238:0, DET_HVC_FLAG_239:0, DET_HVC_FLAG_240:0, DET_MH_CRC16_237_240:0, DET_MH_CYCLE_COUNTER_237_240:0, DET_MH_SCAN_INDEX_4LSB_237_240:0, DET_OUTSIDE_SECTOR_237:0, DET_OUTSIDE_SECTOR_238:0, DET_OUTSIDE_SECTOR_239:0, DET_OUTSIDE_SECTOR_240:0, DET_POINT_TARGET_PROB_237:0, DET_POINT_TARGET_PROB_238:0, DET_POINT_TARGET_PROB_239:0, DET_POINT_TARGET_PROB_240:0, DET_RANGE_237:0, DET_RANGE_238:0, DET_RANGE_239:0, DET_RANGE_240:0, DET_RANGE_ERR_237:0, DET_RANGE_ERR_238:0, DET_RANGE_ERR_239:0, DET_RANGE_ERR_240:0, DET_RANGE_VELOCITY_237:16384, DET_RANGE_VELOCITY_238:16384, DET_RANGE_VELOCITY_239:16384, DET_RANGE_VELOCITY_240:16384, DET_RANGE_VELOCITY_ERR_237:0, DET_RANGE_VELOCITY_ERR_238:0, DET_RANGE_VELOCITY_ERR_239:0, DET_RANGE_VELOCITY_ERR_240:0, DET_RCS_237:128, DET_RCS_238:128, DET_RCS_239:128, DET_RCS_240:128, DET_SNR_237:0, DET_SNR_238:0, DET_SNR_239:0, DET_SNR_240:0, DET_SUPER_RES_TARGET_237:0, DET_SUPER_RES_TARGET_238:0, DET_SUPER_RES_TARGET_239:0, DET_SUPER_RES_TARGET_240:0, DET_VALID_FLAG_237:0, DET_VALID_FLAG_238:0, DET_VALID_FLAG_239:0, DET_VALID_FLAG_240:0]}, provided-interface=Pi_SG_Detections_237_240
      Pp_SG_Detections_241_244: nonqueued-sender-com-spec{data-element=Vdp_SG_Detections_241_244, init-value=fields=[DET_AZIMUTH_241:0, DET_AZIMUTH_242:0, DET_AZIMUTH_243:0, DET_AZIMUTH_244:0, DET_AZIMUTH_ERR_241:0, DET_AZIMUTH_ERR_242:0, DET_AZIMUTH_ERR_243:0, DET_AZIMUTH_ERR_244:0, DET_BI_STATIC_FLAG_241:0, DET_BI_STATIC_FLAG_242:0, DET_BI_STATIC_FLAG_243:0, DET_BI_STATIC_FLAG_244:0, DET_CONFD_AZIMUTH_241:0, DET_CONFD_AZIMUTH_242:0, DET_CONFD_AZIMUTH_243:0, DET_CONFD_AZIMUTH_244:0, DET_CONFD_ELEVATION_241:0, DET_CONFD_ELEVATION_242:0, DET_CONFD_ELEVATION_243:0, DET_CONFD_ELEVATION_244:0, DET_ELEVATION_241:0, DET_ELEVATION_242:0, DET_ELEVATION_243:0, DET_ELEVATION_244:0, DET_ELEVATION_ERR_241:0, DET_ELEVATION_ERR_242:0, DET_ELEVATION_ERR_243:0, DET_ELEVATION_ERR_244:0, DET_EXISTENCE_PROB_241:0, DET_EXISTENCE_PROB_242:0, DET_EXISTENCE_PROB_243:0, DET_EXISTENCE_PROB_244:0, DET_HVC_FLAG_241:0, DET_HVC_FLAG_242:0, DET_HVC_FLAG_243:0, DET_HVC_FLAG_244:0, DET_MH_CRC16_241_244:0, DET_MH_CYCLE_COUNTER_241_244:0, DET_MH_SCAN_INDEX_4LSB_241_244:0, DET_OUTSIDE_SECTOR_241:0, DET_OUTSIDE_SECTOR_242:0, DET_OUTSIDE_SECTOR_243:0, DET_OUTSIDE_SECTOR_244:0, DET_POINT_TARGET_PROB_241:0, DET_POINT_TARGET_PROB_242:0, DET_POINT_TARGET_PROB_243:0, DET_POINT_TARGET_PROB_244:0, DET_RANGE_241:0, DET_RANGE_242:0, DET_RANGE_243:0, DET_RANGE_244:0, DET_RANGE_ERR_241:0, DET_RANGE_ERR_242:0, DET_RANGE_ERR_243:0, DET_RANGE_ERR_244:0, DET_RANGE_VELOCITY_241:16384, DET_RANGE_VELOCITY_242:16384, DET_RANGE_VELOCITY_243:16384, DET_RANGE_VELOCITY_244:16384, DET_RANGE_VELOCITY_ERR_241:0, DET_RANGE_VELOCITY_ERR_242:0, DET_RANGE_VELOCITY_ERR_243:0, DET_RANGE_VELOCITY_ERR_244:0, DET_RCS_241:128, DET_RCS_242:128, DET_RCS_243:128, DET_RCS_244:128, DET_SNR_241:0, DET_SNR_242:0, DET_SNR_243:0, DET_SNR_244:0, DET_SUPER_RES_TARGET_241:0, DET_SUPER_RES_TARGET_242:0, DET_SUPER_RES_TARGET_243:0, DET_SUPER_RES_TARGET_244:0, DET_VALID_FLAG_241:0, DET_VALID_FLAG_242:0, DET_VALID_FLAG_243:0, DET_VALID_FLAG_244:0]}, provided-interface=Pi_SG_Detections_241_244
      Pp_SG_Detections_245_248: nonqueued-sender-com-spec{data-element=Vdp_SG_Detections_245_248, init-value=fields=[DET_AZIMUTH_245:0, DET_AZIMUTH_246:0, DET_AZIMUTH_247:0, DET_AZIMUTH_248:0, DET_AZIMUTH_ERR_245:0, DET_AZIMUTH_ERR_246:0, DET_AZIMUTH_ERR_247:0, DET_AZIMUTH_ERR_248:0, DET_BI_STATIC_FLAG_245:0, DET_BI_STATIC_FLAG_246:0, DET_BI_STATIC_FLAG_247:0, DET_BI_STATIC_FLAG_248:0, DET_CONFD_AZIMUTH_245:0, DET_CONFD_AZIMUTH_246:0, DET_CONFD_AZIMUTH_247:0, DET_CONFD_AZIMUTH_248:0, DET_CONFD_ELEVATION_245:0, DET_CONFD_ELEVATION_246:0, DET_CONFD_ELEVATION_247:0, DET_CONFD_ELEVATION_248:0, DET_ELEVATION_245:0, DET_ELEVATION_246:0, DET_ELEVATION_247:0, DET_ELEVATION_248:0, DET_ELEVATION_ERR_245:0, DET_ELEVATION_ERR_246:0, DET_ELEVATION_ERR_247:0, DET_ELEVATION_ERR_248:0, DET_EXISTENCE_PROB_245:0, DET_EXISTENCE_PROB_246:0, DET_EXISTENCE_PROB_247:0, DET_EXISTENCE_PROB_248:0, DET_HVC_FLAG_245:0, DET_HVC_FLAG_246:0, DET_HVC_FLAG_247:0, DET_HVC_FLAG_248:0, DET_MH_CRC16_245_248:0, DET_MH_CYCLE_COUNTER_245_248:0, DET_MH_SCAN_INDEX_4LSB_245_248:0, DET_OUTSIDE_SECTOR_245:0, DET_OUTSIDE_SECTOR_246:0, DET_OUTSIDE_SECTOR_247:0, DET_OUTSIDE_SECTOR_248:0, DET_POINT_TARGET_PROB_245:0, DET_POINT_TARGET_PROB_246:0, DET_POINT_TARGET_PROB_247:0, DET_POINT_TARGET_PROB_248:0, DET_RANGE_245:0, DET_RANGE_246:0, DET_RANGE_247:0, DET_RANGE_248:0, DET_RANGE_ERR_245:0, DET_RANGE_ERR_246:0, DET_RANGE_ERR_247:0, DET_RANGE_ERR_248:0, DET_RANGE_VELOCITY_245:16384, DET_RANGE_VELOCITY_246:16384, DET_RANGE_VELOCITY_247:16384, DET_RANGE_VELOCITY_248:16384, DET_RANGE_VELOCITY_ERR_245:0, DET_RANGE_VELOCITY_ERR_246:0, DET_RANGE_VELOCITY_ERR_247:0, DET_RANGE_VELOCITY_ERR_248:0, DET_RCS_245:128, DET_RCS_246:128, DET_RCS_247:128, DET_RCS_248:128, DET_SNR_245:0, DET_SNR_246:0, DET_SNR_247:0, DET_SNR_248:0, DET_SUPER_RES_TARGET_245:0, DET_SUPER_RES_TARGET_246:0, DET_SUPER_RES_TARGET_247:0, DET_SUPER_RES_TARGET_248:0, DET_VALID_FLAG_245:0, DET_VALID_FLAG_246:0, DET_VALID_FLAG_247:0, DET_VALID_FLAG_248:0]}, provided-interface=Pi_SG_Detections_245_248
      Pp_SG_Detections_249_252: nonqueued-sender-com-spec{data-element=Vdp_SG_Detections_249_252, init-value=fields=[DET_AZIMUTH_249:0, DET_AZIMUTH_250:0, DET_AZIMUTH_251:0, DET_AZIMUTH_252:0, DET_AZIMUTH_ERR_249:0, DET_AZIMUTH_ERR_250:0, DET_AZIMUTH_ERR_251:0, DET_AZIMUTH_ERR_252:0, DET_BI_STATIC_FLAG_249:0, DET_BI_STATIC_FLAG_250:0, DET_BI_STATIC_FLAG_251:0, DET_BI_STATIC_FLAG_252:0, DET_CONFD_AZIMUTH_249:0, DET_CONFD_AZIMUTH_250:0, DET_CONFD_AZIMUTH_251:0, DET_CONFD_AZIMUTH_252:0, DET_CONFD_ELEVATION_249:0, DET_CONFD_ELEVATION_250:0, DET_CONFD_ELEVATION_251:0, DET_CONFD_ELEVATION_252:0, DET_ELEVATION_249:0, DET_ELEVATION_250:0, DET_ELEVATION_251:0, DET_ELEVATION_252:0, DET_ELEVATION_ERR_249:0, DET_ELEVATION_ERR_250:0, DET_ELEVATION_ERR_251:0, DET_ELEVATION_ERR_252:0, DET_EXISTENCE_PROB_249:0, DET_EXISTENCE_PROB_250:0, DET_EXISTENCE_PROB_251:0, DET_EXISTENCE_PROB_252:0, DET_HVC_FLAG_249:0, DET_HVC_FLAG_250:0, DET_HVC_FLAG_251:0, DET_HVC_FLAG_252:0, DET_MH_CRC16_249_252:0, DET_MH_CYCLE_COUNTER_249_252:0, DET_MH_SCAN_INDEX_4LSB_249_252:0, DET_OUTSIDE_SECTOR_249:0, DET_OUTSIDE_SECTOR_250:0, DET_OUTSIDE_SECTOR_251:0, DET_OUTSIDE_SECTOR_252:0, DET_POINT_TARGET_PROB_249:0, DET_POINT_TARGET_PROB_250:0, DET_POINT_TARGET_PROB_251:0, DET_POINT_TARGET_PROB_252:0, DET_RANGE_249:0, DET_RANGE_250:0, DET_RANGE_251:0, DET_RANGE_252:0, DET_RANGE_ERR_249:0, DET_RANGE_ERR_250:0, DET_RANGE_ERR_251:0, DET_RANGE_ERR_252:0, DET_RANGE_VELOCITY_249:16384, DET_RANGE_VELOCITY_250:16384, DET_RANGE_VELOCITY_251:16384, DET_RANGE_VELOCITY_252:16384, DET_RANGE_VELOCITY_ERR_249:0, DET_RANGE_VELOCITY_ERR_250:0, DET_RANGE_VELOCITY_ERR_251:0, DET_RANGE_VELOCITY_ERR_252:0, DET_RCS_249:128, DET_RCS_250:128, DET_RCS_251:128, DET_RCS_252:128, DET_SNR_249:0, DET_SNR_250:0, DET_SNR_251:0, DET_SNR_252:0, DET_SUPER_RES_TARGET_249:0, DET_SUPER_RES_TARGET_250:0, DET_SUPER_RES_TARGET_251:0, DET_SUPER_RES_TARGET_252:0, DET_VALID_FLAG_249:0, DET_VALID_FLAG_250:0, DET_VALID_FLAG_251:0, DET_VALID_FLAG_252:0]}, provided-interface=Pi_SG_Detections_249_252
      Pp_SG_Detections_253_256: nonqueued-sender-com-spec{data-element=Vdp_SG_Detections_253_256, init-value=fields=[DET_AZIMUTH_253:0, DET_AZIMUTH_254:0, DET_AZIMUTH_255:0, DET_AZIMUTH_256:0, DET_AZIMUTH_ERR_253:0, DET_AZIMUTH_ERR_254:0, DET_AZIMUTH_ERR_255:0, DET_AZIMUTH_ERR_256:0, DET_BI_STATIC_FLAG_253:0, DET_BI_STATIC_FLAG_254:0, DET_BI_STATIC_FLAG_255:0, DET_BI_STATIC_FLAG_256:0, DET_CONFD_AZIMUTH_253:0, DET_CONFD_AZIMUTH_254:0, DET_CONFD_AZIMUTH_255:0, DET_CONFD_AZIMUTH_256:0, DET_CONFD_ELEVATION_253:0, DET_CONFD_ELEVATION_254:0, DET_CONFD_ELEVATION_255:0, DET_CONFD_ELEVATION_256:0, DET_ELEVATION_253:0, DET_ELEVATION_254:0, DET_ELEVATION_255:0, DET_ELEVATION_256:0, DET_ELEVATION_ERR_253:0, DET_ELEVATION_ERR_254:0, DET_ELEVATION_ERR_255:0, DET_ELEVATION_ERR_256:0, DET_EXISTENCE_PROB_253:0, DET_EXISTENCE_PROB_254:0, DET_EXISTENCE_PROB_255:0, DET_EXISTENCE_PROB_256:0, DET_HVC_FLAG_253:0, DET_HVC_FLAG_254:0, DET_HVC_FLAG_255:0, DET_HVC_FLAG_256:0, DET_MH_CRC16_253_256:0, DET_MH_CYCLE_COUNTER_253_256:0, DET_MH_SCAN_INDEX_4LSB_253_256:0, DET_OUTSIDE_SECTOR_253:0, DET_OUTSIDE_SECTOR_254:0, DET_OUTSIDE_SECTOR_255:0, DET_OUTSIDE_SECTOR_256:0, DET_POINT_TARGET_PROB_253:0, DET_POINT_TARGET_PROB_254:0, DET_POINT_TARGET_PROB_255:0, DET_POINT_TARGET_PROB_256:0, DET_RANGE_253:0, DET_RANGE_254:0, DET_RANGE_255:0, DET_RANGE_256:0, DET_RANGE_ERR_253:0, DET_RANGE_ERR_254:0, DET_RANGE_ERR_255:0, DET_RANGE_ERR_256:0, DET_RANGE_VELOCITY_253:16384, DET_RANGE_VELOCITY_254:16384, DET_RANGE_VELOCITY_255:16384, DET_RANGE_VELOCITY_256:16384, DET_RANGE_VELOCITY_ERR_253:0, DET_RANGE_VELOCITY_ERR_254:0, DET_RANGE_VELOCITY_ERR_255:0, DET_RANGE_VELOCITY_ERR_256:0, DET_RCS_253:128, DET_RCS_254:128, DET_RCS_255:128, DET_RCS_256:128, DET_SNR_253:0, DET_SNR_254:0, DET_SNR_255:0, DET_SNR_256:0, DET_SUPER_RES_TARGET_253:0, DET_SUPER_RES_TARGET_254:0, DET_SUPER_RES_TARGET_255:0, DET_SUPER_RES_TARGET_256:0, DET_VALID_FLAG_253:0, DET_VALID_FLAG_254:0, DET_VALID_FLAG_255:0, DET_VALID_FLAG_256:0]}, provided-interface=Pi_SG_Detections_253_256
      Pp_SG_Detections_257_260: nonqueued-sender-com-spec{data-element=Vdp_SG_Detections_257_260, init-value=fields=[DET_AZIMUTH_257:0, DET_AZIMUTH_258:0, DET_AZIMUTH_259:0, DET_AZIMUTH_260:0, DET_AZIMUTH_ERR_257:0, DET_AZIMUTH_ERR_258:0, DET_AZIMUTH_ERR_259:0, DET_AZIMUTH_ERR_260:0, DET_BI_STATIC_FLAG_257:0, DET_BI_STATIC_FLAG_258:0, DET_BI_STATIC_FLAG_259:0, DET_BI_STATIC_FLAG_260:0, DET_CONFD_AZIMUTH_257:0, DET_CONFD_AZIMUTH_258:0, DET_CONFD_AZIMUTH_259:0, DET_CONFD_AZIMUTH_260:0, DET_CONFD_ELEVATION_257:0, DET_CONFD_ELEVATION_258:0, DET_CONFD_ELEVATION_259:0, DET_CONFD_ELEVATION_260:0, DET_ELEVATION_257:0, DET_ELEVATION_258:0, DET_ELEVATION_259:0, DET_ELEVATION_260:0, DET_ELEVATION_ERR_257:0, DET_ELEVATION_ERR_258:0, DET_ELEVATION_ERR_259:0, DET_ELEVATION_ERR_260:0, DET_EXISTENCE_PROB_257:0, DET_EXISTENCE_PROB_258:0, DET_EXISTENCE_PROB_259:0, DET_EXISTENCE_PROB_260:0, DET_HVC_FLAG_257:0, DET_HVC_FLAG_258:0, DET_HVC_FLAG_259:0, DET_HVC_FLAG_260:0, DET_MH_CRC16_257_260:0, DET_MH_CYCLE_COUNTER_257_260:0, DET_MH_SCAN_INDEX_4LSB_257_260:0, DET_OUTSIDE_SECTOR_257:0, DET_OUTSIDE_SECTOR_258:0, DET_OUTSIDE_SECTOR_259:0, DET_OUTSIDE_SECTOR_260:0, DET_POINT_TARGET_PROB_257:0, DET_POINT_TARGET_PROB_258:0, DET_POINT_TARGET_PROB_259:0, DET_POINT_TARGET_PROB_260:0, DET_RANGE_257:0, DET_RANGE_258:0, DET_RANGE_259:0, DET_RANGE_260:0, DET_RANGE_ERR_257:0, DET_RANGE_ERR_258:0, DET_RANGE_ERR_259:0, DET_RANGE_ERR_260:0, DET_RANGE_VELOCITY_257:16384, DET_RANGE_VELOCITY_258:16384, DET_RANGE_VELOCITY_259:16384, DET_RANGE_VELOCITY_260:16384, DET_RANGE_VELOCITY_ERR_257:0, DET_RANGE_VELOCITY_ERR_258:0, DET_RANGE_VELOCITY_ERR_259:0, DET_RANGE_VELOCITY_ERR_260:0, DET_RCS_257:128, DET_RCS_258:128, DET_RCS_259:128, DET_RCS_260:128, DET_SNR_257:0, DET_SNR_258:0, DET_SNR_259:0, DET_SNR_260:0, DET_SUPER_RES_TARGET_257:0, DET_SUPER_RES_TARGET_258:0, DET_SUPER_RES_TARGET_259:0, DET_SUPER_RES_TARGET_260:0, DET_VALID_FLAG_257:0, DET_VALID_FLAG_258:0, DET_VALID_FLAG_259:0, DET_VALID_FLAG_260:0]}, provided-interface=Pi_SG_Detections_257_260
      Pp_SG_Detections_261_264: nonqueued-sender-com-spec{data-element=Vdp_SG_Detections_261_264, init-value=fields=[DET_AZIMUTH_261:0, DET_AZIMUTH_262:0, DET_AZIMUTH_263:0, DET_AZIMUTH_264:0, DET_AZIMUTH_ERR_261:0, DET_AZIMUTH_ERR_262:0, DET_AZIMUTH_ERR_263:0, DET_AZIMUTH_ERR_264:0, DET_BI_STATIC_FLAG_261:0, DET_BI_STATIC_FLAG_262:0, DET_BI_STATIC_FLAG_263:0, DET_BI_STATIC_FLAG_264:0, DET_CONFD_AZIMUTH_261:0, DET_CONFD_AZIMUTH_262:0, DET_CONFD_AZIMUTH_263:0, DET_CONFD_AZIMUTH_264:0, DET_CONFD_ELEVATION_261:0, DET_CONFD_ELEVATION_262:0, DET_CONFD_ELEVATION_263:0, DET_CONFD_ELEVATION_264:0, DET_ELEVATION_261:0, DET_ELEVATION_262:0, DET_ELEVATION_263:0, DET_ELEVATION_264:0, DET_ELEVATION_ERR_261:0, DET_ELEVATION_ERR_262:0, DET_ELEVATION_ERR_263:0, DET_ELEVATION_ERR_264:0, DET_EXISTENCE_PROB_261:0, DET_EXISTENCE_PROB_262:0, DET_EXISTENCE_PROB_263:0, DET_EXISTENCE_PROB_264:0, DET_HVC_FLAG_261:0, DET_HVC_FLAG_262:0, DET_HVC_FLAG_263:0, DET_HVC_FLAG_264:0, DET_MH_CRC16_261_264:0, DET_MH_CYCLE_COUNTER_261_264:0, DET_MH_SCAN_INDEX_4LSB_261_264:0, DET_OUTSIDE_SECTOR_261:0, DET_OUTSIDE_SECTOR_262:0, DET_OUTSIDE_SECTOR_263:0, DET_OUTSIDE_SECTOR_264:0, DET_POINT_TARGET_PROB_261:0, DET_POINT_TARGET_PROB_262:0, DET_POINT_TARGET_PROB_263:0, DET_POINT_TARGET_PROB_264:0, DET_RANGE_261:0, DET_RANGE_262:0, DET_RANGE_263:0, DET_RANGE_264:0, DET_RANGE_ERR_261:0, DET_RANGE_ERR_262:0, DET_RANGE_ERR_263:0, DET_RANGE_ERR_264:0, DET_RANGE_VELOCITY_261:16384, DET_RANGE_VELOCITY_262:16384, DET_RANGE_VELOCITY_263:16384, DET_RANGE_VELOCITY_264:16384, DET_RANGE_VELOCITY_ERR_261:0, DET_RANGE_VELOCITY_ERR_262:0, DET_RANGE_VELOCITY_ERR_263:0, DET_RANGE_VELOCITY_ERR_264:0, DET_RCS_261:128, DET_RCS_262:128, DET_RCS_263:128, DET_RCS_264:128, DET_SNR_261:0, DET_SNR_262:0, DET_SNR_263:0, DET_SNR_264:0, DET_SUPER_RES_TARGET_261:0, DET_SUPER_RES_TARGET_262:0, DET_SUPER_RES_TARGET_263:0, DET_SUPER_RES_TARGET_264:0, DET_VALID_FLAG_261:0, DET_VALID_FLAG_262:0, DET_VALID_FLAG_263:0, DET_VALID_FLAG_264:0]}, provided-interface=Pi_SG_Detections_261_264
      Pp_SG_Detections_265_268: nonqueued-sender-com-spec{data-element=Vdp_SG_Detections_265_268, init-value=fields=[DET_AZIMUTH_265:0, DET_AZIMUTH_266:0, DET_AZIMUTH_267:0, DET_AZIMUTH_268:0, DET_AZIMUTH_ERR_265:0, DET_AZIMUTH_ERR_266:0, DET_AZIMUTH_ERR_267:0, DET_AZIMUTH_ERR_268:0, DET_BI_STATIC_FLAG_265:0, DET_BI_STATIC_FLAG_266:0, DET_BI_STATIC_FLAG_267:0, DET_BI_STATIC_FLAG_268:0, DET_CONFD_AZIMUTH_265:0, DET_CONFD_AZIMUTH_266:0, DET_CONFD_AZIMUTH_267:0, DET_CONFD_AZIMUTH_268:0, DET_CONFD_ELEVATION_265:0, DET_CONFD_ELEVATION_266:0, DET_CONFD_ELEVATION_267:0, DET_CONFD_ELEVATION_268:0, DET_ELEVATION_265:0, DET_ELEVATION_266:0, DET_ELEVATION_267:0, DET_ELEVATION_268:0, DET_ELEVATION_ERR_265:0, DET_ELEVATION_ERR_266:0, DET_ELEVATION_ERR_267:0, DET_ELEVATION_ERR_268:0, DET_EXISTENCE_PROB_265:0, DET_EXISTENCE_PROB_266:0, DET_EXISTENCE_PROB_267:0, DET_EXISTENCE_PROB_268:0, DET_HVC_FLAG_265:0, DET_HVC_FLAG_266:0, DET_HVC_FLAG_267:0, DET_HVC_FLAG_268:0, DET_MH_CRC16_265_268:0, DET_MH_CYCLE_COUNTER_265_268:0, DET_MH_SCAN_INDEX_4LSB_265_268:0, DET_OUTSIDE_SECTOR_265:0, DET_OUTSIDE_SECTOR_266:0, DET_OUTSIDE_SECTOR_267:0, DET_OUTSIDE_SECTOR_268:0, DET_POINT_TARGET_PROB_265:0, DET_POINT_TARGET_PROB_266:0, DET_POINT_TARGET_PROB_267:0, DET_POINT_TARGET_PROB_268:0, DET_RANGE_265:0, DET_RANGE_266:0, DET_RANGE_267:0, DET_RANGE_268:0, DET_RANGE_ERR_265:0, DET_RANGE_ERR_266:0, DET_RANGE_ERR_267:0, DET_RANGE_ERR_268:0, DET_RANGE_VELOCITY_265:16384, DET_RANGE_VELOCITY_266:16384, DET_RANGE_VELOCITY_267:16384, DET_RANGE_VELOCITY_268:16384, DET_RANGE_VELOCITY_ERR_265:0, DET_RANGE_VELOCITY_ERR_266:0, DET_RANGE_VELOCITY_ERR_267:0, DET_RANGE_VELOCITY_ERR_268:0, DET_RCS_265:128, DET_RCS_266:128, DET_RCS_267:128, DET_RCS_268:128, DET_SNR_265:0, DET_SNR_266:0, DET_SNR_267:0, DET_SNR_268:0, DET_SUPER_RES_TARGET_265:0, DET_SUPER_RES_TARGET_266:0, DET_SUPER_RES_TARGET_267:0, DET_SUPER_RES_TARGET_268:0, DET_VALID_FLAG_265:0, DET_VALID_FLAG_266:0, DET_VALID_FLAG_267:0, DET_VALID_FLAG_268:0]}, provided-interface=Pi_SG_Detections_265_268
      Pp_SG_Detections_269_272: nonqueued-sender-com-spec{data-element=Vdp_SG_Detections_269_272, init-value=fields=[DET_AZIMUTH_269:0, DET_AZIMUTH_270:0, DET_AZIMUTH_271:0, DET_AZIMUTH_272:0, DET_AZIMUTH_ERR_269:0, DET_AZIMUTH_ERR_270:0, DET_AZIMUTH_ERR_271:0, DET_AZIMUTH_ERR_272:0, DET_BI_STATIC_FLAG_269:0, DET_BI_STATIC_FLAG_270:0, DET_BI_STATIC_FLAG_271:0, DET_BI_STATIC_FLAG_272:0, DET_CONFD_AZIMUTH_269:0, DET_CONFD_AZIMUTH_270:0, DET_CONFD_AZIMUTH_271:0, DET_CONFD_AZIMUTH_272:0, DET_CONFD_ELEVATION_269:0, DET_CONFD_ELEVATION_270:0, DET_CONFD_ELEVATION_271:0, DET_CONFD_ELEVATION_272:0, DET_ELEVATION_269:0, DET_ELEVATION_270:0, DET_ELEVATION_271:0, DET_ELEVATION_272:0, DET_ELEVATION_ERR_269:0, DET_ELEVATION_ERR_270:0, DET_ELEVATION_ERR_271:0, DET_ELEVATION_ERR_272:0, DET_EXISTENCE_PROB_269:0, DET_EXISTENCE_PROB_270:0, DET_EXISTENCE_PROB_271:0, DET_EXISTENCE_PROB_272:0, DET_HVC_FLAG_269:0, DET_HVC_FLAG_270:0, DET_HVC_FLAG_271:0, DET_HVC_FLAG_272:0, DET_MH_CRC16_269_272:0, DET_MH_CYCLE_COUNTER_269_272:0, DET_MH_SCAN_INDEX_4LSB_269_272:0, DET_OUTSIDE_SECTOR_269:0, DET_OUTSIDE_SECTOR_270:0, DET_OUTSIDE_SECTOR_271:0, DET_OUTSIDE_SECTOR_272:0, DET_POINT_TARGET_PROB_269:0, DET_POINT_TARGET_PROB_270:0, DET_POINT_TARGET_PROB_271:0, DET_POINT_TARGET_PROB_272:0, DET_RANGE_269:0, DET_RANGE_270:0, DET_RANGE_271:0, DET_RANGE_272:0, DET_RANGE_ERR_269:0, DET_RANGE_ERR_270:0, DET_RANGE_ERR_271:0, DET_RANGE_ERR_272:0, DET_RANGE_VELOCITY_269:16384, DET_RANGE_VELOCITY_270:16384, DET_RANGE_VELOCITY_271:16384, DET_RANGE_VELOCITY_272:16384, DET_RANGE_VELOCITY_ERR_269:0, DET_RANGE_VELOCITY_ERR_270:0, DET_RANGE_VELOCITY_ERR_271:0, DET_RANGE_VELOCITY_ERR_272:0, DET_RCS_269:128, DET_RCS_270:128, DET_RCS_271:128, DET_RCS_272:128, DET_SNR_269:0, DET_SNR_270:0, DET_SNR_271:0, DET_SNR_272:0, DET_SUPER_RES_TARGET_269:0, DET_SUPER_RES_TARGET_270:0, DET_SUPER_RES_TARGET_271:0, DET_SUPER_RES_TARGET_272:0, DET_VALID_FLAG_269:0, DET_VALID_FLAG_270:0, DET_VALID_FLAG_271:0, DET_VALID_FLAG_272:0]}, provided-interface=Pi_SG_Detections_269_272
      Pp_SG_Detections_273_276: nonqueued-sender-com-spec{data-element=Vdp_SG_Detections_273_276, init-value=fields=[DET_AZIMUTH_273:0, DET_AZIMUTH_274:0, DET_AZIMUTH_275:0, DET_AZIMUTH_276:0, DET_AZIMUTH_ERR_273:0, DET_AZIMUTH_ERR_274:0, DET_AZIMUTH_ERR_275:0, DET_AZIMUTH_ERR_276:0, DET_BI_STATIC_FLAG_273:0, DET_BI_STATIC_FLAG_274:0, DET_BI_STATIC_FLAG_275:0, DET_BI_STATIC_FLAG_276:0, DET_CONFD_AZIMUTH_273:0, DET_CONFD_AZIMUTH_274:0, DET_CONFD_AZIMUTH_275:0, DET_CONFD_AZIMUTH_276:0, DET_CONFD_ELEVATION_273:0, DET_CONFD_ELEVATION_274:0, DET_CONFD_ELEVATION_275:0, DET_CONFD_ELEVATION_276:0, DET_ELEVATION_273:0, DET_ELEVATION_274:0, DET_ELEVATION_275:0, DET_ELEVATION_276:0, DET_ELEVATION_ERR_273:0, DET_ELEVATION_ERR_274:0, DET_ELEVATION_ERR_275:0, DET_ELEVATION_ERR_276:0, DET_EXISTENCE_PROB_273:0, DET_EXISTENCE_PROB_274:0, DET_EXISTENCE_PROB_275:0, DET_EXISTENCE_PROB_276:0, DET_HVC_FLAG_273:0, DET_HVC_FLAG_274:0, DET_HVC_FLAG_275:0, DET_HVC_FLAG_276:0, DET_MH_CRC16_273_276:0, DET_MH_CYCLE_COUNTER_273_276:0, DET_MH_SCAN_INDEX_4LSB_273_276:0, DET_OUTSIDE_SECTOR_273:0, DET_OUTSIDE_SECTOR_274:0, DET_OUTSIDE_SECTOR_275:0, DET_OUTSIDE_SECTOR_276:0, DET_POINT_TARGET_PROB_273:0, DET_POINT_TARGET_PROB_274:0, DET_POINT_TARGET_PROB_275:0, DET_POINT_TARGET_PROB_276:0, DET_RANGE_273:0, DET_RANGE_274:0, DET_RANGE_275:0, DET_RANGE_276:0, DET_RANGE_ERR_273:0, DET_RANGE_ERR_274:0, DET_RANGE_ERR_275:0, DET_RANGE_ERR_276:0, DET_RANGE_VELOCITY_273:16384, DET_RANGE_VELOCITY_274:16384, DET_RANGE_VELOCITY_275:16384, DET_RANGE_VELOCITY_276:16384, DET_RANGE_VELOCITY_ERR_273:0, DET_RANGE_VELOCITY_ERR_274:0, DET_RANGE_VELOCITY_ERR_275:0, DET_RANGE_VELOCITY_ERR_276:0, DET_RCS_273:128, DET_RCS_274:128, DET_RCS_275:128, DET_RCS_276:128, DET_SNR_273:0, DET_SNR_274:0, DET_SNR_275:0, DET_SNR_276:0, DET_SUPER_RES_TARGET_273:0, DET_SUPER_RES_TARGET_274:0, DET_SUPER_RES_TARGET_275:0, DET_SUPER_RES_TARGET_276:0, DET_VALID_FLAG_273:0, DET_VALID_FLAG_274:0, DET_VALID_FLAG_275:0, DET_VALID_FLAG_276:0]}, provided-interface=Pi_SG_Detections_273_276
      Pp_SG_Detections_277_280: nonqueued-sender-com-spec{data-element=Vdp_SG_Detections_277_280, init-value=fields=[DET_AZIMUTH_277:0, DET_AZIMUTH_278:0, DET_AZIMUTH_279:0, DET_AZIMUTH_280:0, DET_AZIMUTH_ERR_277:0, DET_AZIMUTH_ERR_278:0, DET_AZIMUTH_ERR_279:0, DET_AZIMUTH_ERR_280:0, DET_BI_STATIC_FLAG_277:0, DET_BI_STATIC_FLAG_278:0, DET_BI_STATIC_FLAG_279:0, DET_BI_STATIC_FLAG_280:0, DET_CONFD_AZIMUTH_277:0, DET_CONFD_AZIMUTH_278:0, DET_CONFD_AZIMUTH_279:0, DET_CONFD_AZIMUTH_280:0, DET_CONFD_ELEVATION_277:0, DET_CONFD_ELEVATION_278:0, DET_CONFD_ELEVATION_279:0, DET_CONFD_ELEVATION_280:0, DET_ELEVATION_277:0, DET_ELEVATION_278:0, DET_ELEVATION_279:0, DET_ELEVATION_280:0, DET_ELEVATION_ERR_277:0, DET_ELEVATION_ERR_278:0, DET_ELEVATION_ERR_279:0, DET_ELEVATION_ERR_280:0, DET_EXISTENCE_PROB_277:0, DET_EXISTENCE_PROB_278:0, DET_EXISTENCE_PROB_279:0, DET_EXISTENCE_PROB_280:0, DET_HVC_FLAG_277:0, DET_HVC_FLAG_278:0, DET_HVC_FLAG_279:0, DET_HVC_FLAG_280:0, DET_MH_CRC16_277_280:0, DET_MH_CYCLE_COUNTER_277_280:0, DET_MH_SCAN_INDEX_4LSB_277_280:0, DET_OUTSIDE_SECTOR_277:0, DET_OUTSIDE_SECTOR_278:0, DET_OUTSIDE_SECTOR_279:0, DET_OUTSIDE_SECTOR_280:0, DET_POINT_TARGET_PROB_277:0, DET_POINT_TARGET_PROB_278:0, DET_POINT_TARGET_PROB_279:0, DET_POINT_TARGET_PROB_280:0, DET_RANGE_277:0, DET_RANGE_278:0, DET_RANGE_279:0, DET_RANGE_280:0, DET_RANGE_ERR_277:0, DET_RANGE_ERR_278:0, DET_RANGE_ERR_279:0, DET_RANGE_ERR_280:0, DET_RANGE_VELOCITY_277:16384, DET_RANGE_VELOCITY_278:16384, DET_RANGE_VELOCITY_279:16384, DET_RANGE_VELOCITY_280:16384, DET_RANGE_VELOCITY_ERR_277:0, DET_RANGE_VELOCITY_ERR_278:0, DET_RANGE_VELOCITY_ERR_279:0, DET_RANGE_VELOCITY_ERR_280:0, DET_RCS_277:128, DET_RCS_278:128, DET_RCS_279:128, DET_RCS_280:128, DET_SNR_277:0, DET_SNR_278:0, DET_SNR_279:0, DET_SNR_280:0, DET_SUPER_RES_TARGET_277:0, DET_SUPER_RES_TARGET_278:0, DET_SUPER_RES_TARGET_279:0, DET_SUPER_RES_TARGET_280:0, DET_VALID_FLAG_277:0, DET_VALID_FLAG_278:0, DET_VALID_FLAG_279:0, DET_VALID_FLAG_280:0]}, provided-interface=Pi_SG_Detections_277_280
      Pp_SG_Detections_281_284: nonqueued-sender-com-spec{data-element=Vdp_SG_Detections_281_284, init-value=fields=[DET_AZIMUTH_281:0, DET_AZIMUTH_282:0, DET_AZIMUTH_283:0, DET_AZIMUTH_284:0, DET_AZIMUTH_ERR_281:0, DET_AZIMUTH_ERR_282:0, DET_AZIMUTH_ERR_283:0, DET_AZIMUTH_ERR_284:0, DET_BI_STATIC_FLAG_281:0, DET_BI_STATIC_FLAG_282:0, DET_BI_STATIC_FLAG_283:0, DET_BI_STATIC_FLAG_284:0, DET_CONFD_AZIMUTH_281:0, DET_CONFD_AZIMUTH_282:0, DET_CONFD_AZIMUTH_283:0, DET_CONFD_AZIMUTH_284:0, DET_CONFD_ELEVATION_281:0, DET_CONFD_ELEVATION_282:0, DET_CONFD_ELEVATION_283:0, DET_CONFD_ELEVATION_284:0, DET_ELEVATION_281:0, DET_ELEVATION_282:0, DET_ELEVATION_283:0, DET_ELEVATION_284:0, DET_ELEVATION_ERR_281:0, DET_ELEVATION_ERR_282:0, DET_ELEVATION_ERR_283:0, DET_ELEVATION_ERR_284:0, DET_EXISTENCE_PROB_281:0, DET_EXISTENCE_PROB_282:0, DET_EXISTENCE_PROB_283:0, DET_EXISTENCE_PROB_284:0, DET_HVC_FLAG_281:0, DET_HVC_FLAG_282:0, DET_HVC_FLAG_283:0, DET_HVC_FLAG_284:0, DET_MH_CRC16_281_284:0, DET_MH_CYCLE_COUNTER_281_284:0, DET_MH_SCAN_INDEX_4LSB_281_284:0, DET_OUTSIDE_SECTOR_281:0, DET_OUTSIDE_SECTOR_282:0, DET_OUTSIDE_SECTOR_283:0, DET_OUTSIDE_SECTOR_284:0, DET_POINT_TARGET_PROB_281:0, DET_POINT_TARGET_PROB_282:0, DET_POINT_TARGET_PROB_283:0, DET_POINT_TARGET_PROB_284:0, DET_RANGE_281:0, DET_RANGE_282:0, DET_RANGE_283:0, DET_RANGE_284:0, DET_RANGE_ERR_281:0, DET_RANGE_ERR_282:0, DET_RANGE_ERR_283:0, DET_RANGE_ERR_284:0, DET_RANGE_VELOCITY_281:16384, DET_RANGE_VELOCITY_282:16384, DET_RANGE_VELOCITY_283:16384, DET_RANGE_VELOCITY_284:16384, DET_RANGE_VELOCITY_ERR_281:0, DET_RANGE_VELOCITY_ERR_282:0, DET_RANGE_VELOCITY_ERR_283:0, DET_RANGE_VELOCITY_ERR_284:0, DET_RCS_281:128, DET_RCS_282:128, DET_RCS_283:128, DET_RCS_284:128, DET_SNR_281:0, DET_SNR_282:0, DET_SNR_283:0, DET_SNR_284:0, DET_SUPER_RES_TARGET_281:0, DET_SUPER_RES_TARGET_282:0, DET_SUPER_RES_TARGET_283:0, DET_SUPER_RES_TARGET_284:0, DET_VALID_FLAG_281:0, DET_VALID_FLAG_282:0, DET_VALID_FLAG_283:0, DET_VALID_FLAG_284:0]}, provided-interface=Pi_SG_Detections_281_284
      Pp_SG_Detections_285_288: nonqueued-sender-com-spec{data-element=Vdp_SG_Detections_285_288, init-value=fields=[DET_AZIMUTH_285:0, DET_AZIMUTH_286:0, DET_AZIMUTH_287:0, DET_AZIMUTH_288:0, DET_AZIMUTH_ERR_285:0, DET_AZIMUTH_ERR_286:0, DET_AZIMUTH_ERR_287:0, DET_AZIMUTH_ERR_288:0, DET_BI_STATIC_FLAG_285:0, DET_BI_STATIC_FLAG_286:0, DET_BI_STATIC_FLAG_287:0, DET_BI_STATIC_FLAG_288:0, DET_CONFD_AZIMUTH_285:0, DET_CONFD_AZIMUTH_286:0, DET_CONFD_AZIMUTH_287:0, DET_CONFD_AZIMUTH_288:0, DET_CONFD_ELEVATION_285:0, DET_CONFD_ELEVATION_286:0, DET_CONFD_ELEVATION_287:0, DET_CONFD_ELEVATION_288:0, DET_ELEVATION_285:0, DET_ELEVATION_286:0, DET_ELEVATION_287:0, DET_ELEVATION_288:0, DET_ELEVATION_ERR_285:0, DET_ELEVATION_ERR_286:0, DET_ELEVATION_ERR_287:0, DET_ELEVATION_ERR_288:0, DET_EXISTENCE_PROB_285:0, DET_EXISTENCE_PROB_286:0, DET_EXISTENCE_PROB_287:0, DET_EXISTENCE_PROB_288:0, DET_HVC_FLAG_285:0, DET_HVC_FLAG_286:0, DET_HVC_FLAG_287:0, DET_HVC_FLAG_288:0, DET_MH_CRC16_285_288:0, DET_MH_CYCLE_COUNTER_285_288:0, DET_MH_SCAN_INDEX_4LSB_285_288:0, DET_OUTSIDE_SECTOR_285:0, DET_OUTSIDE_SECTOR_286:0, DET_OUTSIDE_SECTOR_287:0, DET_OUTSIDE_SECTOR_288:0, DET_POINT_TARGET_PROB_285:0, DET_POINT_TARGET_PROB_286:0, DET_POINT_TARGET_PROB_287:0, DET_POINT_TARGET_PROB_288:0, DET_RANGE_285:0, DET_RANGE_286:0, DET_RANGE_287:0, DET_RANGE_288:0, DET_RANGE_ERR_285:0, DET_RANGE_ERR_286:0, DET_RANGE_ERR_287:0, DET_RANGE_ERR_288:0, DET_RANGE_VELOCITY_285:16384, DET_RANGE_VELOCITY_286:16384, DET_RANGE_VELOCITY_287:16384, DET_RANGE_VELOCITY_288:16384, DET_RANGE_VELOCITY_ERR_285:0, DET_RANGE_VELOCITY_ERR_286:0, DET_RANGE_VELOCITY_ERR_287:0, DET_RANGE_VELOCITY_ERR_288:0, DET_RCS_285:128, DET_RCS_286:128, DET_RCS_287:128, DET_RCS_288:128, DET_SNR_285:0, DET_SNR_286:0, DET_SNR_287:0, DET_SNR_288:0, DET_SUPER_RES_TARGET_285:0, DET_SUPER_RES_TARGET_286:0, DET_SUPER_RES_TARGET_287:0, DET_SUPER_RES_TARGET_288:0, DET_VALID_FLAG_285:0, DET_VALID_FLAG_286:0, DET_VALID_FLAG_287:0, DET_VALID_FLAG_288:0]}, provided-interface=Pi_SG_Detections_285_288
      Pp_SG_Detections_289_292: nonqueued-sender-com-spec{data-element=Vdp_SG_Detections_289_292, init-value=fields=[DET_AZIMUTH_289:0, DET_AZIMUTH_290:0, DET_AZIMUTH_291:0, DET_AZIMUTH_292:0, DET_AZIMUTH_ERR_289:0, DET_AZIMUTH_ERR_290:0, DET_AZIMUTH_ERR_291:0, DET_AZIMUTH_ERR_292:0, DET_BI_STATIC_FLAG_289:0, DET_BI_STATIC_FLAG_290:0, DET_BI_STATIC_FLAG_291:0, DET_BI_STATIC_FLAG_292:0, DET_CONFD_AZIMUTH_289:0, DET_CONFD_AZIMUTH_290:0, DET_CONFD_AZIMUTH_291:0, DET_CONFD_AZIMUTH_292:0, DET_CONFD_ELEVATION_289:0, DET_CONFD_ELEVATION_290:0, DET_CONFD_ELEVATION_291:0, DET_CONFD_ELEVATION_292:0, DET_ELEVATION_289:0, DET_ELEVATION_290:0, DET_ELEVATION_291:0, DET_ELEVATION_292:0, DET_ELEVATION_ERR_289:0, DET_ELEVATION_ERR_290:0, DET_ELEVATION_ERR_291:0, DET_ELEVATION_ERR_292:0, DET_EXISTENCE_PROB_289:0, DET_EXISTENCE_PROB_290:0, DET_EXISTENCE_PROB_291:0, DET_EXISTENCE_PROB_292:0, DET_HVC_FLAG_289:0, DET_HVC_FLAG_290:0, DET_HVC_FLAG_291:0, DET_HVC_FLAG_292:0, DET_MH_CRC16_289_292:0, DET_MH_CYCLE_COUNTER_289_292:0, DET_MH_SCAN_INDEX_4LSB_289_292:0, DET_OUTSIDE_SECTOR_289:0, DET_OUTSIDE_SECTOR_290:0, DET_OUTSIDE_SECTOR_291:0, DET_OUTSIDE_SECTOR_292:0, DET_POINT_TARGET_PROB_289:0, DET_POINT_TARGET_PROB_290:0, DET_POINT_TARGET_PROB_291:0, DET_POINT_TARGET_PROB_292:0, DET_RANGE_289:0, DET_RANGE_290:0, DET_RANGE_291:0, DET_RANGE_292:0, DET_RANGE_ERR_289:0, DET_RANGE_ERR_290:0, DET_RANGE_ERR_291:0, DET_RANGE_ERR_292:0, DET_RANGE_VELOCITY_289:16384, DET_RANGE_VELOCITY_290:16384, DET_RANGE_VELOCITY_291:16384, DET_RANGE_VELOCITY_292:16384, DET_RANGE_VELOCITY_ERR_289:0, DET_RANGE_VELOCITY_ERR_290:0, DET_RANGE_VELOCITY_ERR_291:0, DET_RANGE_VELOCITY_ERR_292:0, DET_RCS_289:128, DET_RCS_290:128, DET_RCS_291:128, DET_RCS_292:128, DET_SNR_289:0, DET_SNR_290:0, DET_SNR_291:0, DET_SNR_292:0, DET_SUPER_RES_TARGET_289:0, DET_SUPER_RES_TARGET_290:0, DET_SUPER_RES_TARGET_291:0, DET_SUPER_RES_TARGET_292:0, DET_VALID_FLAG_289:0, DET_VALID_FLAG_290:0, DET_VALID_FLAG_291:0, DET_VALID_FLAG_292:0]}, provided-interface=Pi_SG_Detections_289_292
      Pp_SG_Detections_293_296: nonqueued-sender-com-spec{data-element=Vdp_SG_Detections_293_296, init-value=fields=[DET_AZIMUTH_293:0, DET_AZIMUTH_294:0, DET_AZIMUTH_295:0, DET_AZIMUTH_296:0, DET_AZIMUTH_ERR_293:0, DET_AZIMUTH_ERR_294:0, DET_AZIMUTH_ERR_295:0, DET_AZIMUTH_ERR_296:0, DET_BI_STATIC_FLAG_293:0, DET_BI_STATIC_FLAG_294:0, DET_BI_STATIC_FLAG_295:0, DET_BI_STATIC_FLAG_296:0, DET_CONFD_AZIMUTH_293:0, DET_CONFD_AZIMUTH_294:0, DET_CONFD_AZIMUTH_295:0, DET_CONFD_AZIMUTH_296:0, DET_CONFD_ELEVATION_293:0, DET_CONFD_ELEVATION_294:0, DET_CONFD_ELEVATION_295:0, DET_CONFD_ELEVATION_296:0, DET_ELEVATION_293:0, DET_ELEVATION_294:0, DET_ELEVATION_295:0, DET_ELEVATION_296:0, DET_ELEVATION_ERR_293:0, DET_ELEVATION_ERR_294:0, DET_ELEVATION_ERR_295:0, DET_ELEVATION_ERR_296:0, DET_EXISTENCE_PROB_293:0, DET_EXISTENCE_PROB_294:0, DET_EXISTENCE_PROB_295:0, DET_EXISTENCE_PROB_296:0, DET_HVC_FLAG_293:0, DET_HVC_FLAG_294:0, DET_HVC_FLAG_295:0, DET_HVC_FLAG_296:0, DET_MH_CRC16_293_296:0, DET_MH_CYCLE_COUNTER_293_296:0, DET_MH_SCAN_INDEX_4LSB_293_296:0, DET_OUTSIDE_SECTOR_293:0, DET_OUTSIDE_SECTOR_294:0, DET_OUTSIDE_SECTOR_295:0, DET_OUTSIDE_SECTOR_296:0, DET_POINT_TARGET_PROB_293:0, DET_POINT_TARGET_PROB_294:0, DET_POINT_TARGET_PROB_295:0, DET_POINT_TARGET_PROB_296:0, DET_RANGE_293:0, DET_RANGE_294:0, DET_RANGE_295:0, DET_RANGE_296:0, DET_RANGE_ERR_293:0, DET_RANGE_ERR_294:0, DET_RANGE_ERR_295:0, DET_RANGE_ERR_296:0, DET_RANGE_VELOCITY_293:16384, DET_RANGE_VELOCITY_294:16384, DET_RANGE_VELOCITY_295:16384, DET_RANGE_VELOCITY_296:16384, DET_RANGE_VELOCITY_ERR_293:0, DET_RANGE_VELOCITY_ERR_294:0, DET_RANGE_VELOCITY_ERR_295:0, DET_RANGE_VELOCITY_ERR_296:0, DET_RCS_293:128, DET_RCS_294:128, DET_RCS_295:128, DET_RCS_296:128, DET_SNR_293:0, DET_SNR_294:0, DET_SNR_295:0, DET_SNR_296:0, DET_SUPER_RES_TARGET_293:0, DET_SUPER_RES_TARGET_294:0, DET_SUPER_RES_TARGET_295:0, DET_SUPER_RES_TARGET_296:0, DET_VALID_FLAG_293:0, DET_VALID_FLAG_294:0, DET_VALID_FLAG_295:0, DET_VALID_FLAG_296:0]}, provided-interface=Pi_SG_Detections_293_296
      Pp_SG_Detections_297_300: nonqueued-sender-com-spec{data-element=Vdp_SG_Detections_297_300, init-value=fields=[DET_AZIMUTH_297:0, DET_AZIMUTH_298:0, DET_AZIMUTH_299:0, DET_AZIMUTH_300:0, DET_AZIMUTH_ERR_297:0, DET_AZIMUTH_ERR_298:0, DET_AZIMUTH_ERR_299:0, DET_AZIMUTH_ERR_300:0, DET_BI_STATIC_FLAG_297:0, DET_BI_STATIC_FLAG_298:0, DET_BI_STATIC_FLAG_299:0, DET_BI_STATIC_FLAG_300:0, DET_CONFD_AZIMUTH_297:0, DET_CONFD_AZIMUTH_298:0, DET_CONFD_AZIMUTH_299:0, DET_CONFD_AZIMUTH_300:0, DET_CONFD_ELEVATION_297:0, DET_CONFD_ELEVATION_298:0, DET_CONFD_ELEVATION_299:0, DET_CONFD_ELEVATION_300:0, DET_ELEVATION_297:0, DET_ELEVATION_298:0, DET_ELEVATION_299:0, DET_ELEVATION_300:0, DET_ELEVATION_ERR_297:0, DET_ELEVATION_ERR_298:0, DET_ELEVATION_ERR_299:0, DET_ELEVATION_ERR_300:0, DET_EXISTENCE_PROB_297:0, DET_EXISTENCE_PROB_298:0, DET_EXISTENCE_PROB_299:0, DET_EXISTENCE_PROB_300:0, DET_HVC_FLAG_297:0, DET_HVC_FLAG_298:0, DET_HVC_FLAG_299:0, DET_HVC_FLAG_300:0, DET_MH_CRC16_297_300:0, DET_MH_CYCLE_COUNTER_297_300:0, DET_MH_SCAN_INDEX_4LSB_297_300:0, DET_OUTSIDE_SECTOR_297:0, DET_OUTSIDE_SECTOR_298:0, DET_OUTSIDE_SECTOR_299:0, DET_OUTSIDE_SECTOR_300:0, DET_POINT_TARGET_PROB_297:0, DET_POINT_TARGET_PROB_298:0, DET_POINT_TARGET_PROB_299:0, DET_POINT_TARGET_PROB_300:0, DET_RANGE_297:0, DET_RANGE_298:0, DET_RANGE_299:0, DET_RANGE_300:0, DET_RANGE_ERR_297:0, DET_RANGE_ERR_298:0, DET_RANGE_ERR_299:0, DET_RANGE_ERR_300:0, DET_RANGE_VELOCITY_297:16384, DET_RANGE_VELOCITY_298:16384, DET_RANGE_VELOCITY_299:16384, DET_RANGE_VELOCITY_300:16384, DET_RANGE_VELOCITY_ERR_297:0, DET_RANGE_VELOCITY_ERR_298:0, DET_RANGE_VELOCITY_ERR_299:0, DET_RANGE_VELOCITY_ERR_300:0, DET_RCS_297:128, DET_RCS_298:128, DET_RCS_299:128, DET_RCS_300:128, DET_SNR_297:0, DET_SNR_298:0, DET_SNR_299:0, DET_SNR_300:0, DET_SUPER_RES_TARGET_297:0, DET_SUPER_RES_TARGET_298:0, DET_SUPER_RES_TARGET_299:0, DET_SUPER_RES_TARGET_300:0, DET_VALID_FLAG_297:0, DET_VALID_FLAG_298:0, DET_VALID_FLAG_299:0, DET_VALID_FLAG_300:0]}, provided-interface=Pi_SG_Detections_297_300
      Pp_SG_Detections_301_304: nonqueued-sender-com-spec{data-element=Vdp_SG_Detections_301_304, init-value=fields=[DET_AZIMUTH_301:0, DET_AZIMUTH_302:0, DET_AZIMUTH_303:0, DET_AZIMUTH_304:0, DET_AZIMUTH_ERR_301:0, DET_AZIMUTH_ERR_302:0, DET_AZIMUTH_ERR_303:0, DET_AZIMUTH_ERR_304:0, DET_BI_STATIC_FLAG_301:0, DET_BI_STATIC_FLAG_302:0, DET_BI_STATIC_FLAG_303:0, DET_BI_STATIC_FLAG_304:0, DET_CONFD_AZIMUTH_301:0, DET_CONFD_AZIMUTH_302:0, DET_CONFD_AZIMUTH_303:0, DET_CONFD_AZIMUTH_304:0, DET_CONFD_ELEVATION_301:0, DET_CONFD_ELEVATION_302:0, DET_CONFD_ELEVATION_303:0, DET_CONFD_ELEVATION_304:0, DET_ELEVATION_301:0, DET_ELEVATION_302:0, DET_ELEVATION_303:0, DET_ELEVATION_304:0, DET_ELEVATION_ERR_301:0, DET_ELEVATION_ERR_302:0, DET_ELEVATION_ERR_303:0, DET_ELEVATION_ERR_304:0, DET_EXISTENCE_PROB_301:0, DET_EXISTENCE_PROB_302:0, DET_EXISTENCE_PROB_303:0, DET_EXISTENCE_PROB_304:0, DET_HVC_FLAG_301:0, DET_HVC_FLAG_302:0, DET_HVC_FLAG_303:0, DET_HVC_FLAG_304:0, DET_MH_CRC16_301_304:0, DET_MH_CYCLE_COUNTER_301_304:0, DET_MH_SCAN_INDEX_4LSB_301_304:0, DET_OUTSIDE_SECTOR_301:0, DET_OUTSIDE_SECTOR_302:0, DET_OUTSIDE_SECTOR_303:0, DET_OUTSIDE_SECTOR_304:0, DET_POINT_TARGET_PROB_301:0, DET_POINT_TARGET_PROB_302:0, DET_POINT_TARGET_PROB_303:0, DET_POINT_TARGET_PROB_304:0, DET_RANGE_301:0, DET_RANGE_302:0, DET_RANGE_303:0, DET_RANGE_304:0, DET_RANGE_ERR_301:0, DET_RANGE_ERR_302:0, DET_RANGE_ERR_303:0, DET_RANGE_ERR_304:0, DET_RANGE_VELOCITY_301:16384, DET_RANGE_VELOCITY_302:16384, DET_RANGE_VELOCITY_303:16384, DET_RANGE_VELOCITY_304:16384, DET_RANGE_VELOCITY_ERR_301:0, DET_RANGE_VELOCITY_ERR_302:0, DET_RANGE_VELOCITY_ERR_303:0, DET_RANGE_VELOCITY_ERR_304:0, DET_RCS_301:128, DET_RCS_302:128, DET_RCS_303:128, DET_RCS_304:128, DET_SNR_301:0, DET_SNR_302:0, DET_SNR_303:0, DET_SNR_304:0, DET_SUPER_RES_TARGET_301:0, DET_SUPER_RES_TARGET_302:0, DET_SUPER_RES_TARGET_303:0, DET_SUPER_RES_TARGET_304:0, DET_VALID_FLAG_301:0, DET_VALID_FLAG_302:0, DET_VALID_FLAG_303:0, DET_VALID_FLAG_304:0]}, provided-interface=Pi_SG_Detections_301_304
      Pp_SG_Detections_305_308: nonqueued-sender-com-spec{data-element=Vdp_SG_Detections_305_308, init-value=fields=[DET_AZIMUTH_305:0, DET_AZIMUTH_306:0, DET_AZIMUTH_307:0, DET_AZIMUTH_308:0, DET_AZIMUTH_ERR_305:0, DET_AZIMUTH_ERR_306:0, DET_AZIMUTH_ERR_307:0, DET_AZIMUTH_ERR_308:0, DET_BI_STATIC_FLAG_305:0, DET_BI_STATIC_FLAG_306:0, DET_BI_STATIC_FLAG_307:0, DET_BI_STATIC_FLAG_308:0, DET_CONFD_AZIMUTH_305:0, DET_CONFD_AZIMUTH_306:0, DET_CONFD_AZIMUTH_307:0, DET_CONFD_AZIMUTH_308:0, DET_CONFD_ELEVATION_305:0, DET_CONFD_ELEVATION_306:0, DET_CONFD_ELEVATION_307:0, DET_CONFD_ELEVATION_308:0, DET_ELEVATION_305:0, DET_ELEVATION_306:0, DET_ELEVATION_307:0, DET_ELEVATION_308:0, DET_ELEVATION_ERR_305:0, DET_ELEVATION_ERR_306:0, DET_ELEVATION_ERR_307:0, DET_ELEVATION_ERR_308:0, DET_EXISTENCE_PROB_305:0, DET_EXISTENCE_PROB_306:0, DET_EXISTENCE_PROB_307:0, DET_EXISTENCE_PROB_308:0, DET_HVC_FLAG_305:0, DET_HVC_FLAG_306:0, DET_HVC_FLAG_307:0, DET_HVC_FLAG_308:0, DET_MH_CRC16_305_308:0, DET_MH_CYCLE_COUNTER_305_308:0, DET_MH_SCAN_INDEX_4LSB_305_308:0, DET_OUTSIDE_SECTOR_305:0, DET_OUTSIDE_SECTOR_306:0, DET_OUTSIDE_SECTOR_307:0, DET_OUTSIDE_SECTOR_308:0, DET_POINT_TARGET_PROB_305:0, DET_POINT_TARGET_PROB_306:0, DET_POINT_TARGET_PROB_307:0, DET_POINT_TARGET_PROB_308:0, DET_RANGE_305:0, DET_RANGE_306:0, DET_RANGE_307:0, DET_RANGE_308:0, DET_RANGE_ERR_305:0, DET_RANGE_ERR_306:0, DET_RANGE_ERR_307:0, DET_RANGE_ERR_308:0, DET_RANGE_VELOCITY_305:16384, DET_RANGE_VELOCITY_306:16384, DET_RANGE_VELOCITY_307:16384, DET_RANGE_VELOCITY_308:16384, DET_RANGE_VELOCITY_ERR_305:0, DET_RANGE_VELOCITY_ERR_306:0, DET_RANGE_VELOCITY_ERR_307:0, DET_RANGE_VELOCITY_ERR_308:0, DET_RCS_305:128, DET_RCS_306:128, DET_RCS_307:128, DET_RCS_308:128, DET_SNR_305:0, DET_SNR_306:0, DET_SNR_307:0, DET_SNR_308:0, DET_SUPER_RES_TARGET_305:0, DET_SUPER_RES_TARGET_306:0, DET_SUPER_RES_TARGET_307:0, DET_SUPER_RES_TARGET_308:0, DET_VALID_FLAG_305:0, DET_VALID_FLAG_306:0, DET_VALID_FLAG_307:0, DET_VALID_FLAG_308:0]}, provided-interface=Pi_SG_Detections_305_308
      Pp_SG_Detections_309_312: nonqueued-sender-com-spec{data-element=Vdp_SG_Detections_309_312, init-value=fields=[DET_AZIMUTH_309:0, DET_AZIMUTH_310:0, DET_AZIMUTH_311:0, DET_AZIMUTH_312:0, DET_AZIMUTH_ERR_309:0, DET_AZIMUTH_ERR_310:0, DET_AZIMUTH_ERR_311:0, DET_AZIMUTH_ERR_312:0, DET_BI_STATIC_FLAG_309:0, DET_BI_STATIC_FLAG_310:0, DET_BI_STATIC_FLAG_311:0, DET_BI_STATIC_FLAG_312:0, DET_CONFD_AZIMUTH_309:0, DET_CONFD_AZIMUTH_310:0, DET_CONFD_AZIMUTH_311:0, DET_CONFD_AZIMUTH_312:0, DET_CONFD_ELEVATION_309:0, DET_CONFD_ELEVATION_310:0, DET_CONFD_ELEVATION_311:0, DET_CONFD_ELEVATION_312:0, DET_ELEVATION_309:0, DET_ELEVATION_310:0, DET_ELEVATION_311:0, DET_ELEVATION_312:0, DET_ELEVATION_ERR_309:0, DET_ELEVATION_ERR_310:0, DET_ELEVATION_ERR_311:0, DET_ELEVATION_ERR_312:0, DET_EXISTENCE_PROB_309:0, DET_EXISTENCE_PROB_310:0, DET_EXISTENCE_PROB_311:0, DET_EXISTENCE_PROB_312:0, DET_HVC_FLAG_309:0, DET_HVC_FLAG_310:0, DET_HVC_FLAG_311:0, DET_HVC_FLAG_312:0, DET_MH_CRC16_309_312:0, DET_MH_CYCLE_COUNTER_309_312:0, DET_MH_SCAN_INDEX_4LSB_309_312:0, DET_OUTSIDE_SECTOR_309:0, DET_OUTSIDE_SECTOR_310:0, DET_OUTSIDE_SECTOR_311:0, DET_OUTSIDE_SECTOR_312:0, DET_POINT_TARGET_PROB_309:0, DET_POINT_TARGET_PROB_310:0, DET_POINT_TARGET_PROB_311:0, DET_POINT_TARGET_PROB_312:0, DET_RANGE_309:0, DET_RANGE_310:0, DET_RANGE_311:0, DET_RANGE_312:0, DET_RANGE_ERR_309:0, DET_RANGE_ERR_310:0, DET_RANGE_ERR_311:0, DET_RANGE_ERR_312:0, DET_RANGE_VELOCITY_309:16384, DET_RANGE_VELOCITY_310:16384, DET_RANGE_VELOCITY_311:16384, DET_RANGE_VELOCITY_312:16384, DET_RANGE_VELOCITY_ERR_309:0, DET_RANGE_VELOCITY_ERR_310:0, DET_RANGE_VELOCITY_ERR_311:0, DET_RANGE_VELOCITY_ERR_312:0, DET_RCS_309:128, DET_RCS_310:128, DET_RCS_311:128, DET_RCS_312:128, DET_SNR_309:0, DET_SNR_310:0, DET_SNR_311:0, DET_SNR_312:0, DET_SUPER_RES_TARGET_309:0, DET_SUPER_RES_TARGET_310:0, DET_SUPER_RES_TARGET_311:0, DET_SUPER_RES_TARGET_312:0, DET_VALID_FLAG_309:0, DET_VALID_FLAG_310:0, DET_VALID_FLAG_311:0, DET_VALID_FLAG_312:0]}, provided-interface=Pi_SG_Detections_309_312
      Pp_SG_Detections_313_316: nonqueued-sender-com-spec{data-element=Vdp_SG_Detections_313_316, init-value=fields=[DET_AZIMUTH_313:0, DET_AZIMUTH_314:0, DET_AZIMUTH_315:0, DET_AZIMUTH_316:0, DET_AZIMUTH_ERR_313:0, DET_AZIMUTH_ERR_314:0, DET_AZIMUTH_ERR_315:0, DET_AZIMUTH_ERR_316:0, DET_BI_STATIC_FLAG_313:0, DET_BI_STATIC_FLAG_314:0, DET_BI_STATIC_FLAG_315:0, DET_BI_STATIC_FLAG_316:0, DET_CONFD_AZIMUTH_313:0, DET_CONFD_AZIMUTH_314:0, DET_CONFD_AZIMUTH_315:0, DET_CONFD_AZIMUTH_316:0, DET_CONFD_ELEVATION_313:0, DET_CONFD_ELEVATION_314:0, DET_CONFD_ELEVATION_315:0, DET_CONFD_ELEVATION_316:0, DET_ELEVATION_313:0, DET_ELEVATION_314:0, DET_ELEVATION_315:0, DET_ELEVATION_316:0, DET_ELEVATION_ERR_313:0, DET_ELEVATION_ERR_314:0, DET_ELEVATION_ERR_315:0, DET_ELEVATION_ERR_316:0, DET_EXISTENCE_PROB_313:0, DET_EXISTENCE_PROB_314:0, DET_EXISTENCE_PROB_315:0, DET_EXISTENCE_PROB_316:0, DET_HVC_FLAG_313:0, DET_HVC_FLAG_314:0, DET_HVC_FLAG_315:0, DET_HVC_FLAG_316:0, DET_MH_CRC16_313_316:0, DET_MH_CYCLE_COUNTER_313_316:0, DET_MH_SCAN_INDEX_4LSB_313_316:0, DET_OUTSIDE_SECTOR_313:0, DET_OUTSIDE_SECTOR_314:0, DET_OUTSIDE_SECTOR_315:0, DET_OUTSIDE_SECTOR_316:0, DET_POINT_TARGET_PROB_313:0, DET_POINT_TARGET_PROB_314:0, DET_POINT_TARGET_PROB_315:0, DET_POINT_TARGET_PROB_316:0, DET_RANGE_313:0, DET_RANGE_314:0, DET_RANGE_315:0, DET_RANGE_316:0, DET_RANGE_ERR_313:0, DET_RANGE_ERR_314:0, DET_RANGE_ERR_315:0, DET_RANGE_ERR_316:0, DET_RANGE_VELOCITY_313:16384, DET_RANGE_VELOCITY_314:16384, DET_RANGE_VELOCITY_315:16384, DET_RANGE_VELOCITY_316:16384, DET_RANGE_VELOCITY_ERR_313:0, DET_RANGE_VELOCITY_ERR_314:0, DET_RANGE_VELOCITY_ERR_315:0, DET_RANGE_VELOCITY_ERR_316:0, DET_RCS_313:128, DET_RCS_314:128, DET_RCS_315:128, DET_RCS_316:128, DET_SNR_313:0, DET_SNR_314:0, DET_SNR_315:0, DET_SNR_316:0, DET_SUPER_RES_TARGET_313:0, DET_SUPER_RES_TARGET_314:0, DET_SUPER_RES_TARGET_315:0, DET_SUPER_RES_TARGET_316:0, DET_VALID_FLAG_313:0, DET_VALID_FLAG_314:0, DET_VALID_FLAG_315:0, DET_VALID_FLAG_316:0]}, provided-interface=Pi_SG_Detections_313_316
      Pp_SG_Detections_317_320: nonqueued-sender-com-spec{data-element=Vdp_SG_Detections_317_320, init-value=fields=[DET_AZIMUTH_317:0, DET_AZIMUTH_318:0, DET_AZIMUTH_319:0, DET_AZIMUTH_320:0, DET_AZIMUTH_ERR_317:0, DET_AZIMUTH_ERR_318:0, DET_AZIMUTH_ERR_319:0, DET_AZIMUTH_ERR_320:0, DET_BI_STATIC_FLAG_317:0, DET_BI_STATIC_FLAG_318:0, DET_BI_STATIC_FLAG_319:0, DET_BI_STATIC_FLAG_320:0, DET_CONFD_AZIMUTH_317:0, DET_CONFD_AZIMUTH_318:0, DET_CONFD_AZIMUTH_319:0, DET_CONFD_AZIMUTH_320:0, DET_CONFD_ELEVATION_317:0, DET_CONFD_ELEVATION_318:0, DET_CONFD_ELEVATION_319:0, DET_CONFD_ELEVATION_320:0, DET_ELEVATION_317:0, DET_ELEVATION_318:0, DET_ELEVATION_319:0, DET_ELEVATION_320:0, DET_ELEVATION_ERR_317:0, DET_ELEVATION_ERR_318:0, DET_ELEVATION_ERR_319:0, DET_ELEVATION_ERR_320:0, DET_EXISTENCE_PROB_317:0, DET_EXISTENCE_PROB_318:0, DET_EXISTENCE_PROB_319:0, DET_EXISTENCE_PROB_320:0, DET_HVC_FLAG_317:0, DET_HVC_FLAG_318:0, DET_HVC_FLAG_319:0, DET_HVC_FLAG_320:0, DET_MH_CRC16_317_320:0, DET_MH_CYCLE_COUNTER_317_320:0, DET_MH_SCAN_INDEX_4LSB_317_320:0, DET_OUTSIDE_SECTOR_317:0, DET_OUTSIDE_SECTOR_318:0, DET_OUTSIDE_SECTOR_319:0, DET_OUTSIDE_SECTOR_320:0, DET_POINT_TARGET_PROB_317:0, DET_POINT_TARGET_PROB_318:0, DET_POINT_TARGET_PROB_319:0, DET_POINT_TARGET_PROB_320:0, DET_RANGE_317:0, DET_RANGE_318:0, DET_RANGE_319:0, DET_RANGE_320:0, DET_RANGE_ERR_317:0, DET_RANGE_ERR_318:0, DET_RANGE_ERR_319:0, DET_RANGE_ERR_320:0, DET_RANGE_VELOCITY_317:16384, DET_RANGE_VELOCITY_318:16384, DET_RANGE_VELOCITY_319:16384, DET_RANGE_VELOCITY_320:16384, DET_RANGE_VELOCITY_ERR_317:0, DET_RANGE_VELOCITY_ERR_318:0, DET_RANGE_VELOCITY_ERR_319:0, DET_RANGE_VELOCITY_ERR_320:0, DET_RCS_317:128, DET_RCS_318:128, DET_RCS_319:128, DET_RCS_320:128, DET_SNR_317:0, DET_SNR_318:0, DET_SNR_319:0, DET_SNR_320:0, DET_SUPER_RES_TARGET_317:0, DET_SUPER_RES_TARGET_318:0, DET_SUPER_RES_TARGET_319:0, DET_SUPER_RES_TARGET_320:0, DET_VALID_FLAG_317:0, DET_VALID_FLAG_318:0, DET_VALID_FLAG_319:0, DET_VALID_FLAG_320:0]}, provided-interface=Pi_SG_Detections_317_320
      Pp_SG_Detections_321_324: nonqueued-sender-com-spec{data-element=Vdp_SG_Detections_321_324, init-value=fields=[DET_AZIMUTH_321:0, DET_AZIMUTH_322:0, DET_AZIMUTH_323:0, DET_AZIMUTH_324:0, DET_AZIMUTH_ERR_321:0, DET_AZIMUTH_ERR_322:0, DET_AZIMUTH_ERR_323:0, DET_AZIMUTH_ERR_324:0, DET_BI_STATIC_FLAG_321:0, DET_BI_STATIC_FLAG_322:0, DET_BI_STATIC_FLAG_323:0, DET_BI_STATIC_FLAG_324:0, DET_CONFD_AZIMUTH_321:0, DET_CONFD_AZIMUTH_322:0, DET_CONFD_AZIMUTH_323:0, DET_CONFD_AZIMUTH_324:0, DET_CONFD_ELEVATION_321:0, DET_CONFD_ELEVATION_322:0, DET_CONFD_ELEVATION_323:0, DET_CONFD_ELEVATION_324:0, DET_ELEVATION_321:0, DET_ELEVATION_322:0, DET_ELEVATION_323:0, DET_ELEVATION_324:0, DET_ELEVATION_ERR_321:0, DET_ELEVATION_ERR_322:0, DET_ELEVATION_ERR_323:0, DET_ELEVATION_ERR_324:0, DET_EXISTENCE_PROB_321:0, DET_EXISTENCE_PROB_322:0, DET_EXISTENCE_PROB_323:0, DET_EXISTENCE_PROB_324:0, DET_HVC_FLAG_321:0, DET_HVC_FLAG_322:0, DET_HVC_FLAG_323:0, DET_HVC_FLAG_324:0, DET_MH_CRC16_321_324:0, DET_MH_CYCLE_COUNTER_321_324:0, DET_MH_SCAN_INDEX_4LSB_321_324:0, DET_OUTSIDE_SECTOR_321:0, DET_OUTSIDE_SECTOR_322:0, DET_OUTSIDE_SECTOR_323:0, DET_OUTSIDE_SECTOR_324:0, DET_POINT_TARGET_PROB_321:0, DET_POINT_TARGET_PROB_322:0, DET_POINT_TARGET_PROB_323:0, DET_POINT_TARGET_PROB_324:0, DET_RANGE_321:0, DET_RANGE_322:0, DET_RANGE_323:0, DET_RANGE_324:0, DET_RANGE_ERR_321:0, DET_RANGE_ERR_322:0, DET_RANGE_ERR_323:0, DET_RANGE_ERR_324:0, DET_RANGE_VELOCITY_321:16384, DET_RANGE_VELOCITY_322:16384, DET_RANGE_VELOCITY_323:16384, DET_RANGE_VELOCITY_324:16384, DET_RANGE_VELOCITY_ERR_321:0, DET_RANGE_VELOCITY_ERR_322:0, DET_RANGE_VELOCITY_ERR_323:0, DET_RANGE_VELOCITY_ERR_324:0, DET_RCS_321:128, DET_RCS_322:128, DET_RCS_323:128, DET_RCS_324:128, DET_SNR_321:0, DET_SNR_322:0, DET_SNR_323:0, DET_SNR_324:0, DET_SUPER_RES_TARGET_321:0, DET_SUPER_RES_TARGET_322:0, DET_SUPER_RES_TARGET_323:0, DET_SUPER_RES_TARGET_324:0, DET_VALID_FLAG_321:0, DET_VALID_FLAG_322:0, DET_VALID_FLAG_323:0, DET_VALID_FLAG_324:0]}, provided-interface=Pi_SG_Detections_321_324
      Pp_SG_Detections_325_328: nonqueued-sender-com-spec{data-element=Vdp_SG_Detections_325_328, init-value=fields=[DET_AZIMUTH_325:0, DET_AZIMUTH_326:0, DET_AZIMUTH_327:0, DET_AZIMUTH_328:0, DET_AZIMUTH_ERR_325:0, DET_AZIMUTH_ERR_326:0, DET_AZIMUTH_ERR_327:0, DET_AZIMUTH_ERR_328:0, DET_BI_STATIC_FLAG_325:0, DET_BI_STATIC_FLAG_326:0, DET_BI_STATIC_FLAG_327:0, DET_BI_STATIC_FLAG_328:0, DET_CONFD_AZIMUTH_325:0, DET_CONFD_AZIMUTH_326:0, DET_CONFD_AZIMUTH_327:0, DET_CONFD_AZIMUTH_328:0, DET_CONFD_ELEVATION_325:0, DET_CONFD_ELEVATION_326:0, DET_CONFD_ELEVATION_327:0, DET_CONFD_ELEVATION_328:0, DET_ELEVATION_325:0, DET_ELEVATION_326:0, DET_ELEVATION_327:0, DET_ELEVATION_328:0, DET_ELEVATION_ERR_325:0, DET_ELEVATION_ERR_326:0, DET_ELEVATION_ERR_327:0, DET_ELEVATION_ERR_328:0, DET_EXISTENCE_PROB_325:0, DET_EXISTENCE_PROB_326:0, DET_EXISTENCE_PROB_327:0, DET_EXISTENCE_PROB_328:0, DET_HVC_FLAG_325:0, DET_HVC_FLAG_326:0, DET_HVC_FLAG_327:0, DET_HVC_FLAG_328:0, DET_MH_CRC16_325_328:0, DET_MH_CYCLE_COUNTER_325_328:0, DET_MH_SCAN_INDEX_4LSB_325_328:0, DET_OUTSIDE_SECTOR_325:0, DET_OUTSIDE_SECTOR_326:0, DET_OUTSIDE_SECTOR_327:0, DET_OUTSIDE_SECTOR_328:0, DET_POINT_TARGET_PROB_325:0, DET_POINT_TARGET_PROB_326:0, DET_POINT_TARGET_PROB_327:0, DET_POINT_TARGET_PROB_328:0, DET_RANGE_325:0, DET_RANGE_326:0, DET_RANGE_327:0, DET_RANGE_328:0, DET_RANGE_ERR_325:0, DET_RANGE_ERR_326:0, DET_RANGE_ERR_327:0, DET_RANGE_ERR_328:0, DET_RANGE_VELOCITY_325:16384, DET_RANGE_VELOCITY_326:16384, DET_RANGE_VELOCITY_327:16384, DET_RANGE_VELOCITY_328:16384, DET_RANGE_VELOCITY_ERR_325:0, DET_RANGE_VELOCITY_ERR_326:0, DET_RANGE_VELOCITY_ERR_327:0, DET_RANGE_VELOCITY_ERR_328:0, DET_RCS_325:128, DET_RCS_326:128, DET_RCS_327:128, DET_RCS_328:128, DET_SNR_325:0, DET_SNR_326:0, DET_SNR_327:0, DET_SNR_328:0, DET_SUPER_RES_TARGET_325:0, DET_SUPER_RES_TARGET_326:0, DET_SUPER_RES_TARGET_327:0, DET_SUPER_RES_TARGET_328:0, DET_VALID_FLAG_325:0, DET_VALID_FLAG_326:0, DET_VALID_FLAG_327:0, DET_VALID_FLAG_328:0]}, provided-interface=Pi_SG_Detections_325_328
      Pp_SG_Detections_329_332: nonqueued-sender-com-spec{data-element=Vdp_SG_Detections_329_332, init-value=fields=[DET_AZIMUTH_329:0, DET_AZIMUTH_330:0, DET_AZIMUTH_331:0, DET_AZIMUTH_332:0, DET_AZIMUTH_ERR_329:0, DET_AZIMUTH_ERR_330:0, DET_AZIMUTH_ERR_331:0, DET_AZIMUTH_ERR_332:0, DET_BI_STATIC_FLAG_329:0, DET_BI_STATIC_FLAG_330:0, DET_BI_STATIC_FLAG_331:0, DET_BI_STATIC_FLAG_332:0, DET_CONFD_AZIMUTH_329:0, DET_CONFD_AZIMUTH_330:0, DET_CONFD_AZIMUTH_331:0, DET_CONFD_AZIMUTH_332:0, DET_CONFD_ELEVATION_329:0, DET_CONFD_ELEVATION_330:0, DET_CONFD_ELEVATION_331:0, DET_CONFD_ELEVATION_332:0, DET_ELEVATION_329:0, DET_ELEVATION_330:0, DET_ELEVATION_331:0, DET_ELEVATION_332:0, DET_ELEVATION_ERR_329:0, DET_ELEVATION_ERR_330:0, DET_ELEVATION_ERR_331:0, DET_ELEVATION_ERR_332:0, DET_EXISTENCE_PROB_329:0, DET_EXISTENCE_PROB_330:0, DET_EXISTENCE_PROB_331:0, DET_EXISTENCE_PROB_332:0, DET_HVC_FLAG_329:0, DET_HVC_FLAG_330:0, DET_HVC_FLAG_331:0, DET_HVC_FLAG_332:0, DET_MH_CRC16_329_332:0, DET_MH_CYCLE_COUNTER_329_332:0, DET_MH_SCAN_INDEX_4LSB_329_332:0, DET_OUTSIDE_SECTOR_329:0, DET_OUTSIDE_SECTOR_330:0, DET_OUTSIDE_SECTOR_331:0, DET_OUTSIDE_SECTOR_332:0, DET_POINT_TARGET_PROB_329:0, DET_POINT_TARGET_PROB_330:0, DET_POINT_TARGET_PROB_331:0, DET_POINT_TARGET_PROB_332:0, DET_RANGE_329:0, DET_RANGE_330:0, DET_RANGE_331:0, DET_RANGE_332:0, DET_RANGE_ERR_329:0, DET_RANGE_ERR_330:0, DET_RANGE_ERR_331:0, DET_RANGE_ERR_332:0, DET_RANGE_VELOCITY_329:16384, DET_RANGE_VELOCITY_330:16384, DET_RANGE_VELOCITY_331:16384, DET_RANGE_VELOCITY_332:16384, DET_RANGE_VELOCITY_ERR_329:0, DET_RANGE_VELOCITY_ERR_330:0, DET_RANGE_VELOCITY_ERR_331:0, DET_RANGE_VELOCITY_ERR_332:0, DET_RCS_329:128, DET_RCS_330:128, DET_RCS_331:128, DET_RCS_332:128, DET_SNR_329:0, DET_SNR_330:0, DET_SNR_331:0, DET_SNR_332:0, DET_SUPER_RES_TARGET_329:0, DET_SUPER_RES_TARGET_330:0, DET_SUPER_RES_TARGET_331:0, DET_SUPER_RES_TARGET_332:0, DET_VALID_FLAG_329:0, DET_VALID_FLAG_330:0, DET_VALID_FLAG_331:0, DET_VALID_FLAG_332:0]}, provided-interface=Pi_SG_Detections_329_332
      Pp_SG_Detections_333_336: nonqueued-sender-com-spec{data-element=Vdp_SG_Detections_333_336, init-value=fields=[DET_AZIMUTH_333:0, DET_AZIMUTH_334:0, DET_AZIMUTH_335:0, DET_AZIMUTH_336:0, DET_AZIMUTH_ERR_333:0, DET_AZIMUTH_ERR_334:0, DET_AZIMUTH_ERR_335:0, DET_AZIMUTH_ERR_336:0, DET_BI_STATIC_FLAG_333:0, DET_BI_STATIC_FLAG_334:0, DET_BI_STATIC_FLAG_335:0, DET_BI_STATIC_FLAG_336:0, DET_CONFD_AZIMUTH_333:0, DET_CONFD_AZIMUTH_334:0, DET_CONFD_AZIMUTH_335:0, DET_CONFD_AZIMUTH_336:0, DET_CONFD_ELEVATION_333:0, DET_CONFD_ELEVATION_334:0, DET_CONFD_ELEVATION_335:0, DET_CONFD_ELEVATION_336:0, DET_ELEVATION_333:0, DET_ELEVATION_334:0, DET_ELEVATION_335:0, DET_ELEVATION_336:0, DET_ELEVATION_ERR_333:0, DET_ELEVATION_ERR_334:0, DET_ELEVATION_ERR_335:0, DET_ELEVATION_ERR_336:0, DET_EXISTENCE_PROB_333:0, DET_EXISTENCE_PROB_334:0, DET_EXISTENCE_PROB_335:0, DET_EXISTENCE_PROB_336:0, DET_HVC_FLAG_333:0, DET_HVC_FLAG_334:0, DET_HVC_FLAG_335:0, DET_HVC_FLAG_336:0, DET_MH_CRC16_333_336:0, DET_MH_CYCLE_COUNTER_333_336:0, DET_MH_SCAN_INDEX_4LSB_333_336:0, DET_OUTSIDE_SECTOR_333:0, DET_OUTSIDE_SECTOR_334:0, DET_OUTSIDE_SECTOR_335:0, DET_OUTSIDE_SECTOR_336:0, DET_POINT_TARGET_PROB_333:0, DET_POINT_TARGET_PROB_334:0, DET_POINT_TARGET_PROB_335:0, DET_POINT_TARGET_PROB_336:0, DET_RANGE_333:0, DET_RANGE_334:0, DET_RANGE_335:0, DET_RANGE_336:0, DET_RANGE_ERR_333:0, DET_RANGE_ERR_334:0, DET_RANGE_ERR_335:0, DET_RANGE_ERR_336:0, DET_RANGE_VELOCITY_333:16384, DET_RANGE_VELOCITY_334:16384, DET_RANGE_VELOCITY_335:16384, DET_RANGE_VELOCITY_336:16384, DET_RANGE_VELOCITY_ERR_333:0, DET_RANGE_VELOCITY_ERR_334:0, DET_RANGE_VELOCITY_ERR_335:0, DET_RANGE_VELOCITY_ERR_336:0, DET_RCS_333:128, DET_RCS_334:128, DET_RCS_335:128, DET_RCS_336:128, DET_SNR_333:0, DET_SNR_334:0, DET_SNR_335:0, DET_SNR_336:0, DET_SUPER_RES_TARGET_333:0, DET_SUPER_RES_TARGET_334:0, DET_SUPER_RES_TARGET_335:0, DET_SUPER_RES_TARGET_336:0, DET_VALID_FLAG_333:0, DET_VALID_FLAG_334:0, DET_VALID_FLAG_335:0, DET_VALID_FLAG_336:0]}, provided-interface=Pi_SG_Detections_333_336
      Pp_SG_Detections_337_340: nonqueued-sender-com-spec{data-element=Vdp_SG_Detections_337_340, init-value=fields=[DET_AZIMUTH_337:0, DET_AZIMUTH_338:0, DET_AZIMUTH_339:0, DET_AZIMUTH_340:0, DET_AZIMUTH_ERR_337:0, DET_AZIMUTH_ERR_338:0, DET_AZIMUTH_ERR_339:0, DET_AZIMUTH_ERR_340:0, DET_BI_STATIC_FLAG_337:0, DET_BI_STATIC_FLAG_338:0, DET_BI_STATIC_FLAG_339:0, DET_BI_STATIC_FLAG_340:0, DET_CONFD_AZIMUTH_337:0, DET_CONFD_AZIMUTH_338:0, DET_CONFD_AZIMUTH_339:0, DET_CONFD_AZIMUTH_340:0, DET_CONFD_ELEVATION_337:0, DET_CONFD_ELEVATION_338:0, DET_CONFD_ELEVATION_339:0, DET_CONFD_ELEVATION_340:0, DET_ELEVATION_337:0, DET_ELEVATION_338:0, DET_ELEVATION_339:0, DET_ELEVATION_340:0, DET_ELEVATION_ERR_337:0, DET_ELEVATION_ERR_338:0, DET_ELEVATION_ERR_339:0, DET_ELEVATION_ERR_340:0, DET_EXISTENCE_PROB_337:0, DET_EXISTENCE_PROB_338:0, DET_EXISTENCE_PROB_339:0, DET_EXISTENCE_PROB_340:0, DET_HVC_FLAG_337:0, DET_HVC_FLAG_338:0, DET_HVC_FLAG_339:0, DET_HVC_FLAG_340:0, DET_MH_CRC16_337_340:0, DET_MH_CYCLE_COUNTER_337_340:0, DET_MH_SCAN_INDEX_4LSB_337_340:0, DET_OUTSIDE_SECTOR_337:0, DET_OUTSIDE_SECTOR_338:0, DET_OUTSIDE_SECTOR_339:0, DET_OUTSIDE_SECTOR_340:0, DET_POINT_TARGET_PROB_337:0, DET_POINT_TARGET_PROB_338:0, DET_POINT_TARGET_PROB_339:0, DET_POINT_TARGET_PROB_340:0, DET_RANGE_337:0, DET_RANGE_338:0, DET_RANGE_339:0, DET_RANGE_340:0, DET_RANGE_ERR_337:0, DET_RANGE_ERR_338:0, DET_RANGE_ERR_339:0, DET_RANGE_ERR_340:0, DET_RANGE_VELOCITY_337:16384, DET_RANGE_VELOCITY_338:16384, DET_RANGE_VELOCITY_339:16384, DET_RANGE_VELOCITY_340:16384, DET_RANGE_VELOCITY_ERR_337:0, DET_RANGE_VELOCITY_ERR_338:0, DET_RANGE_VELOCITY_ERR_339:0, DET_RANGE_VELOCITY_ERR_340:0, DET_RCS_337:128, DET_RCS_338:128, DET_RCS_339:128, DET_RCS_340:128, DET_SNR_337:0, DET_SNR_338:0, DET_SNR_339:0, DET_SNR_340:0, DET_SUPER_RES_TARGET_337:0, DET_SUPER_RES_TARGET_338:0, DET_SUPER_RES_TARGET_339:0, DET_SUPER_RES_TARGET_340:0, DET_VALID_FLAG_337:0, DET_VALID_FLAG_338:0, DET_VALID_FLAG_339:0, DET_VALID_FLAG_340:0]}, provided-interface=Pi_SG_Detections_337_340
      Pp_SG_Detections_341_344: nonqueued-sender-com-spec{data-element=Vdp_SG_Detections_341_344, init-value=fields=[DET_AZIMUTH_341:0, DET_AZIMUTH_342:0, DET_AZIMUTH_343:0, DET_AZIMUTH_344:0, DET_AZIMUTH_ERR_341:0, DET_AZIMUTH_ERR_342:0, DET_AZIMUTH_ERR_343:0, DET_AZIMUTH_ERR_344:0, DET_BI_STATIC_FLAG_341:0, DET_BI_STATIC_FLAG_342:0, DET_BI_STATIC_FLAG_343:0, DET_BI_STATIC_FLAG_344:0, DET_CONFD_AZIMUTH_341:0, DET_CONFD_AZIMUTH_342:0, DET_CONFD_AZIMUTH_343:0, DET_CONFD_AZIMUTH_344:0, DET_CONFD_ELEVATION_341:0, DET_CONFD_ELEVATION_342:0, DET_CONFD_ELEVATION_343:0, DET_CONFD_ELEVATION_344:0, DET_ELEVATION_341:0, DET_ELEVATION_342:0, DET_ELEVATION_343:0, DET_ELEVATION_344:0, DET_ELEVATION_ERR_341:0, DET_ELEVATION_ERR_342:0, DET_ELEVATION_ERR_343:0, DET_ELEVATION_ERR_344:0, DET_EXISTENCE_PROB_341:0, DET_EXISTENCE_PROB_342:0, DET_EXISTENCE_PROB_343:0, DET_EXISTENCE_PROB_344:0, DET_HVC_FLAG_341:0, DET_HVC_FLAG_342:0, DET_HVC_FLAG_343:0, DET_HVC_FLAG_344:0, DET_MH_CRC16_341_344:0, DET_MH_CYCLE_COUNTER_341_344:0, DET_MH_SCAN_INDEX_4LSB_341_344:0, DET_OUTSIDE_SECTOR_341:0, DET_OUTSIDE_SECTOR_342:0, DET_OUTSIDE_SECTOR_343:0, DET_OUTSIDE_SECTOR_344:0, DET_POINT_TARGET_PROB_341:0, DET_POINT_TARGET_PROB_342:0, DET_POINT_TARGET_PROB_343:0, DET_POINT_TARGET_PROB_344:0, DET_RANGE_341:0, DET_RANGE_342:0, DET_RANGE_343:0, DET_RANGE_344:0, DET_RANGE_ERR_341:0, DET_RANGE_ERR_342:0, DET_RANGE_ERR_343:0, DET_RANGE_ERR_344:0, DET_RANGE_VELOCITY_341:16384, DET_RANGE_VELOCITY_342:16384, DET_RANGE_VELOCITY_343:16384, DET_RANGE_VELOCITY_344:16384, DET_RANGE_VELOCITY_ERR_341:0, DET_RANGE_VELOCITY_ERR_342:0, DET_RANGE_VELOCITY_ERR_343:0, DET_RANGE_VELOCITY_ERR_344:0, DET_RCS_341:128, DET_RCS_342:128, DET_RCS_343:128, DET_RCS_344:128, DET_SNR_341:0, DET_SNR_342:0, DET_SNR_343:0, DET_SNR_344:0, DET_SUPER_RES_TARGET_341:0, DET_SUPER_RES_TARGET_342:0, DET_SUPER_RES_TARGET_343:0, DET_SUPER_RES_TARGET_344:0, DET_VALID_FLAG_341:0, DET_VALID_FLAG_342:0, DET_VALID_FLAG_343:0, DET_VALID_FLAG_344:0]}, provided-interface=Pi_SG_Detections_341_344
      Pp_SG_Detections_345_348: nonqueued-sender-com-spec{data-element=Vdp_SG_Detections_345_348, init-value=fields=[DET_AZIMUTH_345:0, DET_AZIMUTH_346:0, DET_AZIMUTH_347:0, DET_AZIMUTH_348:0, DET_AZIMUTH_ERR_345:0, DET_AZIMUTH_ERR_346:0, DET_AZIMUTH_ERR_347:0, DET_AZIMUTH_ERR_348:0, DET_BI_STATIC_FLAG_345:0, DET_BI_STATIC_FLAG_346:0, DET_BI_STATIC_FLAG_347:0, DET_BI_STATIC_FLAG_348:0, DET_CONFD_AZIMUTH_345:0, DET_CONFD_AZIMUTH_346:0, DET_CONFD_AZIMUTH_347:0, DET_CONFD_AZIMUTH_348:0, DET_CONFD_ELEVATION_345:0, DET_CONFD_ELEVATION_346:0, DET_CONFD_ELEVATION_347:0, DET_CONFD_ELEVATION_348:0, DET_ELEVATION_345:0, DET_ELEVATION_346:0, DET_ELEVATION_347:0, DET_ELEVATION_348:0, DET_ELEVATION_ERR_345:0, DET_ELEVATION_ERR_346:0, DET_ELEVATION_ERR_347:0, DET_ELEVATION_ERR_348:0, DET_EXISTENCE_PROB_345:0, DET_EXISTENCE_PROB_346:0, DET_EXISTENCE_PROB_347:0, DET_EXISTENCE_PROB_348:0, DET_HVC_FLAG_345:0, DET_HVC_FLAG_346:0, DET_HVC_FLAG_347:0, DET_HVC_FLAG_348:0, DET_MH_CRC16_345_348:0, DET_MH_CYCLE_COUNTER_345_348:0, DET_MH_SCAN_INDEX_4LSB_345_348:0, DET_OUTSIDE_SECTOR_345:0, DET_OUTSIDE_SECTOR_346:0, DET_OUTSIDE_SECTOR_347:0, DET_OUTSIDE_SECTOR_348:0, DET_POINT_TARGET_PROB_345:0, DET_POINT_TARGET_PROB_346:0, DET_POINT_TARGET_PROB_347:0, DET_POINT_TARGET_PROB_348:0, DET_RANGE_345:0, DET_RANGE_346:0, DET_RANGE_347:0, DET_RANGE_348:0, DET_RANGE_ERR_345:0, DET_RANGE_ERR_346:0, DET_RANGE_ERR_347:0, DET_RANGE_ERR_348:0, DET_RANGE_VELOCITY_345:16384, DET_RANGE_VELOCITY_346:16384, DET_RANGE_VELOCITY_347:16384, DET_RANGE_VELOCITY_348:16384, DET_RANGE_VELOCITY_ERR_345:0, DET_RANGE_VELOCITY_ERR_346:0, DET_RANGE_VELOCITY_ERR_347:0, DET_RANGE_VELOCITY_ERR_348:0, DET_RCS_345:128, DET_RCS_346:128, DET_RCS_347:128, DET_RCS_348:128, DET_SNR_345:0, DET_SNR_346:0, DET_SNR_347:0, DET_SNR_348:0, DET_SUPER_RES_TARGET_345:0, DET_SUPER_RES_TARGET_346:0, DET_SUPER_RES_TARGET_347:0, DET_SUPER_RES_TARGET_348:0, DET_VALID_FLAG_345:0, DET_VALID_FLAG_346:0, DET_VALID_FLAG_347:0, DET_VALID_FLAG_348:0]}, provided-interface=Pi_SG_Detections_345_348
      Pp_SG_Detections_349_352: nonqueued-sender-com-spec{data-element=Vdp_SG_Detections_349_352, init-value=fields=[DET_AZIMUTH_349:0, DET_AZIMUTH_350:0, DET_AZIMUTH_351:0, DET_AZIMUTH_352:0, DET_AZIMUTH_ERR_349:0, DET_AZIMUTH_ERR_350:0, DET_AZIMUTH_ERR_351:0, DET_AZIMUTH_ERR_352:0, DET_BI_STATIC_FLAG_349:0, DET_BI_STATIC_FLAG_350:0, DET_BI_STATIC_FLAG_351:0, DET_BI_STATIC_FLAG_352:0, DET_CONFD_AZIMUTH_349:0, DET_CONFD_AZIMUTH_350:0, DET_CONFD_AZIMUTH_351:0, DET_CONFD_AZIMUTH_352:0, DET_CONFD_ELEVATION_349:0, DET_CONFD_ELEVATION_350:0, DET_CONFD_ELEVATION_351:0, DET_CONFD_ELEVATION_352:0, DET_ELEVATION_349:0, DET_ELEVATION_350:0, DET_ELEVATION_351:0, DET_ELEVATION_352:0, DET_ELEVATION_ERR_349:0, DET_ELEVATION_ERR_350:0, DET_ELEVATION_ERR_351:0, DET_ELEVATION_ERR_352:0, DET_EXISTENCE_PROB_349:0, DET_EXISTENCE_PROB_350:0, DET_EXISTENCE_PROB_351:0, DET_EXISTENCE_PROB_352:0, DET_HVC_FLAG_349:0, DET_HVC_FLAG_350:0, DET_HVC_FLAG_351:0, DET_HVC_FLAG_352:0, DET_MH_CRC16_349_352:0, DET_MH_CYCLE_COUNTER_349_352:0, DET_MH_SCAN_INDEX_4LSB_349_352:0, DET_OUTSIDE_SECTOR_349:0, DET_OUTSIDE_SECTOR_350:0, DET_OUTSIDE_SECTOR_351:0, DET_OUTSIDE_SECTOR_352:0, DET_POINT_TARGET_PROB_349:0, DET_POINT_TARGET_PROB_350:0, DET_POINT_TARGET_PROB_351:0, DET_POINT_TARGET_PROB_352:0, DET_RANGE_349:0, DET_RANGE_350:0, DET_RANGE_351:0, DET_RANGE_352:0, DET_RANGE_ERR_349:0, DET_RANGE_ERR_350:0, DET_RANGE_ERR_351:0, DET_RANGE_ERR_352:0, DET_RANGE_VELOCITY_349:16384, DET_RANGE_VELOCITY_350:16384, DET_RANGE_VELOCITY_351:16384, DET_RANGE_VELOCITY_352:16384, DET_RANGE_VELOCITY_ERR_349:0, DET_RANGE_VELOCITY_ERR_350:0, DET_RANGE_VELOCITY_ERR_351:0, DET_RANGE_VELOCITY_ERR_352:0, DET_RCS_349:128, DET_RCS_350:128, DET_RCS_351:128, DET_RCS_352:128, DET_SNR_349:0, DET_SNR_350:0, DET_SNR_351:0, DET_SNR_352:0, DET_SUPER_RES_TARGET_349:0, DET_SUPER_RES_TARGET_350:0, DET_SUPER_RES_TARGET_351:0, DET_SUPER_RES_TARGET_352:0, DET_VALID_FLAG_349:0, DET_VALID_FLAG_350:0, DET_VALID_FLAG_351:0, DET_VALID_FLAG_352:0]}, provided-interface=Pi_SG_Detections_349_352
      Pp_SG_Detections_353_356: nonqueued-sender-com-spec{data-element=Vdp_SG_Detections_353_356, init-value=fields=[DET_AZIMUTH_353:0, DET_AZIMUTH_354:0, DET_AZIMUTH_355:0, DET_AZIMUTH_356:0, DET_AZIMUTH_ERR_353:0, DET_AZIMUTH_ERR_354:0, DET_AZIMUTH_ERR_355:0, DET_AZIMUTH_ERR_356:0, DET_BI_STATIC_FLAG_353:0, DET_BI_STATIC_FLAG_354:0, DET_BI_STATIC_FLAG_355:0, DET_BI_STATIC_FLAG_356:0, DET_CONFD_AZIMUTH_353:0, DET_CONFD_AZIMUTH_354:0, DET_CONFD_AZIMUTH_355:0, DET_CONFD_AZIMUTH_356:0, DET_CONFD_ELEVATION_353:0, DET_CONFD_ELEVATION_354:0, DET_CONFD_ELEVATION_355:0, DET_CONFD_ELEVATION_356:0, DET_ELEVATION_353:0, DET_ELEVATION_354:0, DET_ELEVATION_355:0, DET_ELEVATION_356:0, DET_ELEVATION_ERR_353:0, DET_ELEVATION_ERR_354:0, DET_ELEVATION_ERR_355:0, DET_ELEVATION_ERR_356:0, DET_EXISTENCE_PROB_353:0, DET_EXISTENCE_PROB_354:0, DET_EXISTENCE_PROB_355:0, DET_EXISTENCE_PROB_356:0, DET_HVC_FLAG_353:0, DET_HVC_FLAG_354:0, DET_HVC_FLAG_355:0, DET_HVC_FLAG_356:0, DET_MH_CRC16_353_356:0, DET_MH_CYCLE_COUNTER_353_356:0, DET_MH_SCAN_INDEX_4LSB_353_356:0, DET_OUTSIDE_SECTOR_353:0, DET_OUTSIDE_SECTOR_354:0, DET_OUTSIDE_SECTOR_355:0, DET_OUTSIDE_SECTOR_356:0, DET_POINT_TARGET_PROB_353:0, DET_POINT_TARGET_PROB_354:0, DET_POINT_TARGET_PROB_355:0, DET_POINT_TARGET_PROB_356:0, DET_RANGE_353:0, DET_RANGE_354:0, DET_RANGE_355:0, DET_RANGE_356:0, DET_RANGE_ERR_353:0, DET_RANGE_ERR_354:0, DET_RANGE_ERR_355:0, DET_RANGE_ERR_356:0, DET_RANGE_VELOCITY_353:16384, DET_RANGE_VELOCITY_354:16384, DET_RANGE_VELOCITY_355:16384, DET_RANGE_VELOCITY_356:16384, DET_RANGE_VELOCITY_ERR_353:0, DET_RANGE_VELOCITY_ERR_354:0, DET_RANGE_VELOCITY_ERR_355:0, DET_RANGE_VELOCITY_ERR_356:0, DET_RCS_353:128, DET_RCS_354:128, DET_RCS_355:128, DET_RCS_356:128, DET_SNR_353:0, DET_SNR_354:0, DET_SNR_355:0, DET_SNR_356:0, DET_SUPER_RES_TARGET_353:0, DET_SUPER_RES_TARGET_354:0, DET_SUPER_RES_TARGET_355:0, DET_SUPER_RES_TARGET_356:0, DET_VALID_FLAG_353:0, DET_VALID_FLAG_354:0, DET_VALID_FLAG_355:0, DET_VALID_FLAG_356:0]}, provided-interface=Pi_SG_Detections_353_356
      Pp_SG_Detections_357_360: nonqueued-sender-com-spec{data-element=Vdp_SG_Detections_357_360, init-value=fields=[DET_AZIMUTH_357:0, DET_AZIMUTH_358:0, DET_AZIMUTH_359:0, DET_AZIMUTH_360:0, DET_AZIMUTH_ERR_357:0, DET_AZIMUTH_ERR_358:0, DET_AZIMUTH_ERR_359:0, DET_AZIMUTH_ERR_360:0, DET_BI_STATIC_FLAG_357:0, DET_BI_STATIC_FLAG_358:0, DET_BI_STATIC_FLAG_359:0, DET_BI_STATIC_FLAG_360:0, DET_CONFD_AZIMUTH_357:0, DET_CONFD_AZIMUTH_358:0, DET_CONFD_AZIMUTH_359:0, DET_CONFD_AZIMUTH_360:0, DET_CONFD_ELEVATION_357:0, DET_CONFD_ELEVATION_358:0, DET_CONFD_ELEVATION_359:0, DET_CONFD_ELEVATION_360:0, DET_ELEVATION_357:0, DET_ELEVATION_358:0, DET_ELEVATION_359:0, DET_ELEVATION_360:0, DET_ELEVATION_ERR_357:0, DET_ELEVATION_ERR_358:0, DET_ELEVATION_ERR_359:0, DET_ELEVATION_ERR_360:0, DET_EXISTENCE_PROB_357:0, DET_EXISTENCE_PROB_358:0, DET_EXISTENCE_PROB_359:0, DET_EXISTENCE_PROB_360:0, DET_HVC_FLAG_357:0, DET_HVC_FLAG_358:0, DET_HVC_FLAG_359:0, DET_HVC_FLAG_360:0, DET_MH_CRC16_357_360:0, DET_MH_CYCLE_COUNTER_357_360:0, DET_MH_SCAN_INDEX_4LSB_357_360:0, DET_OUTSIDE_SECTOR_357:0, DET_OUTSIDE_SECTOR_358:0, DET_OUTSIDE_SECTOR_359:0, DET_OUTSIDE_SECTOR_360:0, DET_POINT_TARGET_PROB_357:0, DET_POINT_TARGET_PROB_358:0, DET_POINT_TARGET_PROB_359:0, DET_POINT_TARGET_PROB_360:0, DET_RANGE_357:0, DET_RANGE_358:0, DET_RANGE_359:0, DET_RANGE_360:0, DET_RANGE_ERR_357:0, DET_RANGE_ERR_358:0, DET_RANGE_ERR_359:0, DET_RANGE_ERR_360:0, DET_RANGE_VELOCITY_357:16384, DET_RANGE_VELOCITY_358:16384, DET_RANGE_VELOCITY_359:16384, DET_RANGE_VELOCITY_360:16384, DET_RANGE_VELOCITY_ERR_357:0, DET_RANGE_VELOCITY_ERR_358:0, DET_RANGE_VELOCITY_ERR_359:0, DET_RANGE_VELOCITY_ERR_360:0, DET_RCS_357:128, DET_RCS_358:128, DET_RCS_359:128, DET_RCS_360:128, DET_SNR_357:0, DET_SNR_358:0, DET_SNR_359:0, DET_SNR_360:0, DET_SUPER_RES_TARGET_357:0, DET_SUPER_RES_TARGET_358:0, DET_SUPER_RES_TARGET_359:0, DET_SUPER_RES_TARGET_360:0, DET_VALID_FLAG_357:0, DET_VALID_FLAG_358:0, DET_VALID_FLAG_359:0, DET_VALID_FLAG_360:0]}, provided-interface=Pi_SG_Detections_357_360
